AUTOSAR XML (schema 4-2-1)
# Copyright (c) 2017 Vector Informatik GmbH.
# License is restricted to the usage with CBD1800319 (D00) for MSR_Vector_SLP4.
# Please contact Vector Informatik whenever you need further information concerning the license conditions.
standard types defined: boolean, sint16, uint16, uint32, uint8
package /VehicleProject
  system System
package /TP
  lin tp config LIN00: communication-cluster=LIN00
    tp address TA_0x0001: tp-address=1
    tp address TA_0x0003: tp-address=3
    tp address TA_0x007E: tp-address=126
    tp-connections:
      data-pdu=MasterReq_Tp_oLIN00, lin-tp-n-sdu=MasterReq_oLIN00, multicast=TA_0x007E, receiver=[TN_0x0001_SRU3, TN_0x0003_LRU1], transmitter=TN_Master
      data-pdu=SlaveResp_Tp_oLIN00, flow-control=MasterReq_Tp_oLIN00, lin-tp-n-sdu=SlaveResp_SRU3_oLIN00, receiver=TN_Master, transmitter=TN_0x0001_SRU3
      data-pdu=SlaveResp_Tp_oLIN00, flow-control=MasterReq_Tp_oLIN00, lin-tp-n-sdu=SlaveResp_LRU1_oLIN00, receiver=TN_Master, transmitter=TN_0x0003_LRU1
      data-pdu=MasterReq_Tp_oLIN00, flow-control=SlaveResp_Tp_oLIN00, lin-tp-n-sdu=MasterReq_SRU3_oLIN00, receiver=TN_0x0001_SRU3, transmitter=TN_Master
      data-pdu=MasterReq_Tp_oLIN00, flow-control=SlaveResp_Tp_oLIN00, lin-tp-n-sdu=MasterReq_LRU1_oLIN00, receiver=TN_0x0003_LRU1, transmitter=TN_Master
    lin tp node TN_0x0001_SRU3: tp-address=TA_0x0001
    lin tp node TN_0x0003_LRU1: tp-address=TA_0x0003
    lin tp node TN_Master: connector=CN_LIN00
package /Cluster
  can cluster CAN00: protocol-name=CAN  # 180319-lh1-EP21P2P_P2P_CAN2-V09
    can physical channel CHNL: comm-connectors=CN_CAN00
      frame DIAG_DTCInfo_P2P_oCAN00: id 0x79E, from P2P, frame-length=7, can-addressing-mode=STANDARD
        pdu DIAG_DTCInfo_P2P_oCAN00: length=7, unused-bit-pattern=0
          signal DTCInfomationP2PHSC2_oDIAG_DTCInfo_P2P_oCAN00: start 0, 56 bit, opaque, init-value=7 x 0, base-type=uint8_7_iso_8859_1, compu {0..72057594037927935=RANGE}, transfer-property=PENDING  # DTC Infomation of P2P The length of DTC information signal is 7 bytes. Byte 0 is MSB (most significant byte), and Byte 6 is LSB (least significant byte). For each byte, Bit 7 is msb (most significant bit), and Bit 0 is lsb (least significant bit). Byte 0: Bit (7-4): DTC Serious Level Bit (3-0): Reserved Byte 1: Bit (7-0): Reserved Byte 2: Bit (7-0): DTCHighByte Byte 3: Bit (7-0): DTCLowByte Byte 4: Bit (7-0): DTCFailureTypeByte Byte 5: Bit 7: warningIndicatorRequested Bit 6: testNotCompletedThisOperationCycle Bit 5: testFailedSinceLastClear Bit 4: testNotCompletedSinceLastClear Bit 3: confirmedDTC Bit 2: pendingDTC Bit 1: testFailedThisOperationCycle Bit 0: testFailed Byte 6: Bit (7-0): DTC Type For more detail, please refer to SMTC 2 800 004.
      frame DIAG_FuncReq_HSC2_oCAN00: id 0x7DF, to P2P, frame-length=8, can-addressing-mode=STANDARD
        pdu DIAG_FuncReq_HSC2_oCAN00: length=8, unused-bit-pattern=0
          signal DiagnosticFuncAddrReq_h2_oDIAG_FuncReq_HSC2_oCAN00: start 0, 64 bit, opaque, init-value=8 x 0, base-type=uint8_8_iso_8859_1, compu {0..18446744073709551615=RANGE}, transfer-property=PENDING, to P2P  # Diagnostic functional address request
      frame DIAG_PhysReq_P2P_oCAN00: id 0x736, to P2P, frame-length=8, can-addressing-mode=STANDARD
        pdu DIAG_PhysReq_P2P_oCAN00: length=8, unused-bit-pattern=0
          signal DiagnosticReqP2P_h2_oDIAG_PhysReq_P2P_oCAN00: start 0, 64 bit, opaque, init-value=8 x 0, base-type=uint8_8_iso_8859_1, compu {0..18446744073709551615=RANGE}, transfer-property=PENDING, to P2P  # Diagnostic request to P2P
      frame DIAG_PhysResp_P2P_oCAN00: id 0x73E, from P2P, frame-length=8, can-addressing-mode=STANDARD
        pdu DIAG_PhysResp_P2P_oCAN00: length=8, unused-bit-pattern=0
          signal DiagnosticRespP2P_oDIAG_PhysResp_P2P_oCAN00: start 0, 64 bit, opaque, init-value=8 x 0, base-type=uint8_8_iso_8859_1, compu {0..18446744073709551615=RANGE}, transfer-property=PENDING  # Diagnostic response from P2P
      frame EHBS_HSC2_FrP00_oCAN00: id 0x1B6, to P2P, frame-length=8, can-addressing-mode=STANDARD
        pdu EHBS_HSC2_FrP00_oCAN00: length=8, transmission-mode-false-timing=cyclic-timing=time-period=0, transmission-mode-true-timing=cyclic-timing=time-period=0, unused-bit-pattern=0
          signal BrkPdlAppdHSC2_oEHBS_HSC2_FrP00_oCAN00: start 10, 1 bit, big-endian, init-value=0, base-type=boolean, compu {0..1=RANGE, 0=Cx0_brake_pedal_not_applied (brake pedal not applied), 1=Cx1_brake_pedal_applied (brake pedal applied)}, transfer-property=PENDING, to P2P
          signal HydBstrCmpstnReqHSC2_oEHBS_HSC2_FrP00_oCAN00: start 54, 1 bit, big-endian, init-value=0, base-type=boolean, compu {0..1=RANGE, 0=Cx0_HBC_inactive (HBC inactive), 1=Cx1_HBC_active (HBC active)}, transfer-property=PENDING, to P2P
      frame EPB_HSC2_FrP00_oCAN00: id 0x230, to P2P, frame-length=8, can-addressing-mode=STANDARD
        pdu EPB_HSC2_FrP00_oCAN00: length=8, transmission-mode-false-timing=cyclic-timing=time-period=0, transmission-mode-true-timing=cyclic-timing=time-period=0, unused-bit-pattern=0
          signal EPBSwStsVHSC2_oEPB_HSC2_FrP00_oCAN00: start 5, 1 bit, big-endian, init-value=0, base-type=boolean, compu {0..1=RANGE, 0=Cx0_Valid, 1=Cx1_Invalid}, transfer-property=PENDING, to P2P
          signal EPBSwStsHSC2_oEPB_HSC2_FrP00_oCAN00: start 7, 2 bit, big-endian, init-value=0, base-type=uint8, compu {0..3=RANGE, 0=Cx0_NotActive, 1=Cx1_Release, 2=Cx2_Apply}, transfer-property=PENDING, to P2P
      frame EPB_HSC2_FrP01_oCAN00: id 0x22A, to P2P, frame-length=2, can-addressing-mode=STANDARD
        pdu EPB_HSC2_FrP01_oCAN00: length=2, transmission-mode-false-timing=cyclic-timing=time-period=0, transmission-mode-true-timing=cyclic-timing=time-period=0, unused-bit-pattern=0
          signal EPBAvlblyStsPVHSC2_oEPB_HSC2_FrP01_oCAN00: start 2, 3 bit, big-endian, init-value=0, base-type=uint8, compu {0..7=RANGE, 0=Cx0_0x0_0x7_ ((0x0 - 0x7))}, transfer-property=PENDING, to P2P
          signal EPBAvlblyStsHSC2_oEPB_HSC2_FrP01_oCAN00: start 5, 3 bit, big-endian, init-value=0, base-type=uint8, compu {0..7=RANGE, 0=Cx0_Unavailable_Not_Failed (Unavailable,Not Failed), 1=Cx1_Available_Not_Failed (Available,Not Failed), 2=Cx2_Unavailable_Failed_Applied (Unavailable,Failed Applied), 3=Cx3_Unavailable_Failed_Released (Unavailable,Failed Released), 4=Cx4_Unavailable_Failed_other (Unavailable,Failed other)}, transfer-property=PENDING, to P2P
          signal EPBAppcnStsPVHSC2_oEPB_HSC2_FrP01_oCAN00: start 13, 2 bit, big-endian, init-value=0, base-type=uint8, compu {0..3=RANGE, 0=Cx0_0x0_0x3_ ((0x0 - 0x3))}, transfer-property=PENDING, to P2P  # Electric Park Brake Application Status Protection Value
          signal EPBAppcnStsHSC2_oEPB_HSC2_FrP01_oCAN00: start 15, 2 bit, big-endian, init-value=0, base-type=uint8, compu {0..3=RANGE, 0=Cx0_Unknown, 1=Cx1_Park_Brake_Applied (Park Brake Applied), 2=Cx2_Park_Brake_Released (Park Brake Released), 3=Cx3_Park_Brake_Application_in_Progress (Park Brake Application in Progress)}, transfer-property=PENDING, to P2P  # Electric Park Brake Application Status
      frame EPS_HSC2_FrP02_oCAN00: id 0x1B1, to P2P, frame-length=4, can-addressing-mode=STANDARD
        pdu EPS_HSC2_FrP02_oCAN00: length=4, transmission-mode-false-timing=cyclic-timing=time-period=0, transmission-mode-true-timing=cyclic-timing=time-period=0, unused-bit-pattern=0
          signal EPSAPAStsHSC2_oEPS_HSC2_FrP02_oCAN00: start 4, 4 bit, big-endian, init-value=7, base-type=uint8, compu {0..15=RANGE, 0=Cx0_Inhibit, 1=Cx1_Available, 2=Cx2_Active, 3=Cx3_Abort, 4=Cx4_Reply_for_Control (Reply for Control), 5=Cx5_NRCD_Active (NRCD Active), 6=Cx6_ADAS_Active (ADAS Active), 7=Cx7_Failure, 8=Cx8_Reserve_0x8_0xF_ (Reserve (0x8 - 0xF)); unit Reserve} "Source signal range: [8,15]", unit=Reserve, transfer-property=PENDING, to P2P
          signal EPSAPAInhHSC2_oEPS_HSC2_FrP02_oCAN00: start 15, 8 bit, big-endian, init-value=0, base-type=uint8, compu {0..255=RANGE, 0=Cx00_Normal_Operation (Normal Operation), 1=Cx01_Over_Speed (Over Speed), 2=Cx02_Driver_Interference (Driver Interference), 4=Cx04_Abnormal_CAN_input (Abnormal CAN input), 8=Cx08_Excess_Angle_Deviation (Excess Angle Deviation), 16=Cx10_EPS_failure (EPS failure), 32=Cx20_Reserve, 64=Cx40_Reserve, 128=Cx80_Reserve}, transfer-property=PENDING, to P2P
          signal EPSAPAAlvRCHSC2_oEPS_HSC2_FrP02_oCAN00: start 23, 8 bit, big-endian, init-value=0, base-type=uint8, compu {0..255=RANGE, 0=Cx00_0x0_0xFF_ ((0x0 - 0xFF))}, transfer-property=PENDING, to P2P
          signal EPSAPAChksmHSC2_oEPS_HSC2_FrP02_oCAN00: start 31, 8 bit, big-endian, init-value=0, base-type=uint8, compu {0..255=RANGE, 0=Cx00_0x0_0xFF_ ((0x0 - 0xFF))}, transfer-property=PENDING, to P2P
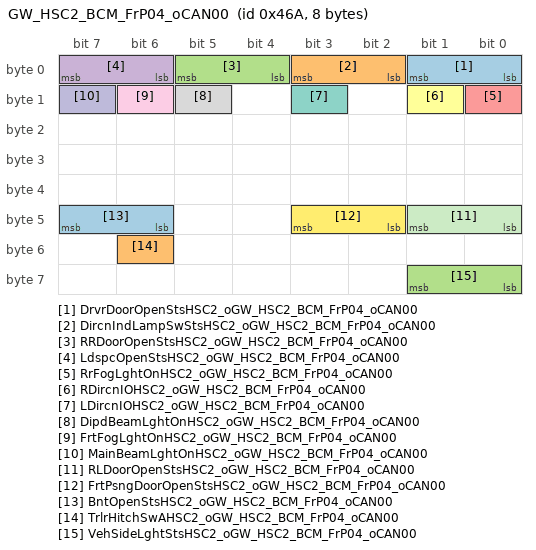
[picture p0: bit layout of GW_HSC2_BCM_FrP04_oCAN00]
      frame GW_HSC2_BCM_FrP04_oCAN00: id 0x46A, to P2P, frame-length=8, can-addressing-mode=STANDARD
        pdu GW_HSC2_BCM_FrP04_oCAN00: length=8, transmission-mode-false-timing=cyclic-timing=time-period=0, transmission-mode-true-timing=cyclic-timing=time-period=0, unused-bit-pattern=0
          signal DrvrDoorOpenStsHSC2_oGW_HSC2_BCM_FrP04_oCAN00: start 1, 2 bit, big-endian, init-value=0, base-type=uint8, compu {0..3=RANGE, 0=Cx0_Driver_Door_Closed (Driver Door Closed), 1=Cx1_Driver_Door_Open_For_latch_switch_can_t_detect_door_ajar_status_ (Driver Door Open(For latch switch can't detect door ajar status)), 2=Cx2_Driver_Door_Ajar (Driver Door Ajar), 3=Cx3_Driver_Door_Full_Open (Driver Door Full Open)}, transfer-property=PENDING, to P2P
          signal DircnIndLampSwStsHSC2_oGW_HSC2_BCM_FrP04_oCAN00: start 3, 2 bit, big-endian, init-value=0, base-type=uint8, compu {0..3=RANGE, 0=Cx0_off, 1=Cx1_Left_on (Left on), 2=Cx2_Right_on (Right on), 3=Cx3_reserve}, transfer-property=PENDING, to P2P
          signal RRDoorOpenStsHSC2_oGW_HSC2_BCM_FrP04_oCAN00: start 5, 2 bit, big-endian, init-value=0, base-type=uint8, compu {0..3=RANGE, 0=Cx0_Rear_Right_Door_Closed (Rear Right Door Closed), 1=Cx1_Rear_Right_Door_Open_latch_switch_cann_t_detect_door_ajar_status (Rear Right Door Open(latch switch cann't detect door ajar status), 2=Cx2_Rear_Right_Door_Ajar (Rear Right Door Ajar), 3=Cx3_Rear_Right_Door_Full_Open (Rear Right Door Full Open)}, transfer-property=PENDING, to P2P  # Rear Right Door Open Status
          signal LdspcOpenStsHSC2_oGW_HSC2_BCM_FrP04_oCAN00: start 7, 2 bit, big-endian, init-value=0, base-type=uint8, compu {0..3=RANGE, 0=Cx0_Load_Space_Closed (Load Space Closed), 1=Cx1_Load_Space_Open (Load Space Open), 2=Cx2_Reserved, 3=Cx3_Reserved}, transfer-property=PENDING, to P2P
          signal RrFogLghtOnHSC2_oGW_HSC2_BCM_FrP04_oCAN00: start 8, 1 bit, big-endian, init-value=0, base-type=boolean, compu {0..1=RANGE, 0=Cx0_False, 1=Cx1_True}, transfer-property=PENDING, to P2P
          signal RDircnIOHSC2_oGW_HSC2_BCM_FrP04_oCAN00: start 9, 1 bit, big-endian, init-value=0, base-type=boolean, compu {0..1=RANGE, 0=Cx0_False, 1=Cx1_True}, transfer-property=PENDING, to P2P
          signal LDircnIOHSC2_oGW_HSC2_BCM_FrP04_oCAN00: start 11, 1 bit, big-endian, init-value=0, base-type=boolean, compu {0..1=RANGE, 0=Cx0_False, 1=Cx1_True}, transfer-property=PENDING, to P2P
          signal DipdBeamLghtOnHSC2_oGW_HSC2_BCM_FrP04_oCAN00: start 13, 1 bit, big-endian, init-value=0, base-type=boolean, compu {0..1=RANGE, 0=Cx0_False, 1=Cx1_True}, transfer-property=PENDING, to P2P
          signal FrtFogLghtOnHSC2_oGW_HSC2_BCM_FrP04_oCAN00: start 14, 1 bit, big-endian, init-value=0, base-type=boolean, compu {0..1=RANGE, 0=Cx0_False, 1=Cx1_True}, transfer-property=PENDING, to P2P
          signal MainBeamLghtOnHSC2_oGW_HSC2_BCM_FrP04_oCAN00: start 15, 1 bit, big-endian, init-value=0, base-type=boolean, compu {0..1=RANGE, 0=Cx0_False, 1=Cx1_True}, transfer-property=PENDING, to P2P
          signal RLDoorOpenStsHSC2_oGW_HSC2_BCM_FrP04_oCAN00: start 41, 2 bit, big-endian, init-value=0, base-type=uint8, compu {0..3=RANGE, 0=Cx0_Rear_Left_Door_Closed (Rear Left Door Closed), 1=Cx1_Rear_Left_Door_Open_latch_switch_cann_t_detect_door_ajar_status (Rear Left Door Open(latch switch cann't detect door ajar status), 2=Cx2_Rear_Left_Door_Ajar (Rear Left Door Ajar), 3=Cx3_Rear_Left_Door_Full_Open (Rear Left Door Full Open)}, transfer-property=PENDING, to P2P
          signal FrtPsngDoorOpenStsHSC2_oGW_HSC2_BCM_FrP04_oCAN00: start 43, 2 bit, big-endian, init-value=0, base-type=uint8, compu {0..3=RANGE, 0=Cx0_Front_Passenger_Door_Closed (Front Passenger Door Closed), 1=Cx1_Front_Passenger_Open_latch_switch_cann_t_detect_door_ajar_statu (Front Passenger Open(latch switch cann¡®t detect door ajar statu), 2=Cx2_Front_Passenger_Door_Ajar (Front Passenger Door Ajar), 3=Cx3_Front_Passenger_Door_Full_Open (Front Passenger Door Full Open)}, transfer-property=PENDING, to P2P
          signal BntOpenStsHSC2_oGW_HSC2_BCM_FrP04_oCAN00: start 47, 2 bit, big-endian, init-value=0, base-type=uint8, compu {0..3=RANGE, 0=Cx0_Bonnet_Closed (Bonnet Closed), 1=Cx1_Bonnet_Open (Bonnet Open), 2=Cx2_Bonnet_Switch_Disconnect (Bonnet Switch Disconnect), 3=Cx3_Reserved}, transfer-property=PENDING, to P2P
          signal TrlrHitchSwAHSC2_oGW_HSC2_BCM_FrP04_oCAN00: start 54, 1 bit, big-endian, init-value=0, base-type=boolean, compu {0..1=RANGE, 0=Cx0_False, 1=Cx1_True}, transfer-property=PENDING, to P2P
          signal VehSideLghtStsHSC2_oGW_HSC2_BCM_FrP04_oCAN00: start 57, 2 bit, big-endian, init-value=0, base-type=uint8, compu {0..3=RANGE, 0=Cx0_No_side_light_on_ (No side light on), 1=Cx1_Left_side_light_on_only (Left side light on only), 2=Cx2_Right_side_light_on_only (Right side light on only), 3=Cx3_All_side_light_and_license_plate_light_on (All side light and license plate light on)}, transfer-property=PENDING, to P2P
      frame GW_HSC2_BCM_FrP06_oCAN00: id 0x21C, to P2P, frame-length=8, can-addressing-mode=STANDARD
        pdu GW_HSC2_BCM_FrP06_oCAN00: length=8, transmission-mode-false-timing=cyclic-timing=time-period=0, transmission-mode-true-timing=cyclic-timing=time-period=0, unused-bit-pattern=0
          signal BCMSSBFltStsHSC2_oGW_HSC2_BCM_FrP06_oCAN00: start 7, 3 bit, big-endian, init-value=0, base-type=uint8, compu {0..7=RANGE, 0=Cx0_No_Fault (No Fault), 1=Cx1_short_to_GND (short to GND), 2=Cx2_short_to_Battery (short to Battery), 3=Cx3_Stuck, 4=Cx4_Open_Circuit (Open Circuit), 5=Cx5_switch_failed (switch failed), 6=Cx6_Reserved, 7=Cx7_Reserved}, transfer-property=PENDING, to P2P
          signal DayTimeRunningLampOnHSC2_oGW_HSC2_BCM_FrP06_oCAN00: start 29, 1 bit, big-endian, init-value=0, base-type=boolean, compu {0..1=RANGE, 0=Cx0_False, 1=Cx1_True}, transfer-property=PENDING, to P2P
      frame GW_HSC2_BCM_FrP07_oCAN00: id 0x1F2, to P2P, frame-length=2, can-addressing-mode=STANDARD
        pdu GW_HSC2_BCM_FrP07_oCAN00: length=2, transmission-mode-false-timing=cyclic-timing=time-period=0, transmission-mode-true-timing=cyclic-timing=time-period=0, unused-bit-pattern=0
          signal BCMSSBAHSC2_oGW_HSC2_BCM_FrP07_oCAN00: start 0, 1 bit, big-endian, init-value=0, base-type=boolean, compu {0..1=RANGE, 0=Cx0_Inactive, 1=Cx1_Active_}, transfer-property=PENDING, to P2P
          signal BCMSSBAVHSC2_oGW_HSC2_BCM_FrP07_oCAN00: start 1, 1 bit, big-endian, init-value=0, base-type=boolean, compu {0..1=RANGE, 0=Cx0_Valid, 1=Cx1_Invalid}, transfer-property=PENDING, to P2P
          signal PwrMdAutoCtrlAvlblHSC2_oGW_HSC2_BCM_FrP07_oCAN00: start 2, 1 bit, big-endian, init-value=0, base-type=boolean, compu {0..1=RANGE, 0=Cx0_unavailable, 1=Cx1_available}, transfer-property=PENDING, to P2P
          signal SysBPMHSC2_oGW_HSC2_BCM_FrP07_oCAN00: start 5, 2 bit, big-endian, init-value=0, base-type=uint8, compu {0..3=RANGE, 0=Cx0_Off, 1=Cx1_ACC, 2=Cx2_Run, 3=Cx3_Crank_Request (Crank Request)}, transfer-property=PENDING, to P2P
          signal SysBPMEnbdHSC2_oGW_HSC2_BCM_FrP07_oCAN00: start 6, 1 bit, big-endian, init-value=0, base-type=boolean, compu {0..1=RANGE, 0=Cx0_False, 1=Cx1_True}, transfer-property=PENDING, to P2P
      frame GW_HSC2_BCM_FrS16_oCAN00: id 0x603, to P2P, frame-length=8, can-addressing-mode=STANDARD
        pdu GW_HSC2_BCM_FrS16_oCAN00: length=8, unused-bit-pattern=0
          signal BCMToIECURmtCtrlPotclHSC2_oGW_HSC2_BCM_FrS16_oCAN00: start 0, 64 bit, opaque, init-value=8 x 0, base-type=uint8_8_iso_8859_1, compu {0..18446744073709551615=RANGE}, transfer-property=PENDING, to P2P
      frame GW_HSC2_ECM_FrP04_oCAN00: id 0x194, to P2P, frame-length=8, can-addressing-mode=STANDARD
        pdu GW_HSC2_ECM_FrP04_oCAN00: length=8, transmission-mode-false-timing=cyclic-timing=time-period=0, transmission-mode-true-timing=cyclic-timing=time-period=0, unused-bit-pattern=0
          signal TrShftLvrPos_h1HSC2_oGW_HSC2_ECM_FrP04_oCAN00: start 27, 4 bit, big-endian, init-value=0, base-type=uint8, compu {0..15=RANGE, 0=Cx0_Between_Ranges (Between Ranges), 1=Cx1_Park_Range (Park Range), 2=Cx2_Reverse_Range (Reverse Range), 3=Cx3_Neutral_Range (Neutral Range), 4=Cx4_Forward_Range_A (Forward Range A), 5=Cx5_Forward_Range_B (Forward Range B), 6=Cx6_Forward_Range_C (Forward Range C), 7=Cx7_Forward_Range_D (Forward Range D), 8=Cx8_Forward_Range_E (Forward Range E), 9=Cx9_Forward_Range_F (Forward Range F), 10=CxA_Forward_Range_G (Forward Range G), 11=CxB_Forward_Range_H (Forward Range H), 15=CxF_Lever_Position_Unknown (Lever Position Unknown)}, transfer-property=PENDING, to P2P
          signal TrShftLvrPosV_h1HSC2_oGW_HSC2_ECM_FrP04_oCAN00: start 28, 1 bit, big-endian, init-value=0, base-type=boolean, compu {0..1=RANGE, 0=Cx0_Valid, 1=Cx1_Invalid}, transfer-property=PENDING, to P2P
      frame GW_HSC2_FICM_FrP02_oCAN00: id 0x376, to P2P, frame-length=8, can-addressing-mode=STANDARD
        pdu GW_HSC2_FICM_FrP02_oCAN00: length=8, transmission-mode-false-timing=cyclic-timing=time-period=0, transmission-mode-true-timing=cyclic-timing=time-period=0, unused-bit-pattern=0
          signal DrvrSelAPAParkngMdHSC2_oGW_HSC2_FICM_FrP02_oCAN00: start 10, 3 bit, big-endian, init-value=0, base-type=uint8, compu {0..7=RANGE, 0=Cx0_No_select (No select), 1=Cx1_Select_parallel_parking (Select parallel parking), 2=Cx2_Select_perpendicular_parking (Select perpendicular parking), 3=Cx3_Select_park_in (Select park in), 4=Cx4_Select_park_out (Select park out), 5=Cx5_Reserved, 6=Cx6_Reserved, 7=Cx7_Reserved}, transfer-property=PENDING, to P2P  # Driver Select Advanced Park Assist Parking Mode
          signal DrvrSelAPASlotBearngHSC2_oGW_HSC2_FICM_FrP02_oCAN00: start 12, 2 bit, big-endian, init-value=0, base-type=uint8, compu {0..3=RANGE, 0=Cx0_No_select (No select), 1=Cx1_Select_Left_slot (Select Left slot), 2=Cx2_Select_Right_slot (Select Right slot), 3=Cx3_Reserved}, transfer-property=PENDING, to P2P
          signal RstrFctryDeftsReqHSC2_oGW_HSC2_FICM_FrP02_oCAN00: start 56, 1 bit, big-endian, init-value=0, base-type=boolean, compu {0..1=RANGE, 0=Cx0_False, 1=Cx1_True}, transfer-property=PENDING, to P2P
      frame GW_HSC2_FICM_FrP08_oCAN00: id 0x2F6, to P2P, frame-length=8, can-addressing-mode=STANDARD
        pdu GW_HSC2_FICM_FrP08_oCAN00: length=8, transmission-mode-false-timing=cyclic-timing=time-period=0, transmission-mode-true-timing=cyclic-timing=time-period=0, unused-bit-pattern=0
          signal APASwReqHSC2_oGW_HSC2_FICM_FrP08_oCAN00: start 59, 2 bit, big-endian, init-value=0, base-type=uint8, compu {0..3=RANGE, 0=Cx0_No_request (No request), 1=Cx1_Short_press (Short press), 2=Cx2_Long_press (Long press), 3=Cx3_Reserved}, transfer-property=PENDING, to P2P
          signal PDCSwReqHSC2_oGW_HSC2_FICM_FrP08_oCAN00: start 61, 2 bit, big-endian, init-value=0, base-type=uint8, compu {0..3=RANGE, 0=Cx0_No_request (No request), 1=Cx1_Short_press (Short press), 2=Cx2_Long_press (Long press), 3=Cx3_Reserved}, transfer-property=PENDING, to P2P
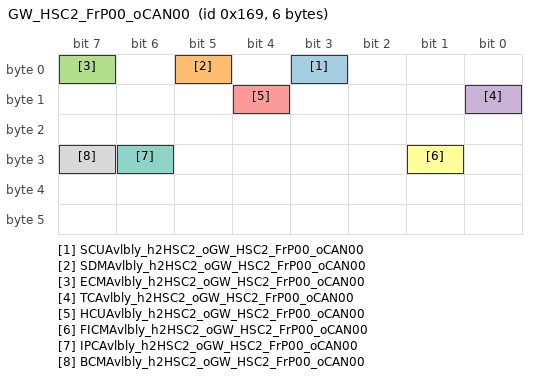
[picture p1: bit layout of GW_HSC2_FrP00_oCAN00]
      frame GW_HSC2_FrP00_oCAN00: id 0x169, to P2P, frame-length=6, can-addressing-mode=STANDARD
        pdu GW_HSC2_FrP00_oCAN00: length=6, transmission-mode-false-timing=cyclic-timing=time-period=0, transmission-mode-true-timing=cyclic-timing=time-period=0, unused-bit-pattern=0
          signal SCUAvlbly_h2HSC2_oGW_HSC2_FrP00_oCAN00: start 3, 1 bit, big-endian, init-value=0, base-type=boolean, compu {0..1=RANGE, 0=Cx0_False, 1=Cx1_True}, transfer-property=PENDING, to P2P
          signal SDMAvlbly_h2HSC2_oGW_HSC2_FrP00_oCAN00: start 5, 1 bit, big-endian, init-value=0, base-type=boolean, compu {0..1=RANGE, 0=Cx0_False, 1=Cx1_True}, transfer-property=PENDING, to P2P
          signal ECMAvlbly_h2HSC2_oGW_HSC2_FrP00_oCAN00: start 7, 1 bit, big-endian, init-value=0, base-type=boolean, compu {0..1=RANGE, 0=Cx0_False, 1=Cx1_True}, transfer-property=PENDING, to P2P
          signal TCAvlbly_h2HSC2_oGW_HSC2_FrP00_oCAN00: start 8, 1 bit, big-endian, init-value=0, base-type=boolean, compu {0..1=RANGE, 0=Cx0_False, 1=Cx1_True}, transfer-property=PENDING, to P2P  # TC Available Detect if specific ECU is available according to node missing strategy by gateway ECU.
          signal HCUAvlbly_h2HSC2_oGW_HSC2_FrP00_oCAN00: start 12, 1 bit, big-endian, init-value=0, base-type=boolean, compu {0..1=RANGE, 0=Cx0_False, 1=Cx1_True}, transfer-property=PENDING, to P2P  # HCU Available Detect if specific ECU is available according to node missing strategy by gateway ECU.
          signal FICMAvlbly_h2HSC2_oGW_HSC2_FrP00_oCAN00: start 25, 1 bit, big-endian, init-value=0, base-type=boolean, compu {0..1=RANGE, 0=Cx0_False, 1=Cx1_True}, transfer-property=PENDING, to P2P
          signal IPCAvlbly_h2HSC2_oGW_HSC2_FrP00_oCAN00: start 30, 1 bit, big-endian, init-value=0, base-type=boolean, compu {0..1=RANGE, 0=Cx0_False, 1=Cx1_True}, transfer-property=PENDING, to P2P
          signal BCMAvlbly_h2HSC2_oGW_HSC2_FrP00_oCAN00: start 31, 1 bit, big-endian, init-value=0, base-type=boolean, compu {0..1=RANGE, 0=Cx0_False, 1=Cx1_True}, transfer-property=PENDING, to P2P
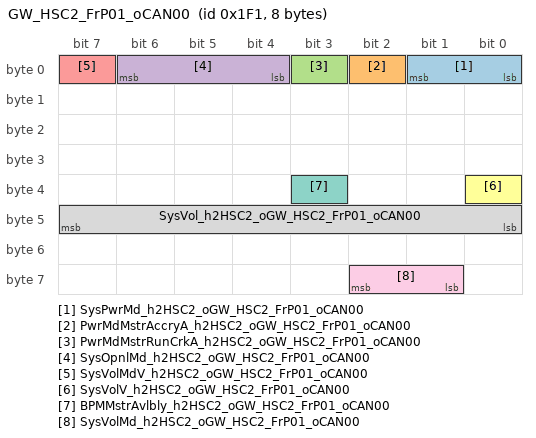
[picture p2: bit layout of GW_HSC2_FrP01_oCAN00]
      frame GW_HSC2_FrP01_oCAN00: id 0x1F1, to P2P, frame-length=8, can-addressing-mode=STANDARD
        pdu GW_HSC2_FrP01_oCAN00: length=8, transmission-mode-false-timing=cyclic-timing=time-period=0, transmission-mode-true-timing=cyclic-timing=time-period=0, unused-bit-pattern=0
          signal SysPwrMd_h2HSC2_oGW_HSC2_FrP01_oCAN00: start 1, 2 bit, big-endian, init-value=0, base-type=uint8, compu {0..3=RANGE, 0=Cx0_Off, 1=Cx1_Accessory, 2=Cx2_Run, 3=Cx3_Crank_Request (Crank Request)}, transfer-property=PENDING, to P2P
          signal PwrMdMstrAccryA_h2HSC2_oGW_HSC2_FrP01_oCAN00: start 2, 1 bit, big-endian, init-value=0, base-type=boolean, compu {0..1=RANGE, 0=Cx0_Inactive, 1=Cx1_Active}, transfer-property=PENDING, to P2P
          signal PwrMdMstrRunCrkA_h2HSC2_oGW_HSC2_FrP01_oCAN00: start 3, 1 bit, big-endian, init-value=0, base-type=boolean, compu {0..1=RANGE, 0=Cx0_Inactive, 1=Cx1_Active}, transfer-property=PENDING, to P2P
          signal SysOpnlMd_h2HSC2_oGW_HSC2_FrP01_oCAN00: start 6, 3 bit, big-endian, init-value=0, base-type=uint8, compu {0..7=RANGE, 0=Cx0_Normal_Mode (Normal Mode), 1=Cx1_Manufacturing_Mode (Manufacturing Mode), 2=Cx2_Transit_Mode (Transit Mode), 3=Cx3_Show_Room_Reserve_ (Show Room(Reserve)), 4=Cx4_Storage_Mode (Storage Mode), 5=Cx5_Diagnosic_or_Reprogramming_Reserve_ (Diagnosic or Reprogramming(Reserve))}, transfer-property=PENDING, to P2P
          signal SysVolMdV_h2HSC2_oGW_HSC2_FrP01_oCAN00: start 7, 1 bit, big-endian, init-value=0, base-type=boolean, compu {0..1=RANGE, 0=Cx0_Valid, 1=Cx1_Invalid}, transfer-property=PENDING, to P2P
          signal SysVolV_h2HSC2_oGW_HSC2_FrP01_oCAN00: start 32, 1 bit, big-endian, init-value=0, base-type=boolean, compu {0..1=RANGE, 0=Cx0_Valid, 1=Cx1_Invalid}, transfer-property=PENDING, to P2P
          signal BPMMstrAvlbly_h2HSC2_oGW_HSC2_FrP01_oCAN00: start 35, 1 bit, big-endian, init-value=0, base-type=boolean, compu {0..1=RANGE, 0=Cx0_False, 1=Cx1_True}, transfer-property=PENDING, to P2P
          signal SysVol_h2HSC2_oGW_HSC2_FrP01_oCAN00: start 47, 8 bit, big-endian, init-value=0, base-type=uint8, compu {0=Cx00_V_0x0_0xFF_ (V (0x0 - 0xFF)), phys=raw*0.1+3 for raw 0..255; unit V}, unit=V, transfer-property=PENDING, to P2P
          signal SysVolMd_h2HSC2_oGW_HSC2_FrP01_oCAN00: start 58, 2 bit, big-endian, init-value=0, base-type=uint8, compu {0..3=RANGE, 0=Cx0_Normal, 1=Cx1_Low_System_Voltage (Low System Voltage), 2=Cx2_High_System_Voltage (High System Voltage), 3=Cx3_Illegal_System_Voltage (Illegal System Voltage)}, transfer-property=PENDING, to P2P
      frame GW_HSC2_FrP08_oCAN00: id 0x540, to P2P, frame-length=8, can-addressing-mode=STANDARD
        pdu GW_HSC2_FrP08_oCAN00: length=8, transmission-mode-false-timing=cyclic-timing=time-period=0, transmission-mode-true-timing=cyclic-timing=time-period=0, unused-bit-pattern=0
          signal VehOdo_h2HSC2_oGW_HSC2_FrP08_oCAN00: start 7, 24 bit, big-endian, init-value=0, base-type=uint32, compu {0..16777200=RANGE, 0=Cx000000_0x0_0xFFFFFF_ ((0x0 - 0xFFFFFF))}, transfer-property=PENDING, to P2P
          signal VehOdoV_h2HSC2_oGW_HSC2_FrP08_oCAN00: start 31, 1 bit, big-endian, init-value=0, base-type=boolean, compu {0..1=RANGE, 0=Cx0_Valid, 1=Cx1_Invalid}, transfer-property=PENDING, to P2P
      frame GW_HSC2_FrP10_oCAN00: id 0x3F1, to P2P, frame-length=8, can-addressing-mode=STANDARD
        pdu GW_HSC2_FrP10_oCAN00: length=8, transmission-mode-false-timing=cyclic-timing=time-period=0, transmission-mode-true-timing=cyclic-timing=time-period=0, unused-bit-pattern=0
          signal OtsdAirTemCrValV_h2HSC2_oGW_HSC2_FrP10_oCAN00: start 48, 1 bit, big-endian, init-value=0, base-type=boolean, compu {0..1=RANGE, 0=Cx0_Valid, 1=Cx1_Invalid}, transfer-property=PENDING, to P2P
          signal OtsdAirTemCrValMsk_h2HSC2_oGW_HSC2_FrP10_oCAN00: start 51, 1 bit, big-endian, init-value=0, base-type=boolean, compu {0..1=RANGE, 0=Cx0_Don_t_Use_Data (Don't Use Data), 1=Cx1_Use_Data (Use Data)}, transfer-property=PENDING, to P2P
          signal OtsdAirTemCrVal_h2HSC2_oGW_HSC2_FrP10_oCAN00: start 63, 8 bit, big-endian, init-value=0, base-type=uint8, compu {0=Cx00_degC_0x0_0xFF_ (degC (0x0 - 0xFF)), phys=raw*0.5-40 for raw 0..255; unit degC}, unit=degC, transfer-property=PENDING, to P2P
      frame GW_HSC2_FrP13_oCAN00: id 0x1A9, to P2P, frame-length=8, can-addressing-mode=STANDARD
        pdu GW_HSC2_FrP13_oCAN00: length=8, transmission-mode-false-timing=cyclic-timing=time-period=0, transmission-mode-true-timing=cyclic-timing=time-period=0, unused-bit-pattern=0
          signal NRCDSts_h2HSC2_oGW_HSC2_FrP13_oCAN00: start 39, 2 bit, big-endian, init-value=0, base-type=uint8, compu {0..3=RANGE, 0=Cx0_Inactive, 1=Cx1_NRCD_Active (NRCD Active), 2=Cx2_Semiautomatic_Parking_Assistant_Active (Semiautomatic Parking Assistant Active), 3=Cx3_Fully_APA_Active (Fully-APA Active)}, transfer-property=PENDING, to P2P
          signal APACtrlAbotdRsnHSC2_oGW_HSC2_FrP13_oCAN00: start 47, 4 bit, big-endian, init-value=0, base-type=uint8, compu {0..15=RANGE, 0=Cx0_No_Aborted (No Aborted), 1=Cx1_Driver_interference_SCU (Driver interference SCU), 2=Cx2_Driver_interference_Braking_System (Driver interference Braking System), 3=Cx3_Charger_is_connected (Charger is connected), 4=Cx4_Communication_Error (Communication Error), 5=Cx5_In_post_collision (In post collision), 6=Cx6_Energy_Low (Energy Low), 7=Cx7_Gradient_over_threshold (Gradient over threshold), 8=Cx8_Crank_Failed (Crank Failed), 9=Cx9_Reserve, 10=CxA_Reserve, 11=CxB_Reserve, 12=CxC_Reserve, 13=CxD_Reserve, 14=CxE_Reserve, 15=CxF_Unknown_Reason (Unknown Reason)}, transfer-property=PENDING, to P2P
      frame GW_HSC2_FrS00_oCAN00: id 0x6A3, to P2P, frame-length=8, can-addressing-mode=STANDARD
        pdu GW_HSC2_FrS00_oCAN00: length=8, unused-bit-pattern=0
          signal NRCDMstrChlg_h2HSC2_oGW_HSC2_FrS00_oCAN00: start 0, 64 bit, opaque, init-value=8 x 0, base-type=uint8_8_iso_8859_1, compu {0=RANGE, 0=Cx0000000000000000_0x0_0xFFFFFFFF_ ((0x0 - 0xFFFFFFFF))}, transfer-property=PENDING, to P2P
      frame GW_HSC2_HCU_FrP00_oCAN00: id 0xAF, to P2P, frame-length=8, can-addressing-mode=STANDARD
        pdu GW_HSC2_HCU_FrP00_oCAN00: length=8, transmission-mode-false-timing=cyclic-timing=time-period=0, transmission-mode-true-timing=cyclic-timing=time-period=0, unused-bit-pattern=0
          signal EPTAccelActuPosHSC2_oGW_HSC2_HCU_FrP00_oCAN00: start 7, 8 bit, big-endian, init-value=0, base-type=uint8, compu {0=Cx00_0x0_0xFF_ (% (0x0 - 0xFF)), phys=raw*0.392157 for raw 0..254; unit %}, unit=%, transfer-property=PENDING, to P2P
          signal EPTBrkPdlDscrtInptStsVHSC2_oGW_HSC2_HCU_FrP00_oCAN00: start 16, 1 bit, big-endian, init-value=1, base-type=boolean, compu {0..1=RANGE, 0=Cx0_Valid, 1=Cx1_Invalid}, transfer-property=PENDING, to P2P  # Electric Powertrain Brake Pedal Discrete Input Status Validity
          signal EPTStCmdOn_h1HSC2_oGW_HSC2_HCU_FrP00_oCAN00: start 17, 1 bit, big-endian, init-value=0, base-type=boolean, compu {0..1=RANGE, 0=Cx0_False, 1=Cx1_True}, transfer-property=PENDING, to P2P
          signal EPTBrkPdlDscrtInptStsHSC2_oGW_HSC2_HCU_FrP00_oCAN00: start 31, 1 bit, big-endian, init-value=0, base-type=boolean, compu {0..1=RANGE, 0=Cx0_Brake_Not_Applied (Brake Not Applied), 1=Cx1_Brake_Applied (Brake Applied)}, transfer-property=PENDING, to P2P
          signal EPTAccelActuPosVHSC2_oGW_HSC2_HCU_FrP00_oCAN00: start 43, 1 bit, big-endian, init-value=0, base-type=boolean, compu {0..1=RANGE, 0=Cx0_Valid, 1=Cx1_Invalid}, transfer-property=PENDING, to P2P
      frame GW_HSC2_HCU_FrP01_oCAN00: id 0x196, to P2P, frame-length=8, can-addressing-mode=STANDARD
        pdu GW_HSC2_HCU_FrP01_oCAN00: length=8, transmission-mode-false-timing=cyclic-timing=time-period=0, transmission-mode-true-timing=cyclic-timing=time-period=0, unused-bit-pattern=0
          signal EPTRdy_h1HSC2_oGW_HSC2_HCU_FrP01_oCAN00: start 38, 1 bit, big-endian, init-value=0, base-type=boolean, compu {0..1=RANGE, 0=Cx0_Not_ready (Not ready), 1=Cx1_Ready}, transfer-property=PENDING, to P2P
      frame GW_HSC2_HCU_FrP13_oCAN00: id 0x19C, to P2P, frame-length=8, can-addressing-mode=STANDARD
        pdu GW_HSC2_HCU_FrP13_oCAN00: length=8, transmission-mode-false-timing=cyclic-timing=time-period=0, transmission-mode-true-timing=cyclic-timing=time-period=0, unused-bit-pattern=0
          signal VCUNRCDAvlblHSC2_oGW_HSC2_HCU_FrP13_oCAN00: start 52, 1 bit, big-endian, init-value=0, base-type=boolean, compu {0..1=RANGE, 0=Cx0_Unavailable, 1=Cx1_Available}, transfer-property=PENDING, to P2P
          signal VCUAccReqStsHSC2_oGW_HSC2_HCU_FrP13_oCAN00: start 53, 1 bit, big-endian, init-value=0, base-type=boolean, compu {0..1=RANGE, 0=Cx0_No_Request (No Request), 1=Cx1_Request}, transfer-property=PENDING, to P2P
          signal VCUAccReqValHSC2_oGW_HSC2_HCU_FrP13_oCAN00: start 63, 8 bit, big-endian, init-value=0, base-type=uint8, compu {0=Cx00_0x0_0xFF_ ((0x0 - 0xFF)), phys=raw*0.1-12.7 for raw 0..255}, transfer-property=PENDING, to P2P
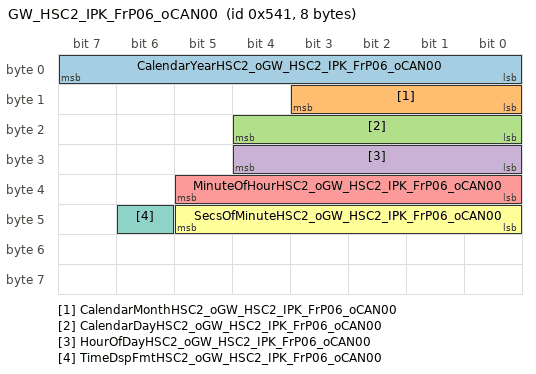
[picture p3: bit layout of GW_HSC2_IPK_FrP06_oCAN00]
      frame GW_HSC2_IPK_FrP06_oCAN00: id 0x541, to P2P, frame-length=8, can-addressing-mode=STANDARD
        pdu GW_HSC2_IPK_FrP06_oCAN00: length=8, transmission-mode-false-timing=cyclic-timing=time-period=0, transmission-mode-true-timing=cyclic-timing=time-period=0, unused-bit-pattern=0
          signal CalendarYearHSC2_oGW_HSC2_IPK_FrP06_oCAN00: start 7, 8 bit, big-endian, init-value=0, base-type=uint8, compu {0=Cx00_year_0x0_0xFF_ (year (0x0 - 0xFF)), phys=raw+2000 for raw 0..255; unit year}, unit=year, transfer-property=PENDING, to P2P
          signal CalendarMonthHSC2_oGW_HSC2_IPK_FrP06_oCAN00: start 11, 4 bit, big-endian, init-value=0, base-type=uint8, compu {0..15=RANGE, 0=Cx0_Unknown, 1=Cx1_January, 2=Cx2_February, 3=Cx3_March, 4=Cx4_April, 5=Cx5_May, 6=Cx6_June, 7=Cx7_July, 8=Cx8_August, 9=Cx9_September, 10=CxA_October, 11=CxB_November, 12=CxC_December}, transfer-property=PENDING, to P2P
          signal CalendarDayHSC2_oGW_HSC2_IPK_FrP06_oCAN00: start 20, 5 bit, big-endian, init-value=0, base-type=uint8, compu {0..31=RANGE, 0=Cx00_days_0x0_0x1F_ (days (0x0 - 0x1F)); unit days}, unit=days, transfer-property=PENDING, to P2P
          signal HourOfDayHSC2_oGW_HSC2_IPK_FrP06_oCAN00: start 28, 5 bit, big-endian, init-value=0, base-type=uint8, compu {0..23=RANGE, 0=Cx00_0x0_0x17_ ((0x0 - 0x17))}, transfer-property=PENDING, to P2P
          signal MinuteOfHourHSC2_oGW_HSC2_IPK_FrP06_oCAN00: start 37, 6 bit, big-endian, init-value=0, base-type=uint8, compu {0..59=RANGE, 0=Cx00_0x0_0x3B_ ((0x0 - 0x3B))}, transfer-property=PENDING, to P2P
          signal SecsOfMinuteHSC2_oGW_HSC2_IPK_FrP06_oCAN00: start 45, 6 bit, big-endian, init-value=0, base-type=uint8, compu {0..59=RANGE, 0=Cx00_0x0_0x3B_ ((0x0 - 0x3B))}, transfer-property=PENDING, to P2P
          signal TimeDspFmtHSC2_oGW_HSC2_IPK_FrP06_oCAN00: start 46, 1 bit, big-endian, init-value=0, base-type=boolean, compu {0..1=RANGE, 0=Cx0_12_hour_mode (12 hour mode), 1=Cx1_24_hour_mode (24 hour mode)}, transfer-property=PENDING, to P2P
      frame GW_HSC2_SCU_FrP00_oCAN00: id 0x9D, to P2P, frame-length=8, can-addressing-mode=STANDARD
        pdu GW_HSC2_SCU_FrP00_oCAN00: length=8, transmission-mode-false-timing=cyclic-timing=time-period=0, transmission-mode-true-timing=cyclic-timing=time-period=0, unused-bit-pattern=0
          signal SCUDrvrIntrvnAHSC2_oGW_HSC2_SCU_FrP00_oCAN00: start 2, 1 bit, big-endian, init-value=0, base-type=boolean, compu {0..1=RANGE, 0=Cx0_Inactive, 1=Cx1_Active}, transfer-property=PENDING, to P2P
          signal SCUNRCDAvlblHSC2_oGW_HSC2_SCU_FrP00_oCAN00: start 3, 1 bit, big-endian, init-value=0, base-type=boolean, compu {0..1=RANGE, 0=Cx0_Unavailable, 1=Cx1_Available}, transfer-property=PENDING, to P2P
          signal SCUShifterPosRCHSC2_oGW_HSC2_SCU_FrP00_oCAN00: start 11, 4 bit, big-endian, init-value=0, base-type=uint8, compu {0..15=RANGE, 0=Cx0_0x0_0xF_ ((0x0 - 0xF))}, transfer-property=PENDING, to P2P
          signal SCUShifterLvrPosHSC2_oGW_HSC2_SCU_FrP00_oCAN00: start 23, 4 bit, big-endian, init-value=0, base-type=uint8, compu {0..15=RANGE, 0=Cx0_SCU_Initialization (SCU Initialization), 1=Cx1_S_Sport_mode_ (S(Sport mode)), 2=Cx2_W_Winter_mode_ (W(Winter mode)), 3=Cx3_M_Manual_mode_ (M(Manual mode)), 5=Cx5_D_Drive_ (D(Drive)), 6=Cx6_N_Neutral_ (N(Neutral)), 7=Cx7_R_Reverse_ (R(Reverse)), 8=Cx8_P_Park_ (P(Park)), 10=CxA_Error}, transfer-property=PENDING, to P2P
          signal SCUShifterPosInvsnHSC2_oGW_HSC2_SCU_FrP00_oCAN00: start 31, 4 bit, big-endian, init-value=15, base-type=uint8, compu {0..15=RANGE, 5=Cx5_Error, 6=Cx6_Reserved, 7=Cx7_P_Park_ (P(Park)), 8=Cx8_R_Reverse_ (R (Reverse)), 9=Cx9_N_Neutral_ (N (Neutral)), 10=CxA_D_Drive_ (D (Drive)), 11=CxB_Reserved, 12=CxC_M_Manual_mode_ (M(Manual mode)), 13=CxD_W_Winter_mode_ (W(Winter mode)), 14=CxE_S_Sport_mode_ (S(Sport mode)), 15=CxF_SCU_initialization (SCU initialization)}, transfer-property=PENDING, to P2P
      frame GW_HSC2_SDM_FrP00_oCAN00: id 0x163, to P2P, frame-length=8, can-addressing-mode=STANDARD
        pdu GW_HSC2_SDM_FrP00_oCAN00: length=8, transmission-mode-false-timing=cyclic-timing=time-period=0, transmission-mode-true-timing=cyclic-timing=time-period=0, unused-bit-pattern=0
          signal AirbagDplInvsnHSC2_oGW_HSC2_SDM_FrP00_oCAN00: start 10, 1 bit, big-endian, init-value=1, base-type=boolean, compu {0..1=RANGE, 0=Cx0_Airbag_Deployed (Airbag Deployed), 1=Cx1_No_Airbag_Deployed (No Airbag Deployed)}, transfer-property=PENDING, to P2P  # Airbag Deployed Inversion
          signal AirbagDplHSC2_oGW_HSC2_SDM_FrP00_oCAN00: start 11, 1 bit, big-endian, init-value=0, base-type=boolean, compu {0..1=RANGE, 0=Cx0_False, 1=Cx1_True}, transfer-property=PENDING, to P2P
          signal DrvrSbltAtcHSC2_oGW_HSC2_SDM_FrP00_oCAN00: start 12, 1 bit, big-endian, init-value=0, base-type=boolean, compu {0..1=RANGE, 0=Cx0_False, 1=Cx1_True}, transfer-property=PENDING, to P2P
          signal DrvrSbltAtcVHSC2_oGW_HSC2_SDM_FrP00_oCAN00: start 13, 1 bit, big-endian, init-value=0, base-type=boolean, compu {0..1=RANGE, 0=Cx0_Valid, 1=Cx1_Invalid}, transfer-property=PENDING, to P2P
      frame P2P_DIAG_DTCInfo_APA_oCAN00: id 0x799, from P2P, frame-length=7, can-addressing-mode=STANDARD
        pdu P2P_DIAG_DTCInfo_APA_oCAN00: length=7, unused-bit-pattern=0
          signal DTCInfomationAPAHSC2_oP2P_DIAG_DTCInfo_APA_oCAN00: start 0, 56 bit, opaque, init-value=7 x 0, base-type=uint8_7_iso_8859_1, compu {0..72057594037927935=RANGE}, transfer-property=PENDING  # DTC Infomation of APA The length of DTC information signal is 7 bytes. Byte 0 is MSB (most significant byte), and Byte 6 is LSB (least significant byte). For each byte, Bit 7 is msb (most significant bit), and Bit 0 is lsb (least significant bit). Byte 0: Bit (7-4): DTC Serious Level Bit (3-0): Reserved Byte 1: Bit (7-0): Reserved Byte 2: Bit (7-0): DTCHighByte Byte 3: Bit (7-0): DTCLowByte Byte 4: Bit (7-0): DTCFailureTypeByte Byte 5: Bit 7: warningIndicatorRequested Bit 6: testNotCompletedThisOperationCycle Bit 5: testFailedSinceLastClear Bit 4: testNotCompletedSinceLastClear Bit 3: confirmedDTC Bit 2: pendingDTC Bit 1: testFailedThisOperationCycle Bit 0: testFailed Byte 6: Bit (7-0): DTC Type For more detail, please refer to SMTC 2 800 004.
      frame P2P_HSC2_FrP00_oCAN00: id 0x1A8, from P2P, frame-length=6, can-addressing-mode=STANDARD
        pdu P2P_HSC2_FrP00_oCAN00: length=6, transmission-mode-false-timing=cyclic-timing=time-period=0, transmission-mode-true-timing=cyclic-timing=time-period=0, unused-bit-pattern=0
          signal APAToqReqValHSC2_oP2P_HSC2_FrP00_oCAN00: start 3, 12 bit, big-endian, init-value=0, base-type=uint16, compu {0=Cx000_Nm_0x0_0xFFF_ (Nm (0x0 - 0xFFF)), phys=raw*0.5-848 for raw 0..4095; unit Nm}, unit=Nm, transfer-property=PENDING
          signal APAToqReqStsHSC2_oP2P_HSC2_FrP00_oCAN00: start 4, 1 bit, big-endian, init-value=0, base-type=boolean, compu {0..1=RANGE, 0=Cx0_No_Request (No Request), 1=Cx1_Request}, transfer-property=PENDING
          signal APAFHSC2_oP2P_HSC2_FrP00_oCAN00: start 5, 1 bit, big-endian, init-value=0, base-type=boolean, compu {0..1=RANGE, 0=Cx0_Normal, 1=Cx1_APA_failure (APA failure)}, transfer-property=PENDING
          signal APACmdEPSStsHSC2_oP2P_HSC2_FrP00_oCAN00: start 7, 2 bit, big-endian, init-value=0, base-type=uint8, compu {0..3=RANGE, 0=Cx0_No_request (No request), 1=Cx1_Control_EPS_request (Control EPS request), 2=Cx2_EPS_control (EPS control)}, transfer-property=PENDING
          signal APATrgtEPSStrgWhlAngHSC2_oP2P_HSC2_FrP00_oCAN00: start 23, 16 bit, big-endian, init-value=0, base-type=uint16, compu {0=Cx0000_0x0_0xFFF0_ ((0x0 - 0xFFF0)), phys=raw*0.0625-2048 for raw 0..65520}, transfer-property=PENDING
          signal APAAlvRCHSC2_oP2P_HSC2_FrP00_oCAN00: start 39, 8 bit, big-endian, init-value=0, base-type=uint8, compu {0..255=RANGE, 0=Cx00_0x0_0xFF_ ((0x0 - 0xFF))}, transfer-property=PENDING
          signal APAChksmHSC2_oP2P_HSC2_FrP00_oCAN00: start 47, 8 bit, big-endian, init-value=0, base-type=uint8, compu {0..255=RANGE, 0=Cx00_0x0_0xFF_ ((0x0 - 0xFF))}, transfer-property=PENDING
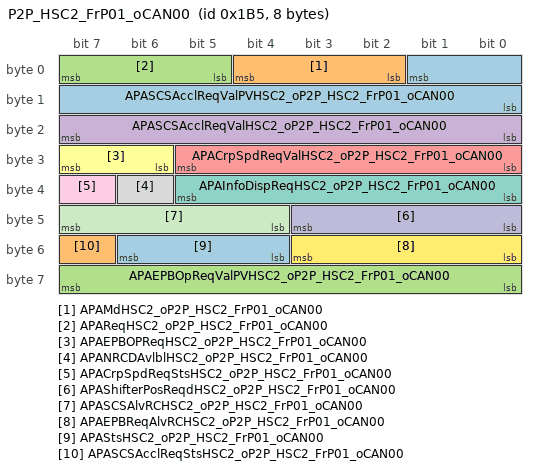
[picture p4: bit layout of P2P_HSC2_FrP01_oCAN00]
      frame P2P_HSC2_FrP01_oCAN00: id 0x1B5, from P2P, frame-length=8, can-addressing-mode=STANDARD
        pdu P2P_HSC2_FrP01_oCAN00: length=8, transmission-mode-false-timing=cyclic-timing=time-period=0, transmission-mode-true-timing=cyclic-timing=time-period=0, unused-bit-pattern=0
          signal APASCSAcclReqValPVHSC2_oP2P_HSC2_FrP01_oCAN00: start 1, 10 bit, big-endian, init-value=0, base-type=uint16, compu {0..1023=RANGE, 0=Cx000_0x0_0x3FF_ ((0x0 - 0x3FF))}, transfer-property=PENDING
          signal APAMdHSC2_oP2P_HSC2_FrP01_oCAN00: start 4, 3 bit, big-endian, init-value=0, base-type=uint8, compu {0..7=RANGE, 0=Cx0_Off, 1=Cx1_Parallel_Parking (Parallel Parking), 2=Cx2_Perpendicular_Parking (Perpendicular Parking), 3=Cx3_Park_Out (Park Out), 4=Cx4_Unknown_Parallel_Parking_or_Perpendicular_Parking (Unknown Parallel Parking or Perpendicular Parking), 5=Cx5_Unknown_Park_in_or_Park_Out (Unknown Park in or Park Out), 6=Cx6_Reserved, 7=Cx7_Reserved}, transfer-property=PENDING
          signal APAReqHSC2_oP2P_HSC2_FrP01_oCAN00: start 7, 3 bit, big-endian, init-value=0, base-type=uint8, compu {0..7=RANGE, 0=Cx0_Disable, 1=Cx1_Standby, 2=Cx2_Semi_APA_Mode_Request (Semi-APA Mode Request), 3=Cx3_Fully_APA_Mode_Request (Fully-APA Mode Request), 4=Cx4_Failed}, transfer-property=PENDING
          signal APASCSAcclReqValHSC2_oP2P_HSC2_FrP01_oCAN00: start 23, 8 bit, big-endian, init-value=0, base-type=uint8, compu {0=Cx00_m_s2_0x0_0xFF_ (m/s2 (0x0 - 0xFF)), phys=raw*0.1-12.7 for raw 0..255; unit m/s2}, unit=m/s2, transfer-property=PENDING
          signal APACrpSpdReqValHSC2_oP2P_HSC2_FrP01_oCAN00: start 29, 6 bit, big-endian, init-value=0, base-type=uint8, compu {0=Cx00_km_h_0x0_0x3F_ (km/h (0x0 - 0x3F)), phys=raw*0.1 for raw 0..62; unit km/h}, unit=km/h, transfer-property=PENDING
          signal APAEPBOPReqHSC2_oP2P_HSC2_FrP01_oCAN00: start 31, 2 bit, big-endian, init-value=0, base-type=uint8, compu {0..3=RANGE, 0=Cx0_No_Request (No Request), 1=Cx1_Apply, 2=Cx2_Release}, transfer-property=PENDING
          signal APAInfoDispReqHSC2_oP2P_HSC2_FrP01_oCAN00: start 37, 6 bit, big-endian, init-value=0, base-type=uint8, compu {0..63=RANGE, 0=Cx00_Reserved, 1=Cx01_Please_select_parking_mode (Please select parking mode), 2=Cx02_Vehicle_speed_is_too_high_APA_system_abort (Vehicle speed is too high, APA system abort), 3=Cx03_Vehicle_speed_is_too_high_please_be_slow_down (Vehicle speed is too high, please be slow down), 4=Cx04_Parking_slot_searching (Parking slot searching), 5=Cx05_APA_system_quit (APA system quit), 6=Cx06_Please_drive_forward (Please drive forward), 7=Cx07_Please_stop_the_car_ (Please stop the car), 8=Cx08_Please_select_park_in_direction_or_turn_on_direction_indicator (Please select park in direction or turn on direction indicator), 9=Cx09_External_Disturbance_System_stop_work (External Disturbance, System stop work), 10=Cx0A_Reserved, 11=Cx0B_Reserved, 12=Cx0C_Reserved, 13=Cx0D_Reserved, 14=Cx0E_Reserved, 15=Cx0F_Reserved, 16=Cx10_Please_fasten_seat_belt (Please fasten seat belt), 17=Cx11_Door_is_open_Parking_manoeuvre_quit (Door is open: Parking manoeuvre quit), 18=Cx12_System_failed_APA_system_is_useless (System failed, APA system is useless), 19=Cx13_Please_close_the_door (Please close the door), 20=Cx14_Reserved, 21=Cx15_Reserved, 22=Cx16_Reserved, 23=Cx17_Please_step_brake_pedal_if_you_want_to_use_parking_manoeuvre (Please step brake pedal if you want to use parking manoeuvre), 24=Cx18_Reserved, 25=Cx19_Reserved, 26=Cx1A_Reserved, 27=Cx1B_Reserved, 28=Cx1C_Reserved, 29=Cx1D_Reserved, 30=Cx1E_Reserved, 31=Cx1F_Reserved, 32=Cx20_APA_switch_no_press_parking_manoeuvre_quit (APA switch no press, parking manoeuvre quit), 33=Cx21_Danger_zone_has_obstacle_parking_manoeuvre_suspend (Danger zone has obstacle, parking manoeuvre suspend), 34=Cx22_Do_not_touch_steering_wheel_during_parking_process_parking_manoeuvre_quit (Do not touch steering wheel during parking process, parking manoeuvre quit), 35=Cx23_Step_on_the_gas_Parking_manoeuvre_quit (Step on the gas: Parking manoeuvre quit), 36=Cx24_Brake_pedal_has_been_pushed_Parking_manoeuvre_quit (Brake pedal has been pushed: Parking manoeuvre quit), 37=Cx25_Shifter_lever_has_been_controlled_Parking_manoeuvre_quit (Shifter lever has been controlled: Parking manoeuvre quit), 38=Cx26_APA_system_abort_Please_take_over_vehicle (APA system abort, Please take over vehicle), 39=Cx27_Gradient_too_large_APA_system_quit (Gradient too large£¬ APA system quit), 40=Cx28_Reserved, 41=Cx29_Reserved, 42=Cx2A_Please_keep_away_steering_wheel_and_press_APA_switch_if_you_want_to_parking_in (Please keep away steering wheel and press APA switch if you want to parking in), 43=Cx2B_Parking_is_ready (Parking is ready), 44=Cx2C_Please_release_brake_and_pay_attention_to_surroundings_using_active_control_measure_if_necessary_ (Please release brake and pay attention to surroundings, using active control measure if necessary), 45=Cx2D_Parking_is_ongoing (Parking is ongoing), 46=Cx2E_Parking_manoeuvre_has_completed_Please_take_over_vehicle (Parking manoeuvre has completed: Please take over vehicle), 47=Cx2F_Please_keep_away_steering_wheel_and_re_press_APA_switch_if_you_want_to_parking_in_continually (Please keep away steering wheel and re-press APA switch if you want to parking in continually), 48=Cx30_System_timeout_APA_system_quit (System timeout, APA system quit), 49=Cx31_Please_select_park_out_direction_or_turn_on_direction_indicator (Please select park out direction or turn on direction indicator), 50=Cx32_Please_keep_away_steering_wheel_and_press_APA_switch_if_you_want_to_park_out (Please keep away steering wheel and press APA switch if you want to park out), 51=Cx33_Please_keep_away_steering_wheel_and_re_press_APA_switch_if_you_want_to_park_out_continually (Please keep away steering wheel and re-press APA switch if you want to park out continually), 52=Cx34_Reserved, 53=Cx35_Reserved, 54=Cx36_Reserved, 55=Cx37_Please_select_reverse_gear_and_keep_away_steering_wheel (Please select reverse gear and keep away steering wheel), 56=Cx38_Be_careful_drive_backward_and_prepare_for_stop (Be careful drive backward and prepare for stop), 57=Cx39_Please_select_drive_gear_and_move_forward (Please select drive gear and move forward), 58=Cx3A_Be_careful_drive_forward_and_prepare_for_stop (Be careful drive forward and prepare for stop), 59=Cx3B_Please_select_reverse_gear_and_move_backward (Please select reverse gear and move backward), 60=Cx3C_Vehicle_is_going_to_move_forward (Vehicle is going to move forward), 61=Cx3D_Vehicle_is_going_to_move_backward (Vehicle is going to move backward), 62=Cx3E_Reserved, 63=Cx3F_Reserved}, transfer-property=PENDING
          signal APANRCDAvlblHSC2_oP2P_HSC2_FrP01_oCAN00: start 38, 1 bit, big-endian, init-value=0, base-type=boolean, compu {0..1=RANGE, 0=Cx0_Not_available (Not available), 1=Cx1_Available}, transfer-property=PENDING  # Advanced Park Assist Near Range Control Drive Available
          signal APACrpSpdReqStsHSC2_oP2P_HSC2_FrP01_oCAN00: start 39, 1 bit, big-endian, init-value=0, base-type=boolean, compu {0..1=RANGE, 0=Cx0_No_Request (No Request), 1=Cx1_Request}, transfer-property=PENDING
          signal APAShifterPosReqdHSC2_oP2P_HSC2_FrP01_oCAN00: start 43, 4 bit, big-endian, init-value=0, base-type=uint8, compu {0..15=RANGE, 0=Cx0_Initial, 1=Cx1_S_Sport_mode_ (S(Sport mode)), 2=Cx2_W_Winter_mode_ (W(Winter mode)), 3=Cx3_M_Manual_mode_ (M(Manual mode)), 5=Cx5_D_Drive_ (D(Drive)), 6=Cx6_N_Neutral_ (N(Neutral)), 7=Cx7_R_Reverse_ (R(Reverse)), 8=Cx8_P_Park_ (P(Park)), 9=Cx9_Reserve, 10=CxA_Error}, transfer-property=PENDING
          signal APASCSAlvRCHSC2_oP2P_HSC2_FrP01_oCAN00: start 47, 4 bit, big-endian, init-value=0, base-type=uint8, compu {0..15=RANGE, 0=Cx0_0x0_0xF_ ((0x0 - 0xF))}, transfer-property=PENDING
          signal APAEPBReqAlvRCHSC2_oP2P_HSC2_FrP01_oCAN00: start 51, 4 bit, big-endian, init-value=0, base-type=uint8, compu {0..15=RANGE, 0=Cx0_0x0_0xF_ ((0x0 - 0xF))}, transfer-property=PENDING
          signal APAStsHSC2_oP2P_HSC2_FrP01_oCAN00: start 54, 3 bit, big-endian, init-value=0, base-type=uint8, compu {0..7=RANGE, 0=Cx0_Disable, 1=Cx1_Standby, 2=Cx2_Semi_APA_Active (Semi-APA Active), 3=Cx3_Fully_APA_Active (Fully-APA Active), 4=Cx4_Failed}, transfer-property=PENDING
          signal APASCSAcclReqStsHSC2_oP2P_HSC2_FrP01_oCAN00: start 55, 1 bit, big-endian, init-value=0, base-type=boolean, compu {0..1=RANGE, 0=Cx0_no_request (no request), 1=Cx1_Deceleration_request (Deceleration request)}, transfer-property=PENDING
          signal APAEPBOpReqValPVHSC2_oP2P_HSC2_FrP01_oCAN00: start 63, 8 bit, big-endian, init-value=0, base-type=uint8, compu {0..255=RANGE, 0=Cx00_0x0_0xFF_ ((0x0 - 0xFF))}, transfer-property=PENDING
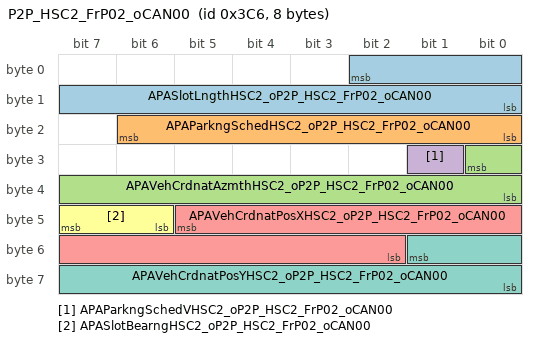
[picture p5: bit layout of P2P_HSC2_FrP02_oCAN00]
      frame P2P_HSC2_FrP02_oCAN00: id 0x3C6, from P2P, frame-length=8, can-addressing-mode=STANDARD
        pdu P2P_HSC2_FrP02_oCAN00: length=8, transmission-mode-false-timing=cyclic-timing=time-period=0, transmission-mode-true-timing=cyclic-timing=time-period=0, unused-bit-pattern=0
          signal APASlotLngthHSC2_oP2P_HSC2_FrP02_oCAN00: start 2, 11 bit, big-endian, init-value=0, base-type=uint16, compu {0..2047=RANGE, 0=Cx000_cm_0x0_0x7FF_ (cm (0x0 - 0x7FF)); unit cm}, unit=cm, transfer-property=PENDING  # Advanced Park Assist Slot Length
          signal APAParkngSchedHSC2_oP2P_HSC2_FrP02_oCAN00: start 22, 7 bit, big-endian, init-value=0, base-type=uint8, compu {0=Cx00_0x0_0x64_ ((0x0 - 0x64)), phys=raw*0.01 for raw 0..100}, transfer-property=PENDING  # Advanced Park Assist Parking Schedule
          signal APAVehCrdnatAzmthHSC2_oP2P_HSC2_FrP02_oCAN00: start 24, 9 bit, big-endian, init-value=0, base-type=uint16, compu {0..511=RANGE, 0=Cx000_0x0_0x1FF_ (¡ã (0x0 - 0x1FF))}, transfer-property=PENDING  # Advanced Park Assist Vehicle Coordinate Azimuth
          signal APAParkngSchedVHSC2_oP2P_HSC2_FrP02_oCAN00: start 25, 1 bit, big-endian, init-value=0, base-type=boolean, compu {0..1=RANGE, 0=Cx0_Valid, 1=Cx1_Invalid}, transfer-property=PENDING  # Advanced Park Assist Parking Schedule Validit
          signal APAVehCrdnatPosXHSC2_oP2P_HSC2_FrP02_oCAN00: start 45, 12 bit, big-endian, init-value=0, base-type=uint16, compu {0=Cx000_cm_0x0_0xFFF_ (cm (0x0 - 0xFFF)), phys=raw-2048 for raw 0..4095; unit cm}, unit=cm, transfer-property=PENDING  # Advanced Park Assist Vehicle Coordinate Position X
          signal APASlotBearngHSC2_oP2P_HSC2_FrP02_oCAN00: start 47, 2 bit, big-endian, init-value=0, base-type=uint8, compu {0..3=RANGE, 0=Cx0_No_slot (No slot), 1=Cx1_Left_slot (Left slot), 2=Cx2_Right_slot (Right slot), 3=Cx3_Both_left_and_right_slot (Both left and right slot)}, transfer-property=PENDING  # Advanced Park Assist Slot Bearing
          signal APAVehCrdnatPosYHSC2_oP2P_HSC2_FrP02_oCAN00: start 49, 10 bit, big-endian, init-value=0, base-type=uint16, compu {0=Cx000_cm_0x0_0x3FF_ (cm (0x0 - 0x3FF)), phys=raw-512 for raw 0..1023; unit cm}, unit=cm, transfer-property=PENDING  # Advanced Park Assist Vehicle Coordinate Position Y
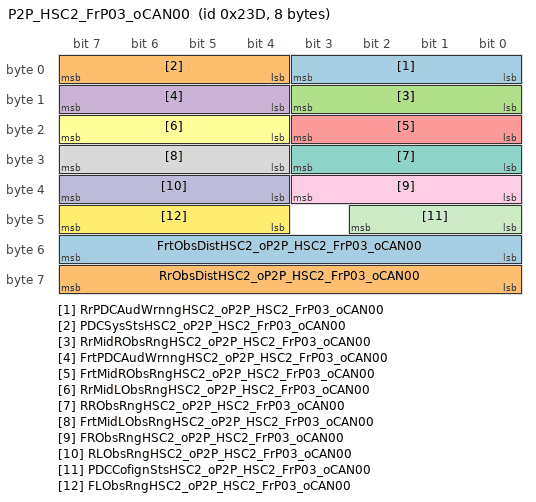
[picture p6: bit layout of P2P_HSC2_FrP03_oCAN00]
      frame P2P_HSC2_FrP03_oCAN00: id 0x23D, from P2P, frame-length=8, can-addressing-mode=STANDARD
        pdu P2P_HSC2_FrP03_oCAN00: length=8, transmission-mode-false-timing=cyclic-timing=time-period=0, transmission-mode-true-timing=cyclic-timing=time-period=0, unused-bit-pattern=0
          signal RrPDCAudWrnngHSC2_oP2P_HSC2_FrP03_oCAN00: start 3, 4 bit, big-endian, init-value=0, base-type=uint8, compu {0..15=RANGE, 0=Cx0_No_Obstacle (No Obstacle), 1=Cx1_Range_1 (Range 1), 2=Cx2_Range_2 (Range 2), 3=Cx3_Range_3 (Range 3), 4=Cx4_Range_4 (Range 4), 5=Cx5_Range_5 (Range 5), 6=Cx6_Range_6 (Range 6), 7=Cx7_Range_7 (Range 7), 8=Cx8_Range_8 (Range 8), 9=Cx9_Range_9 (Range 9), 10=CxA_Range_10 (Range 10), 11=CxB_Range_11 (Range 11), 12=CxC_Range_12 (Range 12), 13=CxD_Range_13 (Range 13), 14=CxE_Range_14 (Range 14), 15=CxF_Range_15 (Range 15)}, transfer-property=PENDING
          signal PDCSysStsHSC2_oP2P_HSC2_FrP03_oCAN00: start 7, 4 bit, big-endian, init-value=0, base-type=uint8, compu {0..15=RANGE, 0=Cx0_System_OK (System OK), 1=Cx1_System_initialization_sucessful (System initialization sucessful), 2=Cx2_System_Failed (System Failed), 3=Cx3_System_Disabled (System Disabled), 4=Cx4_Front_PDC_Disabled (Front PDC Disabled), 5=Cx5_Front_PDC_Failed (Front PDC Failed), 6=Cx6_Rear_PDC_Failed (Rear PDC Failed), 7=Cx7_Rear_PDC_Disabled (Rear PDC Disabled)}, transfer-property=PENDING
          signal RrMidRObsRngHSC2_oP2P_HSC2_FrP03_oCAN00: start 11, 4 bit, big-endian, init-value=0, base-type=uint8, compu {0..15=RANGE, 0=Cx0_No_Obstacle (No Obstacle), 1=Cx1_Range_1 (Range 1), 2=Cx2_Range_2 (Range 2), 3=Cx3_Range_3 (Range 3), 4=Cx4_Range_4 (Range 4), 5=Cx5_Range_5 (Range 5), 6=Cx6_Range_6 (Range 6), 7=Cx7_Range_7 (Range 7), 8=Cx8_Range_8 (Range 8), 9=Cx9_Range_9 (Range 9), 10=CxA_Range_10 (Range 10), 11=CxB_Range_11 (Range 11), 12=CxC_Range_12 (Range 12), 13=CxD_Range_13 (Range 13), 14=CxE_Range_14 (Range 14), 15=CxF_Range_15 (Range 15)}, transfer-property=PENDING
          signal FrtPDCAudWrnngHSC2_oP2P_HSC2_FrP03_oCAN00: start 15, 4 bit, big-endian, init-value=0, base-type=uint8, compu {0..15=RANGE, 0=Cx0_No_Obstacle (No Obstacle), 1=Cx1_Range_1 (Range 1), 2=Cx2_Range_2 (Range 2), 3=Cx3_Range_3 (Range 3), 4=Cx4_Range_4 (Range 4), 5=Cx5_Range_5 (Range 5), 6=Cx6_Range_6 (Range 6), 7=Cx7_Range_7 (Range 7), 8=Cx8_Range_8 (Range 8), 9=Cx9_Range_9 (Range 9), 10=CxA_Range_10 (Range 10), 11=CxB_Range_11 (Range 11), 12=CxC_Range_12 (Range 12), 13=CxD_Range_13 (Range 13), 14=CxE_Range_14 (Range 14), 15=CxF_Range_15 (Range 15)}, transfer-property=PENDING
          signal FrtMidRObsRngHSC2_oP2P_HSC2_FrP03_oCAN00: start 19, 4 bit, big-endian, init-value=0, base-type=uint8, compu {0..15=RANGE, 0=Cx0_No_Obstacle (No Obstacle), 1=Cx1_Range_1 (Range 1), 2=Cx2_Range_2 (Range 2), 3=Cx3_Range_3 (Range 3), 4=Cx4_Range_4 (Range 4), 5=Cx5_Range_5 (Range 5), 6=Cx6_Range_6 (Range 6), 7=Cx7_Range_7 (Range 7), 8=Cx8_Range_8 (Range 8), 9=Cx9_Range_9 (Range 9), 10=CxA_Range_10 (Range 10), 11=CxB_Range_11 (Range 11), 12=CxC_Range_12 (Range 12), 13=CxD_Range_13 (Range 13), 14=CxE_Range_14 (Range 14), 15=CxF_Range_15 (Range 15)}, transfer-property=PENDING
          signal RrMidLObsRngHSC2_oP2P_HSC2_FrP03_oCAN00: start 23, 4 bit, big-endian, init-value=0, base-type=uint8, compu {0..15=RANGE, 0=Cx0_No_Obstacle (No Obstacle), 1=Cx1_Range_1 (Range 1), 2=Cx2_Range_2 (Range 2), 3=Cx3_Range_3 (Range 3), 4=Cx4_Range_4 (Range 4), 5=Cx5_Range_5 (Range 5), 6=Cx6_Range_6 (Range 6), 7=Cx7_Range_7 (Range 7), 8=Cx8_Range_8 (Range 8), 9=Cx9_Range_9 (Range 9), 10=CxA_Range_10 (Range 10), 11=CxB_Range_11 (Range 11), 12=CxC_Range_12 (Range 12), 13=CxD_Range_13 (Range 13), 14=CxE_Range_14 (Range 14), 15=CxF_Range_15 (Range 15)}, transfer-property=PENDING
          signal RRObsRngHSC2_oP2P_HSC2_FrP03_oCAN00: start 27, 4 bit, big-endian, init-value=0, base-type=uint8, compu {0..15=RANGE, 0=Cx0_No_Obstacle (No Obstacle), 1=Cx1_Range_1 (Range 1), 2=Cx2_Range_2 (Range 2), 3=Cx3_Range_3 (Range 3), 4=Cx4_Range_4 (Range 4), 5=Cx5_Range_5 (Range 5), 6=Cx6_Range_6 (Range 6), 7=Cx7_Range_7 (Range 7), 8=Cx8_Range_8 (Range 8), 9=Cx9_Range_9 (Range 9), 10=CxA_Range_10 (Range 10), 11=CxB_Range_11 (Range 11), 12=CxC_Range_12 (Range 12), 13=CxD_Range_13 (Range 13), 14=CxE_Range_14 (Range 14), 15=CxF_Range_15 (Range 15)}, transfer-property=PENDING
          signal FrtMidLObsRngHSC2_oP2P_HSC2_FrP03_oCAN00: start 31, 4 bit, big-endian, init-value=0, base-type=uint8, compu {0..15=RANGE, 0=Cx0_No_Obstacle (No Obstacle), 1=Cx1_Range_1 (Range 1), 2=Cx2_Range_2 (Range 2), 3=Cx3_Range_3 (Range 3), 4=Cx4_Range_4 (Range 4), 5=Cx5_Range_5 (Range 5), 6=Cx6_Range_6 (Range 6), 7=Cx7_Range_7 (Range 7), 8=Cx8_Range_8 (Range 8), 9=Cx9_Range_9 (Range 9), 10=CxA_Range_10 (Range 10), 11=CxB_Range_11 (Range 11), 12=CxC_Range_12 (Range 12), 13=CxD_Range_13 (Range 13), 14=CxE_Range_14 (Range 14), 15=CxF_Range_15 (Range 15)}, transfer-property=PENDING
          signal FRObsRngHSC2_oP2P_HSC2_FrP03_oCAN00: start 35, 4 bit, big-endian, init-value=0, base-type=uint8, compu {0..15=RANGE, 0=Cx0_No_Obstacle (No Obstacle), 1=Cx1_Range_1 (Range 1), 2=Cx2_Range_2 (Range 2), 3=Cx3_Range_3 (Range 3), 4=Cx4_Range_4 (Range 4), 5=Cx5_Range_5 (Range 5), 6=Cx6_Range_6 (Range 6), 7=Cx7_Range_7 (Range 7), 8=Cx8_Range_8 (Range 8), 9=Cx9_Range_9 (Range 9), 10=CxA_Range_10 (Range 10), 11=CxB_Range_11 (Range 11), 12=CxC_Range_12 (Range 12), 13=CxD_Range_13 (Range 13), 14=CxE_Range_14 (Range 14), 15=CxF_Range_15 (Range 15)}, transfer-property=PENDING
          signal RLObsRngHSC2_oP2P_HSC2_FrP03_oCAN00: start 39, 4 bit, big-endian, init-value=0, base-type=uint8, compu {0..15=RANGE, 0=Cx0_No_Obstacle (No Obstacle), 1=Cx1_Range_1 (Range 1), 2=Cx2_Range_2 (Range 2), 3=Cx3_Range_3 (Range 3), 4=Cx4_Range_4 (Range 4), 5=Cx5_Range_5 (Range 5), 6=Cx6_Range_6 (Range 6), 7=Cx7_Range_7 (Range 7), 8=Cx8_Range_8 (Range 8), 9=Cx9_Range_9 (Range 9), 10=CxA_Range_10 (Range 10), 11=CxB_Range_11 (Range 11), 12=CxC_Range_12 (Range 12), 13=CxD_Range_13 (Range 13), 14=CxE_Range_14 (Range 14), 15=CxF_Range_15 (Range 15)}, transfer-property=PENDING
          signal PDCCofignStsHSC2_oP2P_HSC2_FrP03_oCAN00: start 42, 3 bit, big-endian, init-value=1, base-type=uint8, compu {0..7=RANGE, 0=Cx0_3_rear_sensors (3 rear sensors), 1=Cx1_4_rear_sensors (4 rear sensors), 2=Cx2_4_rear_sensors_and_2_front_side_sensors (4 rear sensors and 2 front side sensors), 3=Cx3_4_rear_sensors_and_4_front_sensors (4 rear sensors and 4 front sensors), 4=Cx4_2_rear_sensors (2 rear sensors), 5=Cx5_Reserved, 6=Cx6_Reserved, 7=Cx7_Reserved}, transfer-property=PENDING
          signal FLObsRngHSC2_oP2P_HSC2_FrP03_oCAN00: start 47, 4 bit, big-endian, init-value=0, base-type=uint8, compu {0..15=RANGE, 0=Cx0_No_Obstacle (No Obstacle), 1=Cx1_Range_1 (Range 1), 2=Cx2_Range_2 (Range 2), 3=Cx3_Range_3 (Range 3), 4=Cx4_Range_4 (Range 4), 5=Cx5_Range_5 (Range 5), 6=Cx6_Range_6 (Range 6), 7=Cx7_Range_7 (Range 7), 8=Cx8_Range_8 (Range 8), 9=Cx9_Range_9 (Range 9), 10=CxA_Range_10 (Range 10), 11=CxB_Range_11 (Range 11), 12=CxC_Range_12 (Range 12), 13=CxD_Range_13 (Range 13), 14=CxE_Range_14 (Range 14), 15=CxF_Range_15 (Range 15)}, transfer-property=PENDING
          signal FrtObsDistHSC2_oP2P_HSC2_FrP03_oCAN00: start 55, 8 bit, big-endian, init-value=0, base-type=uint8, compu {0..255=RANGE, 0=Cx00_cm_0x0_0xFF_ (cm (0x0 - 0xFF)); unit cm}, unit=cm, transfer-property=PENDING
          signal RrObsDistHSC2_oP2P_HSC2_FrP03_oCAN00: start 63, 8 bit, big-endian, init-value=0, base-type=uint8, compu {0..255=RANGE, 0=Cx00_0x0_0xFF_ ((0x0 - 0xFF))}, transfer-property=PENDING
      frame P2P_HSC2_FrP04_oCAN00: id 0x237, from P2P, frame-length=8, can-addressing-mode=STANDARD
        pdu P2P_HSC2_FrP04_oCAN00: length=8, transmission-mode-false-timing=cyclic-timing=time-period=0, transmission-mode-true-timing=cyclic-timing=time-period=0, unused-bit-pattern=0
          signal RRSideObsDistHSC2_oP2P_HSC2_FrP04_oCAN00: start 0, 9 bit, big-endian, init-value=0, base-type=uint16, compu {0..511=RANGE, 0=Cx000_0x0_0x1FF_ ((0x0 - 0x1FF))}, transfer-property=PENDING
          signal RLSideObsDistHSC2_oP2P_HSC2_FrP04_oCAN00: start 16, 9 bit, big-endian, init-value=0, base-type=uint16, compu {0..511=RANGE, 0=Cx000_0x0_0x1FF_ ((0x0 - 0x1FF))}, transfer-property=PENDING
          signal FRSideObsDistHSC2_oP2P_HSC2_FrP04_oCAN00: start 32, 9 bit, big-endian, init-value=0, base-type=uint16, compu {0..511=RANGE, 0=Cx000_0x0_0x1FF_ ((0x0 - 0x1FF))}, transfer-property=PENDING
          signal FLSideObsDistHSC2_oP2P_HSC2_FrP04_oCAN00: start 48, 9 bit, big-endian, init-value=0, base-type=uint16, compu {0..511=RANGE, 0=Cx000_0x0_0x1FF_ ((0x0 - 0x1FF))}, transfer-property=PENDING
      frame P2P_HSC2_FrS01_oCAN00: id 0x602, from P2P, frame-length=8, can-addressing-mode=STANDARD
        pdu P2P_HSC2_FrS01_oCAN00: length=8, unused-bit-pattern=0
          signal IECUToBCMRmtCtrlPotclHSC2_oP2P_HSC2_FrS01_oCAN00: start 0, 64 bit, opaque, init-value=8 x 0, base-type=uint8_8_iso_8859_1, compu {0..18446744073709551615=RANGE}, transfer-property=PENDING
      frame SAS_HSC2_FrP00_oCAN00: id 0x1E5, to P2P, frame-length=8, can-addressing-mode=STANDARD
        pdu SAS_HSC2_FrP00_oCAN00: length=8, transmission-mode-false-timing=cyclic-timing=time-period=0, transmission-mode-true-timing=cyclic-timing=time-period=0, unused-bit-pattern=0
          signal StrgWhlAngVHSC2_oSAS_HSC2_FrP00_oCAN00: start 7, 1 bit, big-endian, init-value=0, base-type=boolean, compu {0..1=RANGE, 0=Cx0_Valid, 1=Cx1_Invalid}, transfer-property=PENDING, to P2P
          signal StrgWhlAngHSC2_oSAS_HSC2_FrP00_oCAN00: start 15, 16 bit, big-endian, init-value=0, base-type=uint16, compu {0=Cx0000_degree_0x0_0xFFFE_ (degree (0x0 - 0xFFFE)), 65535=CxFFFF_error_mark (error mark), phys=raw*0.0625-2048 for raw 0..65535; unit degree} "Source signal range: [0,65534.08]", unit=degree, transfer-property=PENDING, to P2P
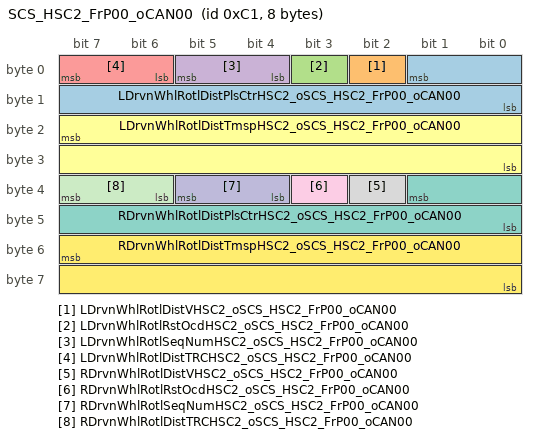
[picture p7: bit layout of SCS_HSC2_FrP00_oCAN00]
      frame SCS_HSC2_FrP00_oCAN00: id 0xC1, to P2P, frame-length=8, can-addressing-mode=STANDARD
        pdu SCS_HSC2_FrP00_oCAN00: length=8, transmission-mode-false-timing=cyclic-timing=time-period=0, transmission-mode-true-timing=cyclic-timing=time-period=0, unused-bit-pattern=0
          signal LDrvnWhlRotlDistPlsCtrHSC2_oSCS_HSC2_FrP00_oCAN00: start 1, 10 bit, big-endian, init-value=0, base-type=uint16, compu {0..1023=RANGE, 0=Cx000_0x0_0x3FF_ ((0x0 - 0x3FF))}, transfer-property=PENDING, to P2P
          signal LDrvnWhlRotlDistVHSC2_oSCS_HSC2_FrP00_oCAN00: start 2, 1 bit, big-endian, init-value=0, base-type=boolean, compu {0..1=RANGE, 0=Cx0_Valid, 1=Cx1_Invalid}, transfer-property=PENDING, to P2P
          signal LDrvnWhlRotlRstOcdHSC2_oSCS_HSC2_FrP00_oCAN00: start 3, 1 bit, big-endian, init-value=0, base-type=boolean, compu {0..1=RANGE, 0=Cx0_False, 1=Cx1_True}, transfer-property=PENDING, to P2P
          signal LDrvnWhlRotlSeqNumHSC2_oSCS_HSC2_FrP00_oCAN00: start 5, 2 bit, big-endian, init-value=0, base-type=uint8, compu {0..3=RANGE, 0=Cx0_0x0_0x3_ ((0x0 - 0x3))}, transfer-property=PENDING, to P2P
          signal LDrvnWhlRotlDistTRCHSC2_oSCS_HSC2_FrP00_oCAN00: start 7, 2 bit, big-endian, init-value=0, base-type=uint8, compu {0..3=RANGE, 0=Cx0_0x0_0x3_ ((0x0 - 0x3))}, transfer-property=PENDING, to P2P
          signal LDrvnWhlRotlDistTmspHSC2_oSCS_HSC2_FrP00_oCAN00: start 23, 16 bit, big-endian, init-value=0, base-type=uint16, compu {0..65535=RANGE, 0=Cx0000_0x0_0xFFFF_ ((0x0 - 0xFFFF))}, transfer-property=PENDING, to P2P
          signal RDrvnWhlRotlDistPlsCtrHSC2_oSCS_HSC2_FrP00_oCAN00: start 33, 10 bit, big-endian, init-value=0, base-type=uint16, compu {0..1023=RANGE, 0=Cx000_0x0_0x3FF_ ((0x0 - 0x3FF))}, transfer-property=PENDING, to P2P
          signal RDrvnWhlRotlDistVHSC2_oSCS_HSC2_FrP00_oCAN00: start 34, 1 bit, big-endian, init-value=0, base-type=boolean, compu {0..1=RANGE, 0=Cx0_Valid, 1=Cx1_Invalid}, transfer-property=PENDING, to P2P
          signal RDrvnWhlRotlRstOcdHSC2_oSCS_HSC2_FrP00_oCAN00: start 35, 1 bit, big-endian, init-value=0, base-type=boolean, compu {0..1=RANGE, 0=Cx0_False, 1=Cx1_True}, transfer-property=PENDING, to P2P
          signal RDrvnWhlRotlSeqNumHSC2_oSCS_HSC2_FrP00_oCAN00: start 37, 2 bit, big-endian, init-value=0, base-type=uint8, compu {0..3=RANGE, 0=Cx0_0x0_0x3_ ((0x0 - 0x3))}, transfer-property=PENDING, to P2P
          signal RDrvnWhlRotlDistTRCHSC2_oSCS_HSC2_FrP00_oCAN00: start 39, 2 bit, big-endian, init-value=0, base-type=uint8, compu {0..3=RANGE, 0=Cx0_0x0_0x3_ ((0x0 - 0x3))}, transfer-property=PENDING, to P2P
          signal RDrvnWhlRotlDistTmspHSC2_oSCS_HSC2_FrP00_oCAN00: start 55, 16 bit, big-endian, init-value=0, base-type=uint16, compu {0..65535=RANGE, 0=Cx0000_0x0_0xFFFF_ ((0x0 - 0xFFFF))}, transfer-property=PENDING, to P2P
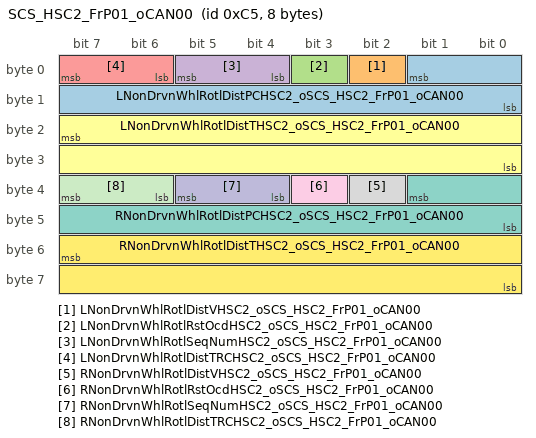
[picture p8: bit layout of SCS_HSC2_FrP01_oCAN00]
      frame SCS_HSC2_FrP01_oCAN00: id 0xC5, to P2P, frame-length=8, can-addressing-mode=STANDARD
        pdu SCS_HSC2_FrP01_oCAN00: length=8, transmission-mode-false-timing=cyclic-timing=time-period=0, transmission-mode-true-timing=cyclic-timing=time-period=0, unused-bit-pattern=0
          signal LNonDrvnWhlRotlDistPCHSC2_oSCS_HSC2_FrP01_oCAN00: start 1, 10 bit, big-endian, init-value=0, base-type=uint16, compu {0..1023=RANGE, 0=Cx000_0x0_0x3FF_ ((0x0 - 0x3FF))}, transfer-property=PENDING, to P2P
          signal LNonDrvnWhlRotlDistVHSC2_oSCS_HSC2_FrP01_oCAN00: start 2, 1 bit, big-endian, init-value=0, base-type=boolean, compu {0..1=RANGE, 0=Cx0_Valid, 1=Cx1_Invalid}, transfer-property=PENDING, to P2P
          signal LNonDrvnWhlRotlRstOcdHSC2_oSCS_HSC2_FrP01_oCAN00: start 3, 1 bit, big-endian, init-value=0, base-type=boolean, compu {0..1=RANGE, 0=Cx0_False, 1=Cx1_True}, transfer-property=PENDING, to P2P
          signal LNonDrvnWhlRotlSeqNumHSC2_oSCS_HSC2_FrP01_oCAN00: start 5, 2 bit, big-endian, init-value=0, base-type=uint8, compu {0..3=RANGE, 0=Cx0_0x0_0x3_ ((0x0 - 0x3))}, transfer-property=PENDING, to P2P
          signal LNonDrvnWhlRotlDistTRCHSC2_oSCS_HSC2_FrP01_oCAN00: start 7, 2 bit, big-endian, init-value=0, base-type=uint8, compu {0..3=RANGE, 0=Cx0_0x0_0x3_ ((0x0 - 0x3))}, transfer-property=PENDING, to P2P
          signal LNonDrvnWhlRotlDistTHSC2_oSCS_HSC2_FrP01_oCAN00: start 23, 16 bit, big-endian, init-value=0, base-type=uint16, compu {0..65535=RANGE, 0=Cx0000_0x0_0xFFFF_ ((0x0 - 0xFFFF))}, transfer-property=PENDING, to P2P
          signal RNonDrvnWhlRotlDistPCHSC2_oSCS_HSC2_FrP01_oCAN00: start 33, 10 bit, big-endian, init-value=0, base-type=uint16, compu {0..1023=RANGE, 0=Cx000_0x0_0x3FF_ ((0x0 - 0x3FF))}, transfer-property=PENDING, to P2P
          signal RNonDrvnWhlRotlDistVHSC2_oSCS_HSC2_FrP01_oCAN00: start 34, 1 bit, big-endian, init-value=0, base-type=boolean, compu {0..1=RANGE, 0=Cx0_Valid, 1=Cx1_Invalid}, transfer-property=PENDING, to P2P
          signal RNonDrvnWhlRotlRstOcdHSC2_oSCS_HSC2_FrP01_oCAN00: start 35, 1 bit, big-endian, init-value=0, base-type=boolean, compu {0..1=RANGE, 0=Cx0_False, 1=Cx1_True}, transfer-property=PENDING, to P2P
          signal RNonDrvnWhlRotlSeqNumHSC2_oSCS_HSC2_FrP01_oCAN00: start 37, 2 bit, big-endian, init-value=0, base-type=uint8, compu {0..3=RANGE, 0=Cx0_0x0_0x3_ ((0x0 - 0x3))}, transfer-property=PENDING, to P2P
          signal RNonDrvnWhlRotlDistTRCHSC2_oSCS_HSC2_FrP01_oCAN00: start 39, 2 bit, big-endian, init-value=0, base-type=uint8, compu {0..3=RANGE, 0=Cx0_0x0_0x3_ ((0x0 - 0x3))}, transfer-property=PENDING, to P2P
          signal RNonDrvnWhlRotlDistTHSC2_oSCS_HSC2_FrP01_oCAN00: start 55, 16 bit, big-endian, init-value=0, base-type=uint16, compu {0..65535=RANGE, 0=Cx0000_0x0_0xFFFF_ ((0x0 - 0xFFFF))}, transfer-property=PENDING, to P2P
      frame SCS_HSC2_FrP02_oCAN00: id 0x185, to P2P, frame-length=4, can-addressing-mode=STANDARD
        pdu SCS_HSC2_FrP02_oCAN00: length=4, transmission-mode-false-timing=cyclic-timing=time-period=0, transmission-mode-true-timing=cyclic-timing=time-period=0, unused-bit-pattern=0
          signal VSELongtAccHSC2_oSCS_HSC2_FrP02_oCAN00: start 1, 10 bit, big-endian, init-value=0, base-type=sint16, compu {-512=Cx200_m_s_2_0xFFFFFE00_0x1FF_ (m/s^2 (0xFFFFFE00 - 0x1FF)), phys=raw*0.03 for raw -512..511; unit m/s^2}, unit=m/s^2, transfer-property=PENDING, to P2P
          signal VSELongtAccVHSC2_oSCS_HSC2_FrP02_oCAN00: start 2, 1 bit, big-endian, init-value=0, base-type=boolean, compu {0..1=RANGE, 0=Cx0_Valid, 1=Cx1_Invalid}, transfer-property=PENDING, to P2P
          signal VSELatAccVHSC2_oSCS_HSC2_FrP02_oCAN00: start 3, 1 bit, big-endian, init-value=0, base-type=boolean, compu {0..1=RANGE, 0=Cx0_Valid, 1=Cx1_Invalid}, transfer-property=PENDING, to P2P
          signal VSELatAccHSC2_oSCS_HSC2_FrP02_oCAN00: start 19, 12 bit, big-endian, init-value=0, base-type=sint16, compu {-2048=Cx800_m_s_2_0xFFFFF800_0x7FF_ (m/s^2 (0xFFFFF800 - 0x7FF)), phys=raw/64 for raw -2048..2047; unit m/s^2}, unit=m/s^2, transfer-property=PENDING, to P2P
      frame SCS_HSC2_FrP03_oCAN00: id 0x1C7, to P2P, frame-length=8, can-addressing-mode=STANDARD
        pdu SCS_HSC2_FrP03_oCAN00: length=8, transmission-mode-false-timing=cyclic-timing=time-period=0, transmission-mode-true-timing=cyclic-timing=time-period=0, unused-bit-pattern=0
          signal LNonDrvnWhlRotlDircnHSC2_oSCS_HSC2_FrP03_oCAN00: start 33, 2 bit, big-endian, init-value=3, base-type=uint8, compu {0..3=RANGE, 0=Cx0_No_moving (No moving), 1=Cx1_Moving_forward (Moving forward), 2=Cx2_Moving_backward (Moving backward), 3=Cx3_Error_Invalid (Error/Invalid)}, transfer-property=PENDING, to P2P
          signal RNonDrvnWhlRotlDircnHSC2_oSCS_HSC2_FrP03_oCAN00: start 35, 2 bit, big-endian, init-value=3, base-type=uint8, compu {0..3=RANGE, 0=Cx0_No_moving (No moving), 1=Cx1_Moving_forward (Moving forward), 2=Cx2_Moving_backward (Moving backward), 3=Cx3_Error_Invalid (Error/Invalid)}, transfer-property=PENDING, to P2P
          signal SCSAPAAlvRCHSC2_oSCS_HSC2_FrP03_oCAN00: start 39, 4 bit, big-endian, init-value=0, base-type=uint8, compu {0..15=RANGE, 0=Cx0_0x0_0xF_ ((0x0 - 0xF))}, transfer-property=PENDING, to P2P
          signal SCSNRCDAvlblHSC2_oSCS_HSC2_FrP03_oCAN00: start 45, 1 bit, big-endian, init-value=0, base-type=boolean, compu {0..1=RANGE, 0=Cx0_Unavailable_, 1=Cx1_Available_}, transfer-property=PENDING, to P2P  # Stability Control System Near Range Control Drive Available
          signal SCSAPAAcclAHSC2_oSCS_HSC2_FrP03_oCAN00: start 46, 1 bit, big-endian, init-value=0, base-type=boolean, compu {0..1=RANGE, 0=Cx0_Inactive, 1=Cx1_Active}, transfer-property=PENDING, to P2P
          signal SCSAPAAvlblHSC2_oSCS_HSC2_FrP03_oCAN00: start 47, 1 bit, big-endian, init-value=0, base-type=boolean, compu {0..1=RANGE, 0=Cx0_Unavailable, 1=Cx1_Available}, transfer-property=PENDING, to P2P
      frame SCS_HSC2_FrP05_oCAN00: id 0x1E9, to P2P, frame-length=8, can-addressing-mode=STANDARD
        pdu SCS_HSC2_FrP05_oCAN00: length=8, transmission-mode-false-timing=cyclic-timing=time-period=0, transmission-mode-true-timing=cyclic-timing=time-period=0, unused-bit-pattern=0
          signal VSESysAHSC2_oSCS_HSC2_FrP05_oCAN00: start 24, 1 bit, big-endian, init-value=0, base-type=boolean, compu {0..1=RANGE, 0=Cx0_False, 1=Cx1_True}, transfer-property=PENDING, to P2P
          signal TCSAHSC2_oSCS_HSC2_FrP05_oCAN00: start 28, 1 bit, big-endian, init-value=0, base-type=boolean, compu {0..1=RANGE, 0=Cx0_False, 1=Cx1_True}, transfer-property=PENDING, to P2P
          signal ABSAHSC2_oSCS_HSC2_FrP05_oCAN00: start 30, 1 bit, big-endian, init-value=0, base-type=boolean, compu {0..1=RANGE, 0=Cx0_False, 1=Cx1_True}, transfer-property=PENDING, to P2P
          signal VehDynYawRateHSC2_oSCS_HSC2_FrP05_oCAN00: start 35, 12 bit, big-endian, init-value=0, base-type=sint16, compu {-2048=Cx800_deg_s_0xFFFFF800_0x7FF_ (deg/s (0xFFFFF800 - 0x7FF)), phys=raw*0.0625 for raw -2048..2047; unit deg/s}, unit=deg/s, transfer-property=PENDING, to P2P
          signal VehDynYawRateVHSC2_oSCS_HSC2_FrP05_oCAN00: start 36, 1 bit, big-endian, init-value=0, base-type=boolean, compu {0..1=RANGE, 0=Cx0_Valid, 1=Cx1_Invalid}, transfer-property=PENDING, to P2P
      frame SCS_HSC2_FrP11_oCAN00: id 0x348, to P2P, frame-length=8, can-addressing-mode=STANDARD
        pdu SCS_HSC2_FrP11_oCAN00: length=8, transmission-mode-false-timing=cyclic-timing=time-period=0, transmission-mode-true-timing=cyclic-timing=time-period=0, unused-bit-pattern=0
          signal WhlGndVelLDrvnHSC2_oSCS_HSC2_FrP11_oCAN00: start 5, 14 bit, big-endian, init-value=0, base-type=uint16, compu {0=Cx0000_km_h_0x0_0x3FFF_ (km/h (0x0 - 0x3FFF)), phys=raw/32 for raw 0..16383; unit km/h}, unit=km/h, transfer-property=PENDING, to P2P
          signal WhlGndVelLDrvnVHSC2_oSCS_HSC2_FrP11_oCAN00: start 6, 1 bit, big-endian, init-value=1, base-type=boolean, compu {0..1=RANGE, 0=Cx0_Valid, 1=Cx1_Invalid}, transfer-property=PENDING, to P2P  # Wheel Ground Velocity Left Driven Validity
          signal WhlGndVelRDrvnHSC2_oSCS_HSC2_FrP11_oCAN00: start 21, 14 bit, big-endian, init-value=0, base-type=uint16, compu {0=Cx0000_km_h_0x0_0x3FFF_ (km/h (0x0 - 0x3FFF)), phys=raw/32 for raw 0..16383; unit km/h}, unit=km/h, transfer-property=PENDING, to P2P
          signal WhlGndVelRDrvnVHSC2_oSCS_HSC2_FrP11_oCAN00: start 22, 1 bit, big-endian, init-value=1, base-type=boolean, compu {0..1=RANGE, 0=Cx0_Valid, 1=Cx1_Invalid}, transfer-property=PENDING, to P2P  # Wheel Ground Velocity Right Driven Validity
      frame SCS_HSC2_FrP12_oCAN00: id 0x34A, to P2P, frame-length=8, can-addressing-mode=STANDARD
        pdu SCS_HSC2_FrP12_oCAN00: length=8, transmission-mode-false-timing=cyclic-timing=time-period=0, transmission-mode-true-timing=cyclic-timing=time-period=0, unused-bit-pattern=0
          signal WhlGndVelLNonDrvnHSC2_oSCS_HSC2_FrP12_oCAN00: start 5, 14 bit, big-endian, init-value=0, base-type=uint16, compu {0=Cx0000_km_h_0x0_0x3FFF_ (km/h (0x0 - 0x3FFF)), phys=raw/32 for raw 0..16383; unit km/h}, unit=km/h, transfer-property=PENDING, to P2P
          signal WhlGndVelLNonDrvnVHSC2_oSCS_HSC2_FrP12_oCAN00: start 6, 1 bit, big-endian, init-value=1, base-type=boolean, compu {0..1=RANGE, 0=Cx0_Valid, 1=Cx1_Invalid}, transfer-property=PENDING, to P2P  # Wheel Ground Velocity Left Non Driven Validity
          signal WhlGndVelRNonDrvnHSC2_oSCS_HSC2_FrP12_oCAN00: start 21, 14 bit, big-endian, init-value=0, base-type=uint16, compu {0=Cx0000_km_h_0x0_0x3FFF_ (km/h (0x0 - 0x3FFF)), phys=raw/32 for raw 0..16383; unit km/h}, unit=km/h, transfer-property=PENDING, to P2P
          signal WhlGndVelRNonDrvnVHSC2_oSCS_HSC2_FrP12_oCAN00: start 22, 1 bit, big-endian, init-value=1, base-type=boolean, compu {0..1=RANGE, 0=Cx0_Valid, 1=Cx1_Invalid}, transfer-property=PENDING, to P2P  # Wheel Ground Velocity Right Non Driven Validity
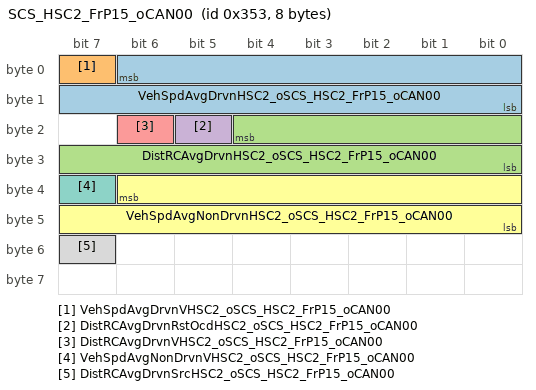
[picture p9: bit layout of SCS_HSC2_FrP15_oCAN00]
      frame SCS_HSC2_FrP15_oCAN00: id 0x353, to P2P, frame-length=8, can-addressing-mode=STANDARD
        pdu SCS_HSC2_FrP15_oCAN00: length=8, transmission-mode-false-timing=cyclic-timing=time-period=0, transmission-mode-true-timing=cyclic-timing=time-period=0, unused-bit-pattern=0
          signal VehSpdAvgDrvnHSC2_oSCS_HSC2_FrP15_oCAN00: start 6, 15 bit, big-endian, init-value=0, base-type=uint16, compu {0=Cx0000_km_h_0x0_0x7FFF_ (km/h (0x0 - 0x7FFF)), phys=raw/64 for raw 0..32766; unit km/h}, unit=km/h, transfer-property=PENDING, to P2P
          signal VehSpdAvgDrvnVHSC2_oSCS_HSC2_FrP15_oCAN00: start 7, 1 bit, big-endian, init-value=0, base-type=boolean, compu {0..1=RANGE, 0=Cx0_Valid, 1=Cx1_Invalid}, transfer-property=PENDING, to P2P
          signal DistRCAvgDrvnHSC2_oSCS_HSC2_FrP15_oCAN00: start 20, 13 bit, big-endian, init-value=0, base-type=uint16, compu {0=Cx0000_m_0x0_0x1FFF_ (m (0x0 - 0x1FFF)), phys=raw*0.125 for raw 0..8191; unit m}, unit=m, transfer-property=PENDING, to P2P
          signal DistRCAvgDrvnRstOcdHSC2_oSCS_HSC2_FrP15_oCAN00: start 21, 1 bit, big-endian, init-value=0, base-type=boolean, compu {0..1=RANGE, 0=Cx0_False, 1=Cx1_True}, transfer-property=PENDING, to P2P
          signal DistRCAvgDrvnVHSC2_oSCS_HSC2_FrP15_oCAN00: start 22, 1 bit, big-endian, init-value=0, base-type=boolean, compu {0..1=RANGE, 0=Cx0_Valid, 1=Cx1_Invalid}, transfer-property=PENDING, to P2P
          signal VehSpdAvgNonDrvnHSC2_oSCS_HSC2_FrP15_oCAN00: start 38, 15 bit, big-endian, init-value=0, base-type=uint16, compu {0=Cx0000_km_h_0x0_0x7FFF_ (km/h (0x0 - 0x7FFF)), phys=raw/64 for raw 0..32766; unit km/h}, unit=km/h, transfer-property=PENDING, to P2P
          signal VehSpdAvgNonDrvnVHSC2_oSCS_HSC2_FrP15_oCAN00: start 39, 1 bit, big-endian, init-value=0, base-type=boolean, compu {0..1=RANGE, 0=Cx0_Valid, 1=Cx1_Invalid}, transfer-property=PENDING, to P2P
          signal DistRCAvgDrvnSrcHSC2_oSCS_HSC2_FrP15_oCAN00: start 55, 1 bit, big-endian, init-value=0, base-type=boolean, compu {0..1=RANGE, 0=Cx0_Transmission_Output_Speed (Transmission Output Speed), 1=Cx1_Wheel_Speed (Wheel Speed)}, transfer-property=PENDING, to P2P  # Distance Rolling Count Average Driven Source
      frame Tester_HSC2_ECM_FrP00_oCAN00: id 0xC9, to P2P, frame-length=8, can-addressing-mode=STANDARD
        pdu Tester_HSC2_ECM_FrP00_oCAN00: length=8, transmission-mode-false-timing=cyclic-timing=time-period=0, transmission-mode-true-timing=cyclic-timing=time-period=0, unused-bit-pattern=0
          signal EnRunAHSC2_oTester_HSC2_ECM_FrP00_oCAN00: start 7, 1 bit, big-endian, init-value=0, base-type=boolean, compu {0..1=RANGE, 0=Cx0_False, 1=Cx1_True}, transfer-property=PENDING, to P2P
      frame Tester_HSC2_GW_FrP14_oCAN00: id 0x1AD, to P2P, frame-length=6, can-addressing-mode=STANDARD
        pdu Tester_HSC2_GW_FrP14_oCAN00: length=6, transmission-mode-false-timing=cyclic-timing=time-period=0, transmission-mode-true-timing=cyclic-timing=time-period=0, unused-bit-pattern=0
          signal NRCDFHSC2_oTester_HSC2_GW_FrP14_oCAN00: start 5, 1 bit, big-endian, init-value=0, base-type=boolean, compu {0..1=RANGE, 0=Cx0_Normal, 1=Cx1_NRCD_failure (NRCD failure)}, transfer-property=PENDING, to P2P  # Near Range Control Drive Failed
          signal NRCDAlvRCHSC2_oTester_HSC2_GW_FrP14_oCAN00: start 39, 8 bit, big-endian, init-value=0, base-type=uint8, compu {0..255=RANGE, 0=Cx00_0x0_0xFF_ ((0x0 - 0xFF))}, transfer-property=PENDING, to P2P  # Near Range Control Drive Alive Rolling Count
  can cluster CAN01: protocol-name=CAN  # 180522-lh1-EP21P2P_P2P_CAN4-V09
    can physical channel CHNL: comm-connectors=CN_CAN01
      frame FICM_HSC4_FrP02_oCAN01: id 0x376, to P2P, frame-length=8, can-addressing-mode=STANDARD
        pdu FICM_HSC4_FrP02_oCAN01: length=8, transmission-mode-false-timing=cyclic-timing=time-period=0, transmission-mode-true-timing=cyclic-timing=time-period=0, unused-bit-pattern=0
          signal RstrFctryDeftsReqHSC4_oFICM_HSC4_FrP02_oCAN01: start 56, 1 bit, big-endian, init-value=0, base-type=boolean, compu {0..1=RANGE, 0=Cx0_False, 1=Cx1_True}, transfer-property=PENDING, to P2P
      frame FICM_HSC4_FrP08_oCAN01: id 0x2F6, to P2P, frame-length=8, can-addressing-mode=STANDARD
        pdu FICM_HSC4_FrP08_oCAN01: length=8, transmission-mode-false-timing=cyclic-timing=time-period=0, transmission-mode-true-timing=cyclic-timing=time-period=0, unused-bit-pattern=0
          signal APASwReqHSC4_oFICM_HSC4_FrP08_oCAN01: start 59, 2 bit, big-endian, init-value=0, base-type=uint8, compu {0..3=RANGE, 0=Cx0_No_request (No request), 1=Cx1_Short_press (Short press), 2=Cx2_Long_press (Long press), 3=Cx3_Reserved}, transfer-property=PENDING, to P2P
          signal PDCSwReqHSC4_oFICM_HSC4_FrP08_oCAN01: start 61, 2 bit, big-endian, init-value=0, base-type=uint8, compu {0..3=RANGE, 0=Cx0_No_request (No request), 1=Cx1_Short_press (Short press), 2=Cx2_Long_press (Long press), 3=Cx3_Reserved}, transfer-property=PENDING, to P2P
      frame FICM_HSC4_FrP13_oCAN01: id 0x2F2, to P2P, frame-length=8, can-addressing-mode=STANDARD
        pdu FICM_HSC4_FrP13_oCAN01: length=8, transmission-mode-false-timing=cyclic-timing=time-period=0, transmission-mode-true-timing=cyclic-timing=time-period=0, unused-bit-pattern=0
          signal AlisysrdyHSC4_oFICM_HSC4_FrP13_oCAN01: start 50, 1 bit, big-endian, init-value=0, base-type=boolean, compu {0..1=RANGE, 0=Cx0_not_ready (not ready), 1=Cx1_ready}, transfer-property=PENDING, to P2P
      frame FICM_HSC4_FrP18_oCAN01: id 0x37D, to P2P, frame-length=8, can-addressing-mode=STANDARD
        pdu FICM_HSC4_FrP18_oCAN01: length=8, transmission-mode-false-timing=cyclic-timing=time-period=0, transmission-mode-true-timing=cyclic-timing=time-period=0, unused-bit-pattern=0
          signal DrvrSelAPAParkngMdHSC4_oFICM_HSC4_FrP18_oCAN01: start 0, 3 bit, big-endian, init-value=0, base-type=uint8, compu {0..7=RANGE, 0=Cx0_No_select (No select), 1=Cx1_Select_parallel_parking (Select parallel parking), 2=Cx2_Select_perpendicular_parking (Select perpendicular parking), 3=Cx3_Select_park_in (Select park in), 4=Cx4_Select_park_out (Select park out), 5=Cx5_Reserved, 6=Cx6_Reserved, 7=Cx7_Reserved}, transfer-property=PENDING, to P2P  # Driver Select Advanced Park Assist Parking Mode
          signal DrvrSelAPASlotBearngHSC4_oFICM_HSC4_FrP18_oCAN01: start 6, 2 bit, big-endian, init-value=0, base-type=uint8, compu {0..3=RANGE, 0=Cx0_No_select (No select), 1=Cx1_Select_Left_slot (Select Left slot), 2=Cx2_Select_Right_slot (Select Right slot), 3=Cx3_Reserved}, transfer-property=PENDING, to P2P
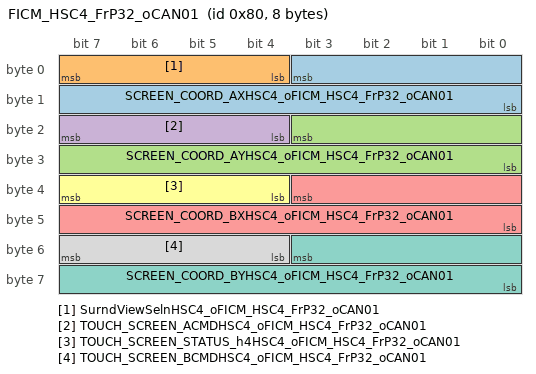
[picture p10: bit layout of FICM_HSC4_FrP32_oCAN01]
      frame FICM_HSC4_FrP32_oCAN01: id 0x80, to P2P, frame-length=8, can-addressing-mode=STANDARD
        pdu FICM_HSC4_FrP32_oCAN01: length=8, transmission-mode-false-timing=cyclic-timing=time-period=0, transmission-mode-true-timing=cyclic-timing=time-period=0, unused-bit-pattern=0
          signal SCREEN_COORD_AXHSC4_oFICM_HSC4_FrP32_oCAN01: start 3, 12 bit, big-endian, init-value=0, base-type=uint16, compu {0..4095=RANGE, 0=Cx000_0x0_0xFFF_ ((0x0 - 0xFFF))}, transfer-property=PENDING, to P2P
          signal SurndViewSelnHSC4_oFICM_HSC4_FrP32_oCAN01: start 7, 4 bit, big-endian, init-value=0, base-type=uint8, compu {0..15=RANGE, 0=Cx0_No_request (No request), 1=Cx1_front_view, 2=Cx2_front_view_wide, 3=Cx3_Rear_view, 4=Cx4_2D_Rear_view_wide, 5=Cx5_left_right_view_wide, 6=Cx6_front_left_view_3D_ (front_left_view(3D)), 7=Cx7_front_right_view_3D_ (front_right_view(3D)), 8=Cx8_rear_left_view_3D_ (rear_left_view(3D)), 9=Cx9_rear_right_view_3D_ (rear_right_view(3D)), 10=CxA_full_screen, 11=CxB_Reserved, 12=CxC_Reserved, 13=CxD_Reserved, 14=CxE_Reserved, 15=CxF_Reserved}, transfer-property=PENDING, to P2P
          signal SCREEN_COORD_AYHSC4_oFICM_HSC4_FrP32_oCAN01: start 19, 12 bit, big-endian, init-value=0, base-type=uint16, compu {0..4095=RANGE, 0=Cx000_0x0_0xFFF_ ((0x0 - 0xFFF))}, transfer-property=PENDING, to P2P
          signal TOUCH_SCREEN_ACMDHSC4_oFICM_HSC4_FrP32_oCAN01: start 23, 4 bit, big-endian, init-value=0, base-type=uint8, compu {0..15=RANGE, 0=Cx0_No_command, 1=Cx1_Screen_touched (Screen touched), 2=Cx2_Screen_hold_reserved_ (Screen hold(reserved)), 3=Cx3_Screen_release (Screen release), 4=Cx4_Reserved, 5=Cx5_Reserved, 6=Cx6_Reserved, 7=Cx7_Reserved, 8=Cx8_Reserved, 9=Cx9_Reserved, 10=CxA_Reserved, 11=CxB_Reserved, 12=CxC_Reserved, 13=CxD_Reserved, 14=CxE_Reserved, 15=CxF_Reserved}, transfer-property=PENDING, to P2P
          signal SCREEN_COORD_BXHSC4_oFICM_HSC4_FrP32_oCAN01: start 35, 12 bit, big-endian, init-value=0, base-type=uint16, compu {0..4095=RANGE, 0=Cx000_0x0_0xFFF_ ((0x0 - 0xFFF))}, transfer-property=PENDING, to P2P
          signal TOUCH_SCREEN_STATUS_h4HSC4_oFICM_HSC4_FrP32_oCAN01: start 39, 4 bit, big-endian, init-value=0, base-type=uint8, compu {0..15=RANGE, 0=Cx0_No_command (No command), 1=Cx1_double_point_touch (double point touch), 2=Cx2_one_point_touch (one point touch), 3=Cx3_one_point_swipe (one point swipe), 4=Cx4_Reserved, 5=Cx5_Reserved, 6=Cx6_Reserved, 7=Cx7_Reserved, 8=Cx8_Reserved, 9=Cx9_Reserved, 10=CxA_Reserved, 11=CxB_Reserved, 12=CxC_Reserved, 13=CxD_Reserved, 14=CxE_Reserved, 15=CxF_Reserved}, transfer-property=PENDING, to P2P
          signal SCREEN_COORD_BYHSC4_oFICM_HSC4_FrP32_oCAN01: start 51, 12 bit, big-endian, init-value=0, base-type=uint16, compu {0..4095=RANGE, 0=Cx000_0x0_0xFFF_ ((0x0 - 0xFFF))}, transfer-property=PENDING, to P2P
          signal TOUCH_SCREEN_BCMDHSC4_oFICM_HSC4_FrP32_oCAN01: start 55, 4 bit, big-endian, init-value=0, base-type=uint8, compu {0..15=RANGE, 0=Cx0_No_command, 1=Cx1_Screen_touched (Screen touched), 2=Cx2_Screen_hold_reserved_ (Screen hold(reserved)), 3=Cx3_Screen_release (Screen release), 4=Cx4_Reserved, 5=Cx5_Reserved, 6=Cx6_Reserved, 7=Cx7_Reserved, 8=Cx8_Reserved, 9=Cx9_Reserved, 10=CxA_Reserved, 11=CxB_Reserved, 12=CxC_Reserved, 13=CxD_Reserved, 14=CxE_Reserved, 15=CxF_Reserved}, transfer-property=PENDING, to P2P
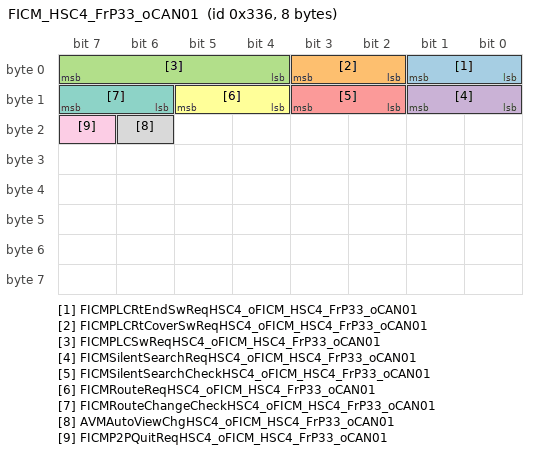
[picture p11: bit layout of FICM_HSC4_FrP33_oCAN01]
      frame FICM_HSC4_FrP33_oCAN01: id 0x336, to P2P, frame-length=8, can-addressing-mode=STANDARD
        pdu FICM_HSC4_FrP33_oCAN01: length=8, transmission-mode-false-timing=cyclic-timing=time-period=0, transmission-mode-true-timing=cyclic-timing=time-period=0, unused-bit-pattern=0
          signal FICMPLCRtEndSwReqHSC4_oFICM_HSC4_FrP33_oCAN01: start 1, 2 bit, big-endian, init-value=0, base-type=uint8, compu {0..3=RANGE, 0=Cx0_Initial, 1=Cx1_NO, 2=Cx2_YES}, transfer-property=PENDING, to P2P
          signal FICMPLCRtCoverSwReqHSC4_oFICM_HSC4_FrP33_oCAN01: start 3, 2 bit, big-endian, init-value=0, base-type=uint8, compu {0..3=RANGE, 0=Cx0_Initial, 1=Cx1_NO, 2=Cx2_YES}, transfer-property=PENDING, to P2P
          signal FICMPLCSwReqHSC4_oFICM_HSC4_FrP33_oCAN01: start 7, 4 bit, big-endian, init-value=0, base-type=uint8, compu {0..15=RANGE, 0=Cx0_No_Request (No Request), 1=Cx1_Start_Routelearning (Start Routelearning), 2=Cx2_Finish_Routelearning (Finish Routelearning), 3=Cx3_Cancel_Routelearning (Cancel Routelearning), 4=Cx4_Save_Route1 (Save Route1), 5=Cx5_Save_Route2 (Save Route2), 6=Cx6_Delete_Route1 (Delete Route1), 7=Cx7_Delete_Route2 (Delete Route2), 8=Cx8_Reserved_for_Route3 (Reserved for Route3), 9=Cx9_Reserved_for_Route3 (Reserved for Route3), 10=CxA_Reserved_for_Route3 (Reserved for Route3), 11=CxB_Reserved_for_Route3 (Reserved for Route3), 12=CxC_Reserved_for_Route3 (Reserved for Route3), 13=CxD_Reserved_for_Route3 (Reserved for Route3), 14=CxE_Reserved_for_Route3 (Reserved for Route3), 15=CxF_Reserved_for_Route3 (Reserved for Route3)}, transfer-property=PENDING, to P2P
          signal FICMSilentSearchReqHSC4_oFICM_HSC4_FrP33_oCAN01: start 9, 2 bit, big-endian, init-value=0, base-type=uint8, compu {0..3=RANGE, 0=Cx0_no_request (no request), 1=Cx1_Route1, 2=Cx2_Route2, 3=Cx3_Reserved}, transfer-property=PENDING, to P2P
          signal FICMSilentSearchCheckHSC4_oFICM_HSC4_FrP33_oCAN01: start 11, 2 bit, big-endian, init-value=0, base-type=uint8, compu {0..3=RANGE, 0=Cx0_0, 1=Cx1_YES, 2=Cx2_NO, 3=Cx3_Reserved}, transfer-property=PENDING, to P2P
          signal FICMRouteReqHSC4_oFICM_HSC4_FrP33_oCAN01: start 13, 2 bit, big-endian, init-value=0, base-type=uint8, compu {0..3=RANGE, 0=Cx0_no_request (no request), 1=Cx1_Route1, 2=Cx2_Route2, 3=Cx3_Reserved}, transfer-property=PENDING, to P2P
          signal FICMRouteChangeCheckHSC4_oFICM_HSC4_FrP33_oCAN01: start 15, 2 bit, big-endian, init-value=0, base-type=uint8, compu {0..3=RANGE, 0=Cx0_0, 1=Cx1_YES, 2=Cx2_NO, 3=Cx3_Reserved}, transfer-property=PENDING, to P2P
          signal AVMAutoViewChgHSC4_oFICM_HSC4_FrP33_oCAN01: start 22, 1 bit, big-endian, init-value=0, base-type=boolean, compu {0..1=RANGE, 0=Cx0_Autonoums, 1=Cx1_Manual}, transfer-property=PENDING, to P2P
          signal FICMP2PQuitReqHSC4_oFICM_HSC4_FrP33_oCAN01: start 23, 1 bit, big-endian, init-value=0, base-type=boolean, compu {0..1=RANGE, 0=Cx0_False, 1=Cx1_True}, transfer-property=PENDING, to P2P
      frame GW_HSC4_BCM_FrP04_oCAN01: id 0x46A, to P2P, frame-length=8, can-addressing-mode=STANDARD
        pdu GW_HSC4_BCM_FrP04_oCAN01: length=8, transmission-mode-false-timing=cyclic-timing=time-period=0, transmission-mode-true-timing=cyclic-timing=time-period=0, unused-bit-pattern=0
          signal VehLckngStaHSC4_oGW_HSC4_BCM_FrP04_oCAN01: start 55, 3 bit, big-endian, init-value=7, base-type=uint8, compu {0..7=RANGE, 0=Cx0_Unlocked, 1=Cx1_Signal_Position_Entry_Unlocked (Signal Position Entry Unlocked), 2=Cx2_Interior_Locked (Interior Locked), 3=Cx3_Exterior_Locked (Exterior Locked), 4=Cx4_Super_locked (Super locked), 5=Cx5_Reserved, 6=Cx6_Reserved, 7=Cx7_Unknow}, transfer-property=PENDING, to P2P  # Vehicle Locking State
      frame GW_HSC4_BCM_FrS09_oCAN01: id 0x3C, to P2P, frame-length=8, can-addressing-mode=STANDARD
        pdu GW_HSC4_BCM_FrS09_oCAN01: length=8, unused-bit-pattern=0
          signal BCMImmoData4HSC4_oGW_HSC4_BCM_FrS09_oCAN01: start 0, 64 bit, opaque, init-value=8 x 0, base-type=uint8_8_iso_8859_1, compu {0..18446744073709551615=RANGE}, transfer-property=PENDING, to P2P
      frame GW_HSC4_BCM_FrS10_oCAN01: id 0x3D, to P2P, frame-length=8, can-addressing-mode=STANDARD
        pdu GW_HSC4_BCM_FrS10_oCAN01: length=8, unused-bit-pattern=0
          signal BCMImmoData5HSC4_oGW_HSC4_BCM_FrS10_oCAN01: start 0, 64 bit, opaque, init-value=8 x 0, base-type=uint8_8_iso_8859_1, compu {0..18446744073709551615=RANGE}, transfer-property=PENDING, to P2P
      frame GW_HSC4_BMS_FrP07_oCAN01: id 0x29B, to P2P, frame-length=8, can-addressing-mode=STANDARD
        pdu GW_HSC4_BMS_FrP07_oCAN01: length=8, transmission-mode-false-timing=cyclic-timing=time-period=0, transmission-mode-true-timing=cyclic-timing=time-period=0, unused-bit-pattern=0
          signal BMSBscSta_h1HSC4_oGW_HSC4_BMS_FrP07_oCAN01: start 5, 5 bit, big-endian, init-value=0, base-type=uint8, compu {0..31=RANGE, 0=Cx00_Power_Up (Power Up), 1=Cx01_Drive_Ready (Drive Ready), 2=Cx02_Drive_Pre_charging (Drive Pre-charging), 3=Cx03_Drive_Mode (Drive Mode), 4=Cx04_On_board_Charge_Ready (On-board Charge Ready), 5=Cx05_Off_board_Charge_Ready (Off-board Charge Ready), 6=Cx06_On_board_Charging_Mode (On-board Charging Mode), 7=Cx07_Off_board_Charging_Mode (Off-board Charging Mode), 8=Cx08_Offline_Balance (Offline Balance), 9=Cx09_Off_board_Charging_Done (Off-board Charging Done), 10=Cx0A_On_board_Charging_Done (On-board Charging Done), 12=Cx0C_On_board_Pre_charging (On-board Pre-charging), 13=Cx0D_Collision_Mode (Collision Mode), 14=Cx0E_Balancing, 15=Cx0F_Fault, 16=Cx10_Off_board_Pre_charging (Off-board Pre-charging), 17=Cx11_Wireless_Charge_Ready (Wireless Charge Ready), 18=Cx12_Wireless_Charging_Mode (Wireless Charging Mode), 19=Cx13_Wireless_Charging_Done (Wireless Charging Done), 20=Cx14_Wireless_Pre_charging (Wireless Pre-charging)}, transfer-property=PENDING, to P2P
      frame GW_HSC4_PEPS_FrP01_oCAN01: id 0x17B, to P2P, frame-length=8, can-addressing-mode=STANDARD
        pdu GW_HSC4_PEPS_FrP01_oCAN01: length=8, transmission-mode-false-timing=cyclic-timing=time-period=0, transmission-mode-true-timing=cyclic-timing=time-period=0, unused-bit-pattern=0
          signal PEPSSSBAHSC4_oGW_HSC4_PEPS_FrP01_oCAN01: start 56, 1 bit, big-endian, init-value=0, base-type=boolean, compu {0..1=RANGE, 0=Cx0_False, 1=Cx1_True}, transfer-property=PENDING, to P2P
          signal FRDoorHadlSwAHSC4_oGW_HSC4_PEPS_FrP01_oCAN01: start 58, 1 bit, big-endian, init-value=0, base-type=boolean, compu {0..1=RANGE, 0=Cx0_False, 1=Cx1_True}, transfer-property=PENDING, to P2P  # Front Right Door Handle Switch Active
          signal FLDoorHadlSwAHSC4_oGW_HSC4_PEPS_FrP01_oCAN01: start 59, 1 bit, big-endian, init-value=0, base-type=boolean, compu {0..1=RANGE, 0=Cx0_False, 1=Cx1_True}, transfer-property=PENDING, to P2P  # Front Left Door Handle Switch Active
          signal PEPSSSBAVHSC4_oGW_HSC4_PEPS_FrP01_oCAN01: start 61, 1 bit, big-endian, init-value=0, base-type=boolean, compu {0..1=RANGE, 0=Cx0_Valid, 1=Cx1_Invalid}, transfer-property=PENDING, to P2P
      frame GW_HSC4_PEPS_FrP02_oCAN01: id 0x239, to P2P, frame-length=8, can-addressing-mode=STANDARD
        pdu GW_HSC4_PEPS_FrP02_oCAN01: length=8, transmission-mode-false-timing=cyclic-timing=time-period=0, transmission-mode-true-timing=cyclic-timing=time-period=0, unused-bit-pattern=0
          signal PEPSSSBFltStsHSC4_oGW_HSC4_PEPS_FrP02_oCAN01: start 54, 3 bit, big-endian, init-value=0, base-type=uint8, compu {0..7=RANGE, 0=Cx0_No_Fault (No Fault), 1=Cx1_short_to_GND (short to GND), 2=Cx2_short_to_Battery (short to Battery), 3=Cx3_Stuck, 4=Cx4_Open_Circuit (Open Circuit), 5=Cx5_switch_failed (switch failed), 6=Cx6_Reserved_, 7=Cx7_Reserved_}, transfer-property=PENDING, to P2P
      frame GW_HSC4_TBOX_FrP01_oCAN01: id 0x34D, to P2P, frame-length=8, can-addressing-mode=STANDARD
        pdu GW_HSC4_TBOX_FrP01_oCAN01: length=8, transmission-mode-false-timing=cyclic-timing=time-period=0, transmission-mode-true-timing=cyclic-timing=time-period=0, unused-bit-pattern=0
          signal P2PSwReqHSC4_oGW_HSC4_TBOX_FrP01_oCAN01: start 15, 1 bit, big-endian, init-value=0, base-type=boolean, compu {0..1=RANGE, 0=Cx0_False, 1=Cx1_True}, transfer-property=PENDING, to P2P
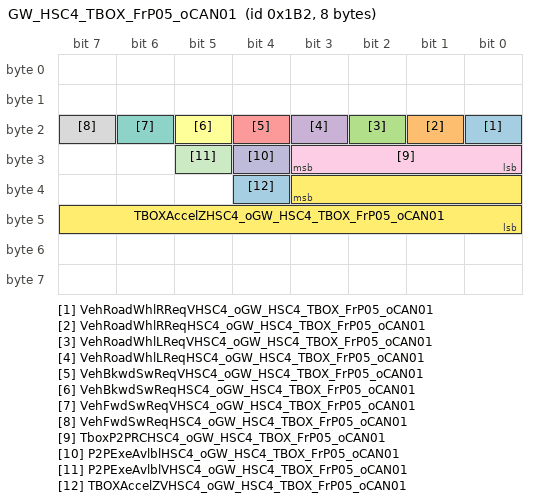
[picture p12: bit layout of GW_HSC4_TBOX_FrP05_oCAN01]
      frame GW_HSC4_TBOX_FrP05_oCAN01: id 0x1B2, to P2P, frame-length=8, can-addressing-mode=STANDARD
        pdu GW_HSC4_TBOX_FrP05_oCAN01: length=8, transmission-mode-false-timing=cyclic-timing=time-period=0, transmission-mode-true-timing=cyclic-timing=time-period=0, unused-bit-pattern=0
          signal VehRoadWhlRReqVHSC4_oGW_HSC4_TBOX_FrP05_oCAN01: start 16, 1 bit, big-endian, init-value=0, base-type=boolean, compu {0..1=RANGE, 0=Cx0_Valid, 1=Cx1_Invalid}, transfer-property=PENDING, to P2P  # Vehicle Road Wheel Right Request Validity
          signal VehRoadWhlRReqHSC4_oGW_HSC4_TBOX_FrP05_oCAN01: start 17, 1 bit, big-endian, init-value=0, base-type=boolean, compu {0..1=RANGE, 0=Cx0_False, 1=Cx1_True}, transfer-property=PENDING, to P2P  # Vehicle Road Wheel Right Request
          signal VehRoadWhlLReqVHSC4_oGW_HSC4_TBOX_FrP05_oCAN01: start 18, 1 bit, big-endian, init-value=0, base-type=boolean, compu {0..1=RANGE, 0=Cx0_Valid, 1=Cx1_Invalid}, transfer-property=PENDING, to P2P  # Vehicle Road Wheel Left Request Validity
          signal VehRoadWhlLReqHSC4_oGW_HSC4_TBOX_FrP05_oCAN01: start 19, 1 bit, big-endian, init-value=0, base-type=boolean, compu {0..1=RANGE, 0=Cx0_False, 1=Cx1_True}, transfer-property=PENDING, to P2P  # Vehicle Road Wheel Left Request
          signal VehBkwdSwReqVHSC4_oGW_HSC4_TBOX_FrP05_oCAN01: start 20, 1 bit, big-endian, init-value=0, base-type=boolean, compu {0..1=RANGE, 0=Cx0_Valid, 1=Cx1_Invalid}, transfer-property=PENDING, to P2P  # Vehicle Backward Switch Request Validity
          signal VehBkwdSwReqHSC4_oGW_HSC4_TBOX_FrP05_oCAN01: start 21, 1 bit, big-endian, init-value=0, base-type=boolean, compu {0..1=RANGE, 0=Cx0_False, 1=Cx1_True}, transfer-property=PENDING, to P2P  # Vehicle Backward Switch Request
          signal VehFwdSwReqVHSC4_oGW_HSC4_TBOX_FrP05_oCAN01: start 22, 1 bit, big-endian, init-value=0, base-type=boolean, compu {0..1=RANGE, 0=Cx0_Valid, 1=Cx1_Invalid}, transfer-property=PENDING, to P2P  # Vehicle Forward Switch Request Validity
          signal VehFwdSwReqHSC4_oGW_HSC4_TBOX_FrP05_oCAN01: start 23, 1 bit, big-endian, init-value=0, base-type=boolean, compu {0..1=RANGE, 0=Cx0_False, 1=Cx1_True}, transfer-property=PENDING, to P2P  # Vehicle Forward Switch Request
          signal TboxP2PRCHSC4_oGW_HSC4_TBOX_FrP05_oCAN01: start 27, 4 bit, big-endian, init-value=0, base-type=uint8, compu {0..15=RANGE, 0=Cx0_0x0_0xF_ ((0x0 - 0xF))}, transfer-property=PENDING, to P2P
          signal P2PExeAvlblHSC4_oGW_HSC4_TBOX_FrP05_oCAN01: start 28, 1 bit, big-endian, init-value=0, base-type=boolean, compu {0..1=RANGE, 0=Cx0_unavailable, 1=Cx1_available}, transfer-property=PENDING, to P2P
          signal P2PExeAvlblVHSC4_oGW_HSC4_TBOX_FrP05_oCAN01: start 29, 1 bit, big-endian, init-value=0, base-type=boolean, compu {0..1=RANGE, 0=Cx0_Valid, 1=Cx1_Invalid}, transfer-property=PENDING, to P2P
          signal TBOXAccelZHSC4_oGW_HSC4_TBOX_FrP05_oCAN01: start 35, 12 bit, big-endian, init-value=0, base-type=sint16, compu {-2048=Cx800_m_s2_0xFFFFF800_0x7FF_ (m/s2 (0xFFFFF800 - 0x7FF)), phys=raw/64 for raw -2048..2047; unit m/s2}, unit=m/s2, transfer-property=PENDING, to P2P
          signal TBOXAccelZVHSC4_oGW_HSC4_TBOX_FrP05_oCAN01: start 36, 1 bit, big-endian, init-value=0, base-type=boolean, compu {0..1=RANGE, 0=Cx0_Valid, 1=Cx1_Invalid}, transfer-property=PENDING, to P2P
      frame GW_HSC4_TBOX_FrS10_oCAN01: id 0x611, to P2P, frame-length=8, can-addressing-mode=STANDARD
        pdu GW_HSC4_TBOX_FrS10_oCAN01: length=8, unused-bit-pattern=0
          signal TBOXToIECUCtrlPotclHSC4_oGW_HSC4_TBOX_FrS10_oCAN01: start 0, 64 bit, opaque, init-value=8 x 0, base-type=uint8_8_iso_8859_1, compu {0..18446744073709551615=RANGE}, transfer-property=PENDING, to P2P
      frame GW_HSC4_TC_FrP01_oCAN01: id 0x94, to P2P, frame-length=8, can-addressing-mode=STANDARD
        pdu GW_HSC4_TC_FrP01_oCAN01: length=8, transmission-mode-false-timing=cyclic-timing=time-period=0, transmission-mode-true-timing=cyclic-timing=time-period=0, unused-bit-pattern=0
          signal TMSpd_h1HSC4_oGW_HSC4_TC_FrP01_oCAN01: start 7, 16 bit, big-endian, init-value=32768, base-type=uint16, compu {0=Cx0000_rpm_0x0_0xFFFF_ (rpm (0x0 - 0xFFFF)), phys=raw-32768 for raw 0..65535; unit rpm}, unit=rpm, transfer-property=PENDING, to P2P
          signal TMSpdV_h1HSC4_oGW_HSC4_TC_FrP01_oCAN01: start 23, 1 bit, big-endian, init-value=1, base-type=boolean, compu {0..1=RANGE, 0=Cx0_Valid, 1=Cx1_Invalid}, transfer-property=PENDING, to P2P
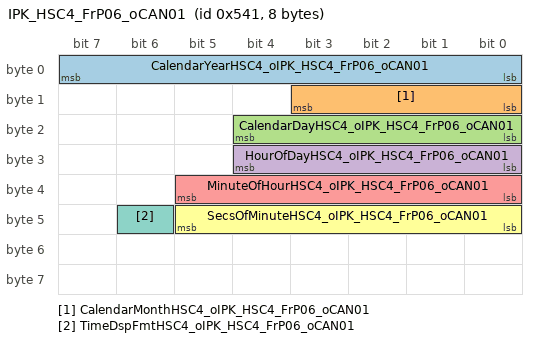
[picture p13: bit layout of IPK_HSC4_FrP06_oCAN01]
      frame IPK_HSC4_FrP06_oCAN01: id 0x541, to P2P, frame-length=8, can-addressing-mode=STANDARD
        pdu IPK_HSC4_FrP06_oCAN01: length=8, transmission-mode-false-timing=cyclic-timing=time-period=0, transmission-mode-true-timing=cyclic-timing=time-period=0, unused-bit-pattern=0
          signal CalendarYearHSC4_oIPK_HSC4_FrP06_oCAN01: start 7, 8 bit, big-endian, init-value=0, base-type=uint8, compu {0=Cx00_year_0x0_0xFF_ (year (0x0 - 0xFF)), phys=raw+2000 for raw 0..255; unit year}, unit=year, transfer-property=PENDING, to P2P
          signal CalendarMonthHSC4_oIPK_HSC4_FrP06_oCAN01: start 11, 4 bit, big-endian, init-value=0, base-type=uint8, compu {0..15=RANGE, 0=Cx0_Unknown, 1=Cx1_January, 2=Cx2_February, 3=Cx3_March, 4=Cx4_April, 5=Cx5_May, 6=Cx6_June, 7=Cx7_July, 8=Cx8_August, 9=Cx9_September, 10=CxA_October, 11=CxB_November, 12=CxC_December}, transfer-property=PENDING, to P2P
          signal CalendarDayHSC4_oIPK_HSC4_FrP06_oCAN01: start 20, 5 bit, big-endian, init-value=0, base-type=uint8, compu {0..31=RANGE, 0=Cx00_days_0x0_0x1F_ (days (0x0 - 0x1F)); unit days}, unit=days, transfer-property=PENDING, to P2P
          signal HourOfDayHSC4_oIPK_HSC4_FrP06_oCAN01: start 28, 5 bit, big-endian, init-value=0, base-type=uint8, compu {0..23=RANGE, 0=Cx00_0x0_0x17_ ((0x0 - 0x17))}, transfer-property=PENDING, to P2P
          signal MinuteOfHourHSC4_oIPK_HSC4_FrP06_oCAN01: start 37, 6 bit, big-endian, init-value=0, base-type=uint8, compu {0..59=RANGE, 0=Cx00_0x0_0x3B_ ((0x0 - 0x3B))}, transfer-property=PENDING, to P2P
          signal SecsOfMinuteHSC4_oIPK_HSC4_FrP06_oCAN01: start 45, 6 bit, big-endian, init-value=0, base-type=uint8, compu {0..59=RANGE, 0=Cx00_0x0_0x3B_ ((0x0 - 0x3B))}, transfer-property=PENDING, to P2P
          signal TimeDspFmtHSC4_oIPK_HSC4_FrP06_oCAN01: start 46, 1 bit, big-endian, init-value=0, base-type=boolean, compu {0..1=RANGE, 0=Cx0_12_hour_mode (12 hour mode), 1=Cx1_24_hour_mode (24 hour mode)}, transfer-property=PENDING, to P2P
      frame P2P_HSC4_FrP03_oCAN01: id 0x30D, from P2P, frame-length=8, can-addressing-mode=STANDARD
        pdu P2P_HSC4_FrP03_oCAN01: length=8, transmission-mode-false-timing=cyclic-timing=time-period=0, transmission-mode-true-timing=cyclic-timing=time-period=0, unused-bit-pattern=0
          signal P2PACTMdChngTmotHSC4_oP2P_HSC4_FrP03_oCAN01: start 7, 8 bit, big-endian, init-value=0, base-type=uint8, compu {0..255=RANGE, 0=Cx00_s_0x0_0xFF_ (s (0x0 - 0xFF)); unit s}, unit=s, transfer-property=PENDING
          signal P2PDisplayHSC4_oP2P_HSC4_FrP03_oCAN01: start 15, 8 bit, big-endian, init-value=0, base-type=uint8, compu {0..255=RANGE, 0=Cx00_0x0_0xFF_ ((0x0 - 0xFF))}, transfer-property=PENDING
          signal Route2StateHSC4_oP2P_HSC4_FrP03_oCAN01: start 17, 2 bit, big-endian, init-value=0, base-type=uint8, compu {0..3=RANGE, 0=Cx0_No_route (No route), 1=Cx1_Route_exist (Route exist), 2=Cx2_Saving}, transfer-property=PENDING
          signal Route1StateHSC4_oP2P_HSC4_FrP03_oCAN01: start 19, 2 bit, big-endian, init-value=0, base-type=uint8, compu {0..3=RANGE, 0=Cx0_No_route (No route), 1=Cx1_Route_exist (Route exist), 2=Cx2_Saving}, transfer-property=PENDING
          signal P2PProgressHSC4_oP2P_HSC4_FrP03_oCAN01: start 23, 4 bit, big-endian, init-value=0, base-type=uint8, compu {0..15=RANGE, 0=Cx0_0_ (0%), 1=Cx1_10_ (10%), 2=Cx2_20_ (20%), 3=Cx3_30_ (30%), 4=Cx4_40_ (40%), 5=Cx5_50_ (50%), 6=Cx6_60_ (60%), 7=Cx7_70_ (70%), 8=Cx8_80_ (80%), 9=Cx9_90_ (90%), 10=CxA_100_ (100%), 15=CxF_No_request (No request)}, transfer-property=PENDING
          signal Route1SavePercentageHSC4_oP2P_HSC4_FrP03_oCAN01: start 30, 7 bit, big-endian, init-value=0, base-type=uint8, compu {0=Cx00_0x0_0x7F_ ((0x0 - 0x7F)), phys=raw*0.01 for raw 0..127}, transfer-property=PENDING
          signal Route2SavePercentageHSC4_oP2P_HSC4_FrP03_oCAN01: start 38, 7 bit, big-endian, init-value=0, base-type=uint8, compu {0=Cx00_0x0_0x7F_ ((0x0 - 0x7F)), phys=raw*0.01 for raw 0..127}, transfer-property=PENDING
      frame P2P_HSC4_FrS01_oCAN01: id 0x60F, from P2P, frame-length=8, can-addressing-mode=STANDARD
        pdu P2P_HSC4_FrS01_oCAN01: length=8, unused-bit-pattern=0
          signal IECUToTBOXCtrlPotclHSC4_oP2P_HSC4_FrS01_oCAN01: start 0, 64 bit, opaque, init-value=8 x 0, base-type=uint8_8_iso_8859_1, compu {0..18446744073709551615=RANGE}, transfer-property=PENDING
      frame P2P_IECU_HSC4_FrP01_oCAN01: id 0x2FC, from P2P, frame-length=8, can-addressing-mode=STANDARD
        pdu P2P_IECU_HSC4_FrP01_oCAN01: length=8, transmission-mode-false-timing=cyclic-timing=time-period=0, transmission-mode-true-timing=cyclic-timing=time-period=0, unused-bit-pattern=0
          signal HD_AVMsysrdyHSC4_oP2P_IECU_HSC4_FrP01_oCAN01: start 40, 1 bit, big-endian, init-value=0, base-type=boolean, compu {0..1=RANGE, 0=Cx0_not_ready (not ready), 1=Cx1_ready}, transfer-property=PENDING
          signal HD_AVMCurViewHSC4_oP2P_IECU_HSC4_FrP01_oCAN01: start 51, 4 bit, big-endian, init-value=0, base-type=uint8, compu {0..15=RANGE, 0=Cx0_No_request (No request), 1=Cx1_front_view, 2=Cx2_front_view_wide, 3=Cx3_Rear_view, 4=Cx4_2D_Rear_view_wide, 5=Cx5_left_right_view_wide, 6=Cx6_front_left_view_3D_ (front_left_view(3D)), 7=Cx7_front_right_view_3D_ (front_right_view(3D)), 8=Cx8_rear_left_view_3D_ (rear_left_view(3D)), 9=Cx9_rear_right_view_3D_ (rear_right_view(3D)), 10=CxA_full_screen, 11=CxB_Reserved, 12=CxC_Reserved, 13=CxD_Reserved, 14=CxE_Reserved, 15=CxF_Reserved}, transfer-property=PENDING
          signal HD_AVMVideoFmtStaHSC4_oP2P_IECU_HSC4_FrP01_oCAN01: start 55, 4 bit, big-endian, init-value=0, base-type=uint8, compu {0..15=RANGE, 0=Cx0_Unlocked, 1=Cx1_1440_640 (1440*640), 2=Cx2_1200_900 (1200*900), 3=Cx3_FIRST_DRIVE, 4=Cx4_PDC_detected, 5=Cx5_Reserved, 6=Cx6_Reserved, 7=Cx7_Reserved, 8=Cx8_Reserved, 9=Cx9_Reserved, 10=CxA_Reserved, 11=CxB_Reserved, 12=CxC_Reserved, 13=CxD_Reserved, 14=CxE_Reserved, 15=CxF_Reserved}, transfer-property=PENDING
          signal HD_AVMErrorDisplay_h4HSC4_oP2P_IECU_HSC4_FrP01_oCAN01: start 59, 4 bit, big-endian, init-value=0, base-type=uint8, compu {0..15=RANGE, 0=Cx0_No_Request (No Request), 1=Cx1_Cameras_Failure (Cameras Failure), 2=Cx2_Radar_Failure (Radar Failure), 3=Cx3_Auxilirary_Line_Failre (Auxilirary Line Failre), 4=Cx4_Transparent_Car_Function_Failure (Transparent Car Function Failure), 5=Cx5_MOD_Function_Failure (MOD Function Failure), 6=Cx6_EOL_After_Sale_Calibration_Function_Failure (EOL/After Sale Calibration Function Failure), 7=Cx7_reserved, 8=Cx8_reserved, 9=Cx9_reserved, 10=CxA_reserved, 11=CxB_reserved, 12=CxC_reserved, 13=CxD_reserved, 14=CxE_reserved, 15=CxF_reserved}, transfer-property=PENDING
          signal HD_AVMInfoDisplayHSC4_oP2P_IECU_HSC4_FrP01_oCAN01: start 63, 4 bit, big-endian, init-value=0, base-type=uint8, compu {0..15=RANGE, 0=Cx0_no_Request (no Request), 1=Cx1_Vehicle_speed_is_too_fast (Vehicle speed is too fast), 2=Cx2_reserved, 3=Cx3_reserved, 4=Cx4_reserved, 5=Cx5_reserved, 6=Cx6_reserved, 7=Cx7_reserved, 8=Cx8_reserved, 9=Cx9_reserved, 10=CxA_reserved, 11=CxB_reserved, 12=CxC_reserved, 13=CxD_reserved, 14=CxE_reserved, 15=CxF_reserved}, transfer-property=PENDING
      frame P2P_IECU_HSC4_FrP02_oCAN01: id 0x390, from P2P, frame-length=8, can-addressing-mode=STANDARD
        pdu P2P_IECU_HSC4_FrP02_oCAN01: length=8, transmission-mode-false-timing=cyclic-timing=time-period=0, transmission-mode-true-timing=cyclic-timing=time-period=0, unused-bit-pattern=0
          signal AutoDrvngSysStsHSC4_oP2P_IECU_HSC4_FrP02_oCAN01: start 23, 8 bit, big-endian, init-value=0, base-type=uint8, compu {0..255=RANGE, 0=Cx00_Off, 1=Cx01_APA_Disable_ (APA Disable), 2=Cx02_APA_Standby_ (APA Standby), 3=Cx03_Semi_APA_Active_ (Semi-APA Active), 4=Cx04_Fully_APA_Active_ (Fully-APA Active), 5=Cx05_APA_Failed_ (APA Failed), 6=Cx06_Automated_driving_system_Disable (Automated driving system Disable), 7=Cx07_Automated_driving_system_Standby (Automated driving system Standby), 8=Cx08_Normal, 9=Cx09_P2P_Disable, 10=Cx0A_P2P_Learning, 11=Cx0B_P2P_SearchA, 12=Cx0C_P2P_Prepare, 13=Cx0D_P2P_Auto, 14=Cx0E_P2P_Manual, 15=Cx0F_P2P_Standby, 16=Cx10_reserved_0x10_0xFF_ (reserved (0x10 - 0xFF)); unit reserved} "Source signal range: [16,255]", unit=reserved, transfer-property=PENDING
      frame RDA_HSC4_P02_oCAN01: id 0x204, to P2P, frame-length=8, can-addressing-mode=STANDARD
        pdu RDA_HSC4_P02_oCAN01: length=8, transmission-mode-false-timing=cyclic-timing=time-period=0, transmission-mode-true-timing=cyclic-timing=time-period=0, unused-bit-pattern=0
          signal RRCTAWrnngHSC4_oRDA_HSC4_P02_oCAN01: start 1, 2 bit, big-endian, init-value=0, base-type=uint8, compu {0..3=RANGE, 0=Cx0_no_warning (no warning), 1=Cx1_warning_level_1 (warning level 1), 2=Cx2_warning_level_2 (warning level 2)}, transfer-property=PENDING, to P2P
          signal LRCTAWrnngHSC4_oRDA_HSC4_P02_oCAN01: start 3, 2 bit, big-endian, init-value=0, base-type=uint8, compu {0..3=RANGE, 0=Cx0_no_warning (no warning), 1=Cx1_warning_level_1 (warning level 1), 2=Cx2_warning_level_2 (warning level 2)}, transfer-property=PENDING, to P2P
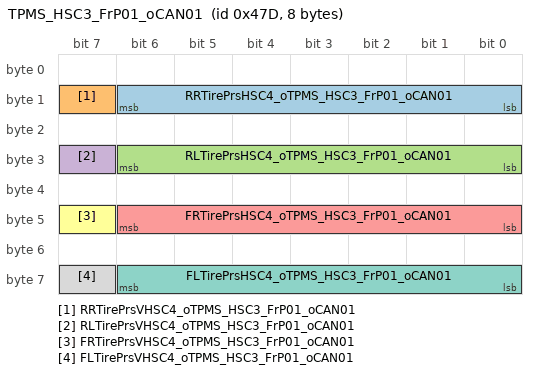
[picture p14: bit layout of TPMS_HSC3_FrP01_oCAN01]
      frame TPMS_HSC3_FrP01_oCAN01: id 0x47D, to P2P, frame-length=8, can-addressing-mode=STANDARD
        pdu TPMS_HSC3_FrP01_oCAN01: length=8, transmission-mode-false-timing=cyclic-timing=time-period=0, transmission-mode-true-timing=cyclic-timing=time-period=0, unused-bit-pattern=0
          signal RRTirePrsHSC4_oTPMS_HSC3_FrP01_oCAN01: start 14, 7 bit, big-endian, init-value=55, base-type=uint8, compu {0=Cx00_kPa_0x0_0x7F_ (kPa (0x0 - 0x7F)), phys=raw*4 for raw 0..127; unit kPa}, unit=kPa, transfer-property=PENDING, to P2P
          signal RRTirePrsVHSC4_oTPMS_HSC3_FrP01_oCAN01: start 15, 1 bit, big-endian, init-value=0, base-type=boolean, compu {0..1=RANGE, 0=Cx0_Valid, 1=Cx1_Invalid}, transfer-property=PENDING, to P2P
          signal RLTirePrsHSC4_oTPMS_HSC3_FrP01_oCAN01: start 30, 7 bit, big-endian, init-value=55, base-type=uint8, compu {0=Cx00_kPa_0x0_0x7F_ (kPa (0x0 - 0x7F)), phys=raw*4 for raw 0..127; unit kPa}, unit=kPa, transfer-property=PENDING, to P2P
          signal RLTirePrsVHSC4_oTPMS_HSC3_FrP01_oCAN01: start 31, 1 bit, big-endian, init-value=0, base-type=boolean, compu {0..1=RANGE, 0=Cx0_Valid, 1=Cx1_Invalid}, transfer-property=PENDING, to P2P
          signal FRTirePrsHSC4_oTPMS_HSC3_FrP01_oCAN01: start 46, 7 bit, big-endian, init-value=55, base-type=uint8, compu {0=Cx00_kPa_0x0_0x7F_ (kPa (0x0 - 0x7F)), phys=raw*4 for raw 0..127; unit kPa}, unit=kPa, transfer-property=PENDING, to P2P
          signal FRTirePrsVHSC4_oTPMS_HSC3_FrP01_oCAN01: start 47, 1 bit, big-endian, init-value=0, base-type=boolean, compu {0..1=RANGE, 0=Cx0_Valid, 1=Cx1_Invalid}, transfer-property=PENDING, to P2P
          signal FLTirePrsHSC4_oTPMS_HSC3_FrP01_oCAN01: start 62, 7 bit, big-endian, init-value=55, base-type=uint8, compu {0=Cx00_kPa_0x0_0x7F_ (kPa (0x0 - 0x7F)), phys=raw*4 for raw 0..127; unit kPa}, unit=kPa, transfer-property=PENDING, to P2P
          signal FLTirePrsVHSC4_oTPMS_HSC3_FrP01_oCAN01: start 63, 1 bit, big-endian, init-value=0, base-type=boolean, compu {0..1=RANGE, 0=Cx0_Valid, 1=Cx1_Invalid}, transfer-property=PENDING, to P2P
      frame TPMS_HSC3_FrP02_oCAN01: id 0x47E, to P2P, frame-length=8, can-addressing-mode=STANDARD
        pdu TPMS_HSC3_FrP02_oCAN01: length=8, transmission-mode-false-timing=cyclic-timing=time-period=0, transmission-mode-true-timing=cyclic-timing=time-period=0, unused-bit-pattern=0
          signal TPMSFHSC4_oTPMS_HSC3_FrP02_oCAN01: start 0, 1 bit, big-endian, init-value=0, base-type=boolean, compu {0..1=RANGE, 0=Cx0_False, 1=Cx1_True}, transfer-property=PENDING, to P2P
  can cluster CAN02: protocol-name=CAN  # 180319-lh1-EP21P2P_P2P_SecCH-V09
    can physical channel CHNL: comm-connectors=CN_CAN02
      frame APA_SecCH_FrP00_oCAN02: id 0x1A8, to P2P, frame-length=6, can-addressing-mode=STANDARD
        pdu APA_SecCH_FrP00_oCAN02: length=6, transmission-mode-false-timing=cyclic-timing=time-period=0, transmission-mode-true-timing=cyclic-timing=time-period=0, unused-bit-pattern=0
          signal APAToqReqVal_sech2_SecCAN2_oAPA_SecCH_FrP00_oCAN02: start 3, 12 bit, big-endian, init-value=0, base-type=uint16, compu {phys=raw*0.5-848 for raw 0..4095; unit Nm}, unit=Nm, transfer-property=PENDING, to P2P
          signal APAToqReqSts_sech2_SecCAN2_oAPA_SecCH_FrP00_oCAN02: start 4, 1 bit, big-endian, init-value=0, base-type=boolean, compu {0..1=RANGE, 0=Cx0_No_Request (No Request), 1=Cx1_Request}, transfer-property=PENDING, to P2P
          signal APAF_sech2_SecCAN2_oAPA_SecCH_FrP00_oCAN02: start 5, 1 bit, big-endian, init-value=0, base-type=boolean, compu {0..1=RANGE, 0=Cx0_Normal, 1=Cx1_APA_failure (APA failure)}, transfer-property=PENDING, to P2P
          signal APACmdEPSSts_sech2_SecCAN2_oAPA_SecCH_FrP00_oCAN02: start 7, 2 bit, big-endian, init-value=0, base-type=uint8, compu {0..3=RANGE, 0=Cx0_No_request (No request), 1=Cx1_Control_EPS_request (Control EPS request), 2=Cx2_EPS_control (EPS control)}, transfer-property=PENDING, to P2P
          signal APATrgtEPSStrgWhlAng_sech2_SecCAN2_oAPA_SecCH_FrP00_oCAN02: start 23, 16 bit, big-endian, init-value=0, base-type=uint16, compu {phys=raw*0.0625-2048 for raw 0..65520}, transfer-property=PENDING, to P2P
          signal APAAlvRC_sech2_SecCAN2_oAPA_SecCH_FrP00_oCAN02: start 39, 8 bit, big-endian, init-value=0, base-type=uint8, compu {0..255=RANGE}, transfer-property=PENDING, to P2P
          signal APAChksm_sech2_SecCAN2_oAPA_SecCH_FrP00_oCAN02: start 47, 8 bit, big-endian, init-value=0, base-type=uint8, compu {0..255=RANGE}, transfer-property=PENDING, to P2P
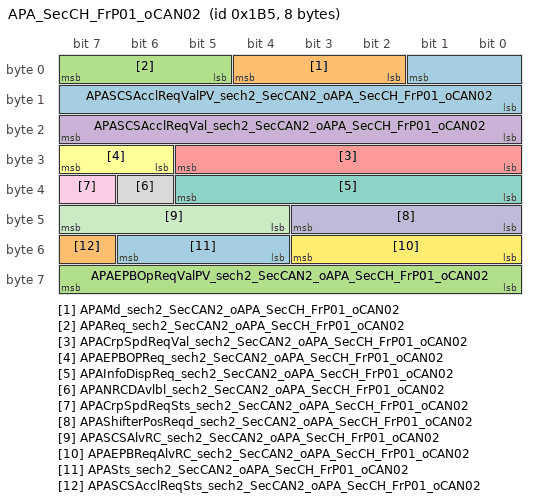
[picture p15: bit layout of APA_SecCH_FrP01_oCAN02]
      frame APA_SecCH_FrP01_oCAN02: id 0x1B5, to P2P, frame-length=8, can-addressing-mode=STANDARD
        pdu APA_SecCH_FrP01_oCAN02: length=8, transmission-mode-false-timing=cyclic-timing=time-period=0, transmission-mode-true-timing=cyclic-timing=time-period=0, unused-bit-pattern=0
          signal APASCSAcclReqValPV_sech2_SecCAN2_oAPA_SecCH_FrP01_oCAN02: start 1, 10 bit, big-endian, init-value=0, base-type=uint16, compu {0..1023=RANGE}, transfer-property=PENDING, to P2P
          signal APAMd_sech2_SecCAN2_oAPA_SecCH_FrP01_oCAN02: start 4, 3 bit, big-endian, init-value=0, base-type=uint8, compu {0..7=RANGE, 0=Cx0_Off, 1=Cx1_Parallel_Parking (Parallel Parking), 2=Cx2_Perpendicular_Parking (Perpendicular Parking), 3=Cx3_Park_Out (Park Out), 4=Cx4_Unknown_Parallel_Parking_or_Perpendicular_Parking (Unknown Parallel Parking or Perpendicular Parking), 5=Cx5_Unknown_Park_in_or_Park_Out (Unknown Park in or Park Out), 6=Cx6_Reserved, 7=Cx7_Reserved}, transfer-property=PENDING, to P2P
          signal APAReq_sech2_SecCAN2_oAPA_SecCH_FrP01_oCAN02: start 7, 3 bit, big-endian, init-value=0, base-type=uint8, compu {0..7=RANGE, 0=Cx0_Disable, 1=Cx1_Standby, 2=Cx2_Semi_APA_Mode_Request (Semi-APA Mode Request), 3=Cx3_Fully_APA_Mode_Request (Fully-APA Mode Request), 4=Cx4_Failed}, transfer-property=PENDING, to P2P
          signal APASCSAcclReqVal_sech2_SecCAN2_oAPA_SecCH_FrP01_oCAN02: start 23, 8 bit, big-endian, init-value=0, base-type=uint8, compu {phys=raw*0.1-12.7 for raw 0..255; unit m/s2}, unit=m/s2, transfer-property=PENDING, to P2P
          signal APACrpSpdReqVal_sech2_SecCAN2_oAPA_SecCH_FrP01_oCAN02: start 29, 6 bit, big-endian, init-value=0, base-type=uint8, compu {phys=raw*0.1 for raw 0..62; unit km/h}, unit=km/h, transfer-property=PENDING, to P2P
          signal APAEPBOPReq_sech2_SecCAN2_oAPA_SecCH_FrP01_oCAN02: start 31, 2 bit, big-endian, init-value=0, base-type=uint8, compu {0..3=RANGE, 0=Cx0_No_Request (No Request), 1=Cx1_Apply, 2=Cx2_Release}, transfer-property=PENDING, to P2P
          signal APAInfoDispReq_sech2_SecCAN2_oAPA_SecCH_FrP01_oCAN02: start 37, 6 bit, big-endian, init-value=0, base-type=uint8, compu {0..63=RANGE, 0=Cx00_Reserved, 1=Cx01_Please_select_parking_mode (Please select parking mode), 2=Cx02_Vehicle_speed_is_too_high_APA_system_abort (Vehicle speed is too high, APA system abort), 3=Cx03_Vehicle_speed_is_too_high_please_be_slow_down (Vehicle speed is too high, please be slow down), 4=Cx04_Parking_slot_searching (Parking slot searching), 5=Cx05_APA_system_quit (APA system quit), 6=Cx06_Please_drive_forward (Please drive forward), 7=Cx07_Please_stop_the_car_ (Please stop the car), 8=Cx08_Please_select_park_in_direction_or_turn_on_direction_indicator (Please select park in direction or turn on direction indicator), 9=Cx09_External_Disturbance_System_stop_work (External Disturbance, System stop work), 10=Cx0A_Reserved, 11=Cx0B_Reserved, 12=Cx0C_Reserved, 13=Cx0D_Reserved, 14=Cx0E_Reserved, 15=Cx0F_Reserved, 16=Cx10_Please_fasten_seat_belt (Please fasten seat belt), 17=Cx11_Door_is_open_Parking_manoeuvre_quit (Door is open: Parking manoeuvre quit), 18=Cx12_System_failed_APA_system_is_useless (System failed, APA system is useless), 19=Cx13_Please_close_the_door (Please close the door), 20=Cx14_Reserved, 21=Cx15_Reserved, 22=Cx16_Reserved, 23=Cx17_Please_step_brake_pedal_if_you_want_to_use_parking_manoeuvre (Please step brake pedal if you want to use parking manoeuvre), 24=Cx18_Reserved, 25=Cx19_Reserved, 26=Cx1A_Reserved, 27=Cx1B_Reserved, 28=Cx1C_Reserved, 29=Cx1D_Reserved, 30=Cx1E_Reserved, 31=Cx1F_Reserved, 32=Cx20_APA_switch_no_press_parking_manoeuvre_quit (APA switch no press, parking manoeuvre quit), 33=Cx21_Danger_zone_has_obstacle_parking_manoeuvre_suspend (Danger zone has obstacle, parking manoeuvre suspend), 34=Cx22_Do_not_touch_steering_wheel_during_parking_process_parking_manoeuvre_quit (Do not touch steering wheel during parking process, parking manoeuvre quit), 35=Cx23_Step_on_the_gas_Parking_manoeuvre_quit (Step on the gas: Parking manoeuvre quit), 36=Cx24_Brake_pedal_has_been_pushed_Parking_manoeuvre_quit (Brake pedal has been pushed: Parking manoeuvre quit), 37=Cx25_Shifter_lever_has_been_controlled_Parking_manoeuvre_quit (Shifter lever has been controlled: Parking manoeuvre quit), 38=Cx26_APA_system_abort_Please_take_over_vehicle (APA system abort, Please take over vehicle), 39=Cx27_Gradient_too_large_APA_system_quit (Gradient too large£¬ APA system quit), 40=Cx28_Reserved, 41=Cx29_Reserved, 42=Cx2A_Please_keep_away_steering_wheel_and_press_APA_switch_if_you_want_to_parking_in (Please keep away steering wheel and press APA switch if you want to parking in), 43=Cx2B_Parking_is_ready (Parking is ready), 44=Cx2C_Please_release_brake_and_pay_attention_to_surroundings_using_active_control_measure_if_necessary_ (Please release brake and pay attention to surroundings, using active control measure if necessary), 45=Cx2D_Parking_is_ongoing (Parking is ongoing), 46=Cx2E_Parking_manoeuvre_has_completed_Please_take_over_vehicle (Parking manoeuvre has completed: Please take over vehicle), 47=Cx2F_Please_keep_away_steering_wheel_and_re_press_APA_switch_if_you_want_to_parking_in_continually (Please keep away steering wheel and re-press APA switch if you want to parking in continually), 48=Cx30_System_timeout_APA_system_quit (System timeout, APA system quit), 49=Cx31_Please_select_park_out_direction_or_turn_on_direction_indicator (Please select park out direction or turn on direction indicator), 50=Cx32_Please_keep_away_steering_wheel_and_press_APA_switch_if_you_want_to_park_out (Please keep away steering wheel and press APA switch if you want to park out), 51=Cx33_Please_keep_away_steering_wheel_and_re_press_APA_switch_if_you_want_to_park_out_continually (Please keep away steering wheel and re-press APA switch if you want to park out continually), 52=Cx34_Reserved, 53=Cx35_Reserved, 54=Cx36_Reserved, 55=Cx37_Please_select_reverse_gear_and_keep_away_steering_wheel (Please select reverse gear and keep away steering wheel), 56=Cx38_Be_careful_drive_backward_and_prepare_for_stop (Be careful drive backward and prepare for stop), 57=Cx39_Please_select_drive_gear_and_move_forward (Please select drive gear and move forward), 58=Cx3A_Be_careful_drive_forward_and_prepare_for_stop (Be careful drive forward and prepare for stop), 59=Cx3B_Please_select_reverse_gear_and_move_backward (Please select reverse gear and move backward), 60=Cx3C_Vehicle_is_going_to_move_forward (Vehicle is going to move forward), 61=Cx3D_Vehicle_is_going_to_move_backward (Vehicle is going to move backward), 62=Cx3E_Reserved, 63=Cx3F_Reserved}, transfer-property=PENDING, to P2P
          signal APANRCDAvlbl_sech2_SecCAN2_oAPA_SecCH_FrP01_oCAN02: start 38, 1 bit, big-endian, init-value=0, base-type=boolean, compu {0..1=RANGE, 0=Cx0_Not_available (Not available), 1=Cx1_Available}, transfer-property=PENDING, to P2P  # Advanced Park Assist Near Range Control Drive Available
          signal APACrpSpdReqSts_sech2_SecCAN2_oAPA_SecCH_FrP01_oCAN02: start 39, 1 bit, big-endian, init-value=0, base-type=boolean, compu {0..1=RANGE, 0=Cx0_No_Request (No Request), 1=Cx1_Request}, transfer-property=PENDING, to P2P
          signal APAShifterPosReqd_sech2_SecCAN2_oAPA_SecCH_FrP01_oCAN02: start 43, 4 bit, big-endian, init-value=0, base-type=uint8, compu {0..15=RANGE, 0=Cx0_Initial, 1=Cx1_S_Sport_mode_ (S(Sport mode)), 2=Cx2_W_Winter_mode_ (W(Winter mode)), 3=Cx3_M_Manual_mode_ (M(Manual mode)), 5=Cx5_D_Drive_ (D(Drive)), 6=Cx6_N_Neutral_ (N(Neutral)), 7=Cx7_R_Reverse_ (R(Reverse)), 8=Cx8_P_Park_ (P(Park)), 9=Cx9_Reserve, 10=CxA_Error}, transfer-property=PENDING, to P2P
          signal APASCSAlvRC_sech2_SecCAN2_oAPA_SecCH_FrP01_oCAN02: start 47, 4 bit, big-endian, init-value=0, base-type=uint8, compu {0..15=RANGE}, transfer-property=PENDING, to P2P
          signal APAEPBReqAlvRC_sech2_SecCAN2_oAPA_SecCH_FrP01_oCAN02: start 51, 4 bit, big-endian, init-value=0, base-type=uint8, compu {0..15=RANGE}, transfer-property=PENDING, to P2P
          signal APASts_sech2_SecCAN2_oAPA_SecCH_FrP01_oCAN02: start 54, 3 bit, big-endian, init-value=0, base-type=uint8, compu {0..7=RANGE, 0=Cx0_Disable, 1=Cx1_Standby, 2=Cx2_Semi_APA_Active (Semi-APA Active), 3=Cx3_Fully_APA_Active (Fully-APA Active), 4=Cx4_Failed}, transfer-property=PENDING, to P2P
          signal APASCSAcclReqSts_sech2_SecCAN2_oAPA_SecCH_FrP01_oCAN02: start 55, 1 bit, big-endian, init-value=0, base-type=boolean, compu {0..1=RANGE, 0=Cx0_no_request (no request), 1=Cx1_Deceleration_request (Deceleration request)}, transfer-property=PENDING, to P2P
          signal APAEPBOpReqValPV_sech2_SecCAN2_oAPA_SecCH_FrP01_oCAN02: start 63, 8 bit, big-endian, init-value=0, base-type=uint8, compu {0..255=RANGE}, transfer-property=PENDING, to P2P
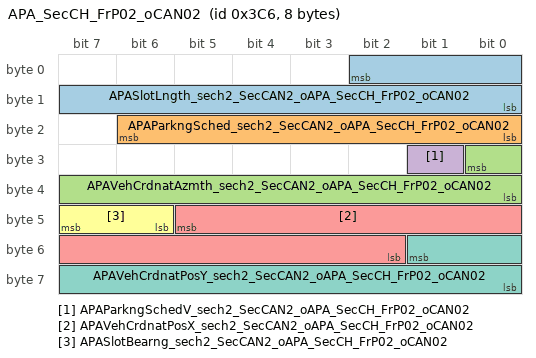
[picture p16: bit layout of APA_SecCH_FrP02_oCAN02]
      frame APA_SecCH_FrP02_oCAN02: id 0x3C6, to P2P, frame-length=8, can-addressing-mode=STANDARD
        pdu APA_SecCH_FrP02_oCAN02: length=8, transmission-mode-false-timing=cyclic-timing=time-period=0, transmission-mode-true-timing=cyclic-timing=time-period=0, unused-bit-pattern=0
          signal APASlotLngth_sech2_SecCAN2_oAPA_SecCH_FrP02_oCAN02: start 2, 11 bit, big-endian, init-value=0, base-type=uint16, compu {0..2047=RANGE; unit cm}, unit=cm, transfer-property=PENDING, to P2P  # Advanced Park Assist Slot Length
          signal APAParkngSched_sech2_SecCAN2_oAPA_SecCH_FrP02_oCAN02: start 22, 7 bit, big-endian, init-value=0, base-type=uint8, compu {phys=raw*0.01 for raw 0..100}, transfer-property=PENDING, to P2P  # Advanced Park Assist Parking Schedule
          signal APAVehCrdnatAzmth_sech2_SecCAN2_oAPA_SecCH_FrP02_oCAN02: start 24, 9 bit, big-endian, init-value=0, base-type=uint16, compu {0..511=RANGE}, transfer-property=PENDING, to P2P  # Advanced Park Assist Vehicle Coordinate Azimuth
          signal APAParkngSchedV_sech2_SecCAN2_oAPA_SecCH_FrP02_oCAN02: start 25, 1 bit, big-endian, init-value=0, base-type=boolean, compu {0..1=RANGE, 0=Cx0_Valid, 1=Cx1_Invalid}, transfer-property=PENDING, to P2P  # Advanced Park Assist Parking Schedule Validit
          signal APAVehCrdnatPosX_sech2_SecCAN2_oAPA_SecCH_FrP02_oCAN02: start 45, 12 bit, big-endian, init-value=0, base-type=uint16, compu {phys=raw-2048 for raw 0..4095; unit cm}, unit=cm, transfer-property=PENDING, to P2P  # Advanced Park Assist Vehicle Coordinate Position X
          signal APASlotBearng_sech2_SecCAN2_oAPA_SecCH_FrP02_oCAN02: start 47, 2 bit, big-endian, init-value=0, base-type=uint8, compu {0..3=RANGE, 0=Cx0_No_slot (No slot), 1=Cx1_Left_slot (Left slot), 2=Cx2_Right_slot (Right slot), 3=Cx3_Both_left_and_right_slot (Both left and right slot)}, transfer-property=PENDING, to P2P  # Advanced Park Assist Slot Bearing
          signal APAVehCrdnatPosY_sech2_SecCAN2_oAPA_SecCH_FrP02_oCAN02: start 49, 10 bit, big-endian, init-value=0, base-type=uint16, compu {phys=raw-512 for raw 0..1023; unit cm}, unit=cm, transfer-property=PENDING, to P2P  # Advanced Park Assist Vehicle Coordinate Position Y
      frame APA_SecCH_FrP03_oCAN02: id 0x28B, to P2P, frame-length=8, can-addressing-mode=STANDARD
        pdu APA_SecCH_FrP03_oCAN02: length=8, transmission-mode-false-timing=cyclic-timing=time-period=0, transmission-mode-true-timing=cyclic-timing=time-period=0, unused-bit-pattern=0
          signal RRObsDist_sech2_SecCAN2_oAPA_SecCH_FrP03_oCAN02: start 7, 9 bit, big-endian, init-value=0, base-type=uint16, compu {0..511=RANGE}, transfer-property=PENDING, to P2P
          signal RLObsDist_sech2_SecCAN2_oAPA_SecCH_FrP03_oCAN02: start 14, 9 bit, big-endian, init-value=0, base-type=uint16, compu {0..511=RANGE}, transfer-property=PENDING, to P2P
          signal FRObsDist_sech2_SecCAN2_oAPA_SecCH_FrP03_oCAN02: start 21, 9 bit, big-endian, init-value=0, base-type=uint16, compu {0..511=RANGE}, transfer-property=PENDING, to P2P
          signal FLObsDist_sech2_SecCAN2_oAPA_SecCH_FrP03_oCAN02: start 24, 9 bit, big-endian, init-value=0, base-type=uint16, compu {0..511=RANGE}, transfer-property=PENDING, to P2P
      frame APA_SecCH_FrP04_oCAN02: id 0x28C, to P2P, frame-length=8, can-addressing-mode=STANDARD
        pdu APA_SecCH_FrP04_oCAN02: length=8, transmission-mode-false-timing=cyclic-timing=time-period=0, transmission-mode-true-timing=cyclic-timing=time-period=0, unused-bit-pattern=0
          signal RrMidRObsDist_sech2_SecCAN2_oAPA_SecCH_FrP04_oCAN02: start 7, 9 bit, big-endian, init-value=0, base-type=uint16, compu {0..511=RANGE}, transfer-property=PENDING, to P2P
          signal RrMidLObsDist_sech2_SecCAN2_oAPA_SecCH_FrP04_oCAN02: start 14, 9 bit, big-endian, init-value=0, base-type=uint16, compu {0..511=RANGE}, transfer-property=PENDING, to P2P
          signal FrtMidRObsDist_sech2_SecCAN2_oAPA_SecCH_FrP04_oCAN02: start 21, 9 bit, big-endian, init-value=0, base-type=uint16, compu {0..511=RANGE}, transfer-property=PENDING, to P2P
          signal FrtMidLObsDist_sech2_SecCAN2_oAPA_SecCH_FrP04_oCAN02: start 24, 9 bit, big-endian, init-value=0, base-type=uint16, compu {0..511=RANGE}, transfer-property=PENDING, to P2P
      frame DIAG_DTCInfo_APA_oCAN02: id 0x799, to P2P, frame-length=7, can-addressing-mode=STANDARD
        pdu DIAG_DTCInfo_APA_oCAN02: length=7, unused-bit-pattern=0
          signal DTCInfomationAPA_SecCAN2_oDIAG_DTCInfo_APA_oCAN02: start 0, 56 bit, opaque, init-value=7 x 0, base-type=uint8_7_iso_8859_1, compu {0..72057594037927935=RANGE}, transfer-property=PENDING, to P2P  # DTC Infomation of APA The length of DTC information signal is 7 bytes. Byte 0 is MSB (most significant byte), and Byte 6 is LSB (least significant byte). For each byte, Bit 7 is msb (most significant bit), and Bit 0 is lsb (least significant bit). Byte 0: Bit (7-4): DTC Serious Level Bit (3-0): Reserved Byte 1: Bit (7-0): Reserved Byte 2: Bit (7-0): DTCHighByte Byte 3: Bit (7-0): DTCLowByte Byte 4: Bit (7-0): DTCFailureTypeByte Byte 5: Bit 7: warningIndicatorRequested Bit 6: testNotCompletedThisOperationCycle Bit 5: testFailedSinceLastClear Bit 4: testNotCompletedSinceLastClear Bit 3: confirmedDTC Bit 2: pendingDTC Bit 1: testFailedThisOperationCycle Bit 0: testFailed Byte 6: Bit (7-0): DTC Type For more detail, please refer to SMTC 2 800 004.
      frame P2P_SecCH_BCM_FrP03_oCAN02: id 0x47A, from P2P, frame-length=8, can-addressing-mode=STANDARD
        pdu P2P_SecCH_BCM_FrP03_oCAN02: length=8, transmission-mode-false-timing=cyclic-timing=time-period=0, transmission-mode-true-timing=cyclic-timing=time-period=0, unused-bit-pattern=0
          signal TrlrHitchSwA_SecCAN2_oP2P_SecCH_BCM_FrP03_oCAN02: start 15, 1 bit, big-endian, init-value=0, base-type=boolean, compu {0..1=RANGE, 0=Cx0_False, 1=Cx1_True}, transfer-property=PENDING
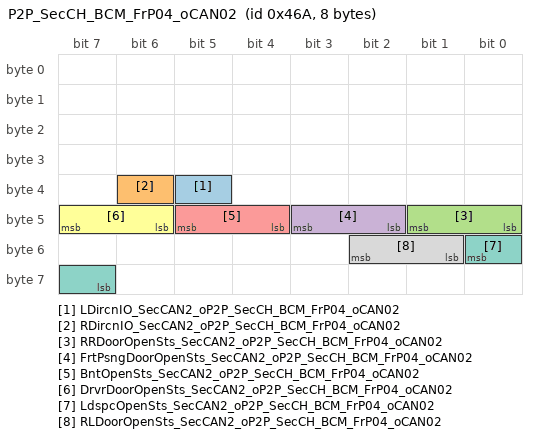
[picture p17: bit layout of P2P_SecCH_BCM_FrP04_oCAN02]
      frame P2P_SecCH_BCM_FrP04_oCAN02: id 0x46A, from P2P, frame-length=8, can-addressing-mode=STANDARD
        pdu P2P_SecCH_BCM_FrP04_oCAN02: length=8, transmission-mode-false-timing=cyclic-timing=time-period=0, transmission-mode-true-timing=cyclic-timing=time-period=0, unused-bit-pattern=0
          signal LDircnIO_SecCAN2_oP2P_SecCH_BCM_FrP04_oCAN02: start 37, 1 bit, big-endian, init-value=0, base-type=boolean, compu {0..1=RANGE, 0=Cx0_False, 1=Cx1_True}, transfer-property=PENDING
          signal RDircnIO_SecCAN2_oP2P_SecCH_BCM_FrP04_oCAN02: start 38, 1 bit, big-endian, init-value=0, base-type=boolean, compu {0..1=RANGE, 0=Cx0_False, 1=Cx1_True}, transfer-property=PENDING
          signal RRDoorOpenSts_SecCAN2_oP2P_SecCH_BCM_FrP04_oCAN02: start 41, 2 bit, big-endian, init-value=0, base-type=uint8, compu {0..3=RANGE, 0=Cx0_Rear_Right_Door_Closed (Rear Right Door Closed), 1=Cx1_Rear_Right_Door_Open_latch_switch_cann_t_detect_door_ajar_status (Rear Right Door Open(latch switch cann't detect door ajar status), 2=Cx2_Rear_Right_Door_Ajar (Rear Right Door Ajar), 3=Cx3_Rear_Right_Door_Full_Open (Rear Right Door Full Open)}, transfer-property=PENDING  # Rear Right Door Open Status
          signal FrtPsngDoorOpenSts_SecCAN2_oP2P_SecCH_BCM_FrP04_oCAN02: start 43, 2 bit, big-endian, init-value=0, base-type=uint8, compu {0..3=RANGE, 0=Cx0_Front_Passenger_Door_Closed (Front Passenger Door Closed), 1=Cx1_Front_Passenger_Open_latch_switch_cann_t_detect_door_ajar_statu (Front Passenger Open(latch switch cann¡®t detect door ajar statu), 2=Cx2_Front_Passenger_Door_Ajar (Front Passenger Door Ajar), 3=Cx3_Front_Passenger_Door_Full_Open (Front Passenger Door Full Open)}, transfer-property=PENDING
          signal BntOpenSts_SecCAN2_oP2P_SecCH_BCM_FrP04_oCAN02: start 45, 2 bit, big-endian, init-value=0, base-type=uint8, compu {0..3=RANGE, 0=Cx0_Bonnet_Closed (Bonnet Closed), 1=Cx1_Bonnet_Open (Bonnet Open), 2=Cx2_Bonnet_Switch_Disconnect (Bonnet Switch Disconnect), 3=Cx3_Reserved}, transfer-property=PENDING
          signal DrvrDoorOpenSts_SecCAN2_oP2P_SecCH_BCM_FrP04_oCAN02: start 47, 2 bit, big-endian, init-value=0, base-type=uint8, compu {0..3=RANGE, 0=Cx0_Driver_Door_Closed (Driver Door Closed), 1=Cx1_Driver_Door_Open_For_latch_switch_can_t_detect_door_ajar_status_ (Driver Door Open(For latch switch can't detect door ajar status)), 2=Cx2_Driver_Door_Ajar (Driver Door Ajar), 3=Cx3_Driver_Door_Full_Open (Driver Door Full Open)}, transfer-property=PENDING
          signal LdspcOpenSts_SecCAN2_oP2P_SecCH_BCM_FrP04_oCAN02: start 48, 2 bit, big-endian, init-value=0, base-type=uint8, compu {0..3=RANGE, 0=Cx0_Load_Space_Closed (Load Space Closed), 1=Cx1_Load_Space_Open (Load Space Open), 2=Cx2_Reserved, 3=Cx3_Reserved}, transfer-property=PENDING
          signal RLDoorOpenSts_SecCAN2_oP2P_SecCH_BCM_FrP04_oCAN02: start 50, 2 bit, big-endian, init-value=0, base-type=uint8, compu {0..3=RANGE, 0=Cx0_Rear_Left_Door_Closed (Rear Left Door Closed), 1=Cx1_Rear_Left_Door_Open_latch_switch_cann_t_detect_door_ajar_status (Rear Left Door Open(latch switch cann't detect door ajar status), 2=Cx2_Rear_Left_Door_Ajar (Rear Left Door Ajar), 3=Cx3_Rear_Left_Door_Full_Open (Rear Left Door Full Open)}, transfer-property=PENDING
      frame P2P_SecCH_BCM_FrP07_oCAN02: id 0x1F2, from P2P, frame-length=2, can-addressing-mode=STANDARD
        pdu P2P_SecCH_BCM_FrP07_oCAN02: length=2, transmission-mode-false-timing=cyclic-timing=time-period=0, transmission-mode-true-timing=cyclic-timing=time-period=0, unused-bit-pattern=0
          signal SysBPM_SecCAN2_oP2P_SecCH_BCM_FrP07_oCAN02: start 5, 2 bit, big-endian, init-value=0, base-type=uint8, compu {0..3=RANGE, 0=Cx0_Off, 1=Cx1_ACC, 2=Cx2_Run, 3=Cx3_Crank_Request (Crank Request)}, transfer-property=PENDING
          signal SysBPMEnbd_SecCAN2_oP2P_SecCH_BCM_FrP07_oCAN02: start 6, 1 bit, big-endian, init-value=0, base-type=boolean, compu {0..1=RANGE, 0=Cx0_False, 1=Cx1_True}, transfer-property=PENDING
      frame P2P_SecCH_ECM_FrP00_oCAN02: id 0xC9, from P2P, frame-length=8, can-addressing-mode=STANDARD
        pdu P2P_SecCH_ECM_FrP00_oCAN02: length=8, transmission-mode-false-timing=cyclic-timing=time-period=0, transmission-mode-true-timing=cyclic-timing=time-period=0, unused-bit-pattern=0
          signal EnRunA_SecCAN2_oP2P_SecCH_ECM_FrP00_oCAN02: start 7, 1 bit, big-endian, init-value=0, base-type=boolean, compu {0..1=RANGE, 0=Cx0_False, 1=Cx1_True}, transfer-property=PENDING
      frame P2P_SecCH_EPB_FrP00_oCAN02: id 0x230, from P2P, frame-length=8, can-addressing-mode=STANDARD
        pdu P2P_SecCH_EPB_FrP00_oCAN02: length=8, transmission-mode-false-timing=cyclic-timing=time-period=0, transmission-mode-true-timing=cyclic-timing=time-period=0, unused-bit-pattern=0
          signal EPBSwStsV_SecCAN2_oP2P_SecCH_EPB_FrP00_oCAN02: start 5, 1 bit, big-endian, init-value=0, base-type=boolean, compu {0..1=RANGE, 0=Cx0_Valid, 1=Cx1_Invalid}, transfer-property=PENDING
          signal EPBSwSts_SecCAN2_oP2P_SecCH_EPB_FrP00_oCAN02: start 7, 2 bit, big-endian, init-value=0, base-type=uint8, compu {0..3=RANGE, 0=Cx0_NotActive, 1=Cx1_Release, 2=Cx2_Apply}, transfer-property=PENDING
      frame P2P_SecCH_EPB_FrP01_oCAN02: id 0x22A, from P2P, frame-length=2, can-addressing-mode=STANDARD
        pdu P2P_SecCH_EPB_FrP01_oCAN02: length=2, transmission-mode-false-timing=cyclic-timing=time-period=0, transmission-mode-true-timing=cyclic-timing=time-period=0, unused-bit-pattern=0
          signal EPBAvlblyStsPV_SecCAN2_oP2P_SecCH_EPB_FrP01_oCAN02: start 2, 3 bit, big-endian, init-value=0, base-type=uint8, compu {0..7=RANGE}, transfer-property=PENDING
          signal EPBAvlblySts_SecCAN2_oP2P_SecCH_EPB_FrP01_oCAN02: start 5, 3 bit, big-endian, init-value=0, base-type=uint8, compu {0..7=RANGE, 0=Cx0_Unavailable_Not_Failed (Unavailable,Not Failed), 1=Cx1_Available_Not_Failed (Available,Not Failed), 2=Cx2_Unavailable_Failed_Applied (Unavailable,Failed Applied), 3=Cx3_Unavailable_Failed_Released (Unavailable,Failed Released), 4=Cx4_Unavailable_Failed_other (Unavailable,Failed other)}, transfer-property=PENDING
          signal EPBAppcnSts_SecCAN2_oP2P_SecCH_EPB_FrP01_oCAN02: start 15, 2 bit, big-endian, init-value=0, base-type=uint8, compu {0..3=RANGE, 0=Cx0_Unknown, 1=Cx1_Park_Brake_Applied (Park Brake Applied), 2=Cx2_Park_Brake_Released (Park Brake Released), 3=Cx3_Park_Brake_Application_in_Progress (Park Brake Application in Progress)}, transfer-property=PENDING  # Electric Park Brake Application Status
      frame P2P_SecCH_EPS_FrP02_oCAN02: id 0x1B1, from P2P, frame-length=4, can-addressing-mode=STANDARD
        pdu P2P_SecCH_EPS_FrP02_oCAN02: length=4, transmission-mode-false-timing=cyclic-timing=time-period=0, transmission-mode-true-timing=cyclic-timing=time-period=0, unused-bit-pattern=0
          signal EPSAPASts_SecCAN2_oP2P_SecCH_EPS_FrP02_oCAN02: start 4, 4 bit, big-endian, init-value=7, base-type=uint8, compu {0..15=RANGE, 0=Cx0_Inhibit, 1=Cx1_Available, 2=Cx2_Active, 3=Cx3_Abort, 4=Cx4_Reply_for_Control (Reply for Control), 5=Cx5_NRCD_Active (NRCD Active), 6=Cx6_ADAS_Active (ADAS Active), 7=Cx7_Failure; unit Reserve} "Source signal range: [8,15]", unit=Reserve, transfer-property=PENDING
          signal EPSAPAInh_SecCAN2_oP2P_SecCH_EPS_FrP02_oCAN02: start 15, 8 bit, big-endian, init-value=0, base-type=uint8, compu {0..255=RANGE, 0=Cx00_Normal_Operation (Normal Operation), 1=Cx01_Over_Speed (Over Speed), 2=Cx02_Driver_Interference (Driver Interference), 4=Cx04_Abnormal_CAN_input (Abnormal CAN input), 8=Cx08_Excess_Angle_Deviation (Excess Angle Deviation), 16=Cx10_EPS_failure (EPS failure), 32=Cx20_Reserve, 64=Cx40_Reserve, 128=Cx80_Reserve}, transfer-property=PENDING
          signal EPSAPAAlvRC_SecCAN2_oP2P_SecCH_EPS_FrP02_oCAN02: start 23, 8 bit, big-endian, init-value=0, base-type=uint8, compu {0..255=RANGE}, transfer-property=PENDING
          signal EPSAPAChksm_SecCAN2_oP2P_SecCH_EPS_FrP02_oCAN02: start 31, 8 bit, big-endian, init-value=0, base-type=uint8, compu {0..255=RANGE}, transfer-property=PENDING
      frame P2P_SecCH_FICM_FrP02_oCAN02: id 0x376, from P2P, frame-length=8, can-addressing-mode=STANDARD
        pdu P2P_SecCH_FICM_FrP02_oCAN02: length=8, transmission-mode-false-timing=cyclic-timing=time-period=0, transmission-mode-true-timing=cyclic-timing=time-period=0, unused-bit-pattern=0
          signal RstrFctryDeftsReq_SecCAN2_oP2P_SecCH_FICM_FrP02_oCAN02: start 56, 1 bit, big-endian, init-value=0, base-type=boolean, compu {0..1=RANGE, 0=Cx0_False, 1=Cx1_True}, transfer-property=PENDING
      frame P2P_SecCH_FICM_FrP08_oCAN02: id 0x2F6, from P2P, frame-length=8, can-addressing-mode=STANDARD
        pdu P2P_SecCH_FICM_FrP08_oCAN02: length=8, transmission-mode-false-timing=cyclic-timing=time-period=0, transmission-mode-true-timing=cyclic-timing=time-period=0, unused-bit-pattern=0
          signal APASwReq_SecCAN2_oP2P_SecCH_FICM_FrP08_oCAN02: start 59, 2 bit, big-endian, init-value=0, base-type=uint8, compu {0..3=RANGE, 0=Cx0_No_request (No request), 1=Cx1_Short_press (Short press), 2=Cx2_Long_press (Long press), 3=Cx3_Reserved}, transfer-property=PENDING
          signal PDCSwReq_SecCAN2_oP2P_SecCH_FICM_FrP08_oCAN02: start 61, 2 bit, big-endian, init-value=0, base-type=uint8, compu {0..3=RANGE, 0=Cx0_No_request (No request), 1=Cx1_Short_press (Short press), 2=Cx2_Long_press (Long press), 3=Cx3_Reserved}, transfer-property=PENDING
      frame P2P_SecCH_FICM_FrP18_oCAN02: id 0x37D, from P2P, frame-length=8, can-addressing-mode=STANDARD
        pdu P2P_SecCH_FICM_FrP18_oCAN02: length=8, transmission-mode-false-timing=cyclic-timing=time-period=0, transmission-mode-true-timing=cyclic-timing=time-period=0, unused-bit-pattern=0
          signal DrvrSelAPAParkngMd_SecCAN2_oP2P_SecCH_FICM_FrP18_oCAN02: start 0, 3 bit, big-endian, init-value=0, base-type=uint8, compu {0..7=RANGE, 0=Cx0_No_select (No select), 1=Cx1_Select_parallel_parking (Select parallel parking), 2=Cx2_Select_perpendicular_parking (Select perpendicular parking), 3=Cx3_Select_park_in (Select park in), 4=Cx4_Select_park_out (Select park out), 5=Cx5_Reserved, 6=Cx6_Reserved, 7=Cx7_Reserved}, transfer-property=PENDING  # Driver Select Advanced Park Assist Parking Mode
          signal DrvrSelAPASlotBearng_SecCAN2_oP2P_SecCH_FICM_FrP18_oCAN02: start 6, 2 bit, big-endian, init-value=0, base-type=uint8, compu {0..3=RANGE, 0=Cx0_No_select (No select), 1=Cx1_Select_Left_slot (Select Left slot), 2=Cx2_Select_Right_slot (Select Right slot), 3=Cx3_Reserved}, transfer-property=PENDING
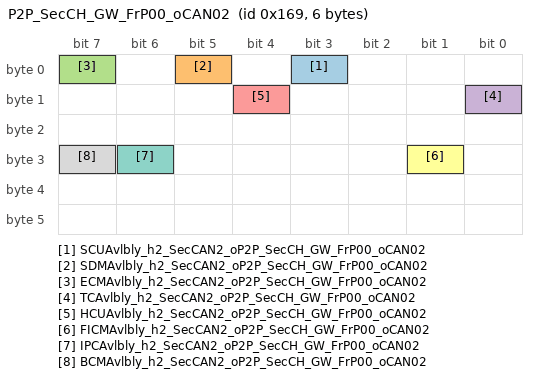
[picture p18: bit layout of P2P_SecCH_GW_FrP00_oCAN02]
      frame P2P_SecCH_GW_FrP00_oCAN02: id 0x169, from P2P, frame-length=6, can-addressing-mode=STANDARD
        pdu P2P_SecCH_GW_FrP00_oCAN02: length=6, transmission-mode-false-timing=cyclic-timing=time-period=0, transmission-mode-true-timing=cyclic-timing=time-period=0, unused-bit-pattern=0
          signal SCUAvlbly_h2_SecCAN2_oP2P_SecCH_GW_FrP00_oCAN02: start 3, 1 bit, big-endian, init-value=0, base-type=boolean, compu {0..1=RANGE, 0=Cx0_False, 1=Cx1_True}, transfer-property=PENDING
          signal SDMAvlbly_h2_SecCAN2_oP2P_SecCH_GW_FrP00_oCAN02: start 5, 1 bit, big-endian, init-value=0, base-type=boolean, compu {0..1=RANGE, 0=Cx0_False, 1=Cx1_True}, transfer-property=PENDING
          signal ECMAvlbly_h2_SecCAN2_oP2P_SecCH_GW_FrP00_oCAN02: start 7, 1 bit, big-endian, init-value=0, base-type=boolean, compu {0..1=RANGE, 0=Cx0_False, 1=Cx1_True}, transfer-property=PENDING
          signal TCAvlbly_h2_SecCAN2_oP2P_SecCH_GW_FrP00_oCAN02: start 8, 1 bit, big-endian, init-value=0, base-type=boolean, compu {0..1=RANGE, 0=Cx0_False, 1=Cx1_True}, transfer-property=PENDING  # TC Available Detect if specific ECU is available according to node missing strategy by gateway ECU.
          signal HCUAvlbly_h2_SecCAN2_oP2P_SecCH_GW_FrP00_oCAN02: start 12, 1 bit, big-endian, init-value=0, base-type=boolean, compu {0..1=RANGE, 0=Cx0_False, 1=Cx1_True}, transfer-property=PENDING  # HCU Available Detect if specific ECU is available according to node missing strategy by gateway ECU.
          signal FICMAvlbly_h2_SecCAN2_oP2P_SecCH_GW_FrP00_oCAN02: start 25, 1 bit, big-endian, init-value=0, base-type=boolean, compu {0..1=RANGE, 0=Cx0_False, 1=Cx1_True}, transfer-property=PENDING
          signal IPCAvlbly_h2_SecCAN2_oP2P_SecCH_GW_FrP00_oCAN02: start 30, 1 bit, big-endian, init-value=0, base-type=boolean, compu {0..1=RANGE, 0=Cx0_False, 1=Cx1_True}, transfer-property=PENDING
          signal BCMAvlbly_h2_SecCAN2_oP2P_SecCH_GW_FrP00_oCAN02: start 31, 1 bit, big-endian, init-value=0, base-type=boolean, compu {0..1=RANGE, 0=Cx0_False, 1=Cx1_True}, transfer-property=PENDING
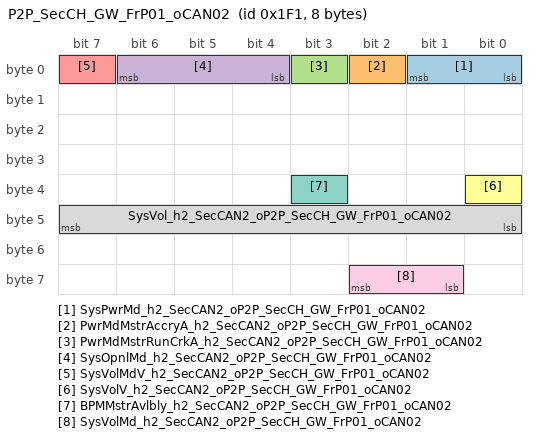
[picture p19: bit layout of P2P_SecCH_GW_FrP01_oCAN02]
      frame P2P_SecCH_GW_FrP01_oCAN02: id 0x1F1, from P2P, frame-length=8, can-addressing-mode=STANDARD
        pdu P2P_SecCH_GW_FrP01_oCAN02: length=8, transmission-mode-false-timing=cyclic-timing=time-period=0, transmission-mode-true-timing=cyclic-timing=time-period=0, unused-bit-pattern=0
          signal SysPwrMd_h2_SecCAN2_oP2P_SecCH_GW_FrP01_oCAN02: start 1, 2 bit, big-endian, init-value=0, base-type=uint8, compu {0..3=RANGE, 0=Cx0_Off, 1=Cx1_Accessory, 2=Cx2_Run, 3=Cx3_Crank_Request (Crank Request)}, transfer-property=PENDING
          signal PwrMdMstrAccryA_h2_SecCAN2_oP2P_SecCH_GW_FrP01_oCAN02: start 2, 1 bit, big-endian, init-value=0, base-type=boolean, compu {0..1=RANGE, 0=Cx0_Inactive, 1=Cx1_Active}, transfer-property=PENDING
          signal PwrMdMstrRunCrkA_h2_SecCAN2_oP2P_SecCH_GW_FrP01_oCAN02: start 3, 1 bit, big-endian, init-value=0, base-type=boolean, compu {0..1=RANGE, 0=Cx0_Inactive, 1=Cx1_Active}, transfer-property=PENDING
          signal SysOpnlMd_h2_SecCAN2_oP2P_SecCH_GW_FrP01_oCAN02: start 6, 3 bit, big-endian, init-value=0, base-type=uint8, compu {0..7=RANGE, 0=Cx0_Normal_Mode (Normal Mode), 1=Cx1_Manufacturing_Mode (Manufacturing Mode), 2=Cx2_Transit_Mode (Transit Mode), 3=Cx3_Show_Room_Reserve_ (Show Room(Reserve)), 4=Cx4_Storage_Mode (Storage Mode), 5=Cx5_Diagnosic_or_Reprogramming_Reserve_ (Diagnosic or Reprogramming(Reserve))}, transfer-property=PENDING
          signal SysVolMdV_h2_SecCAN2_oP2P_SecCH_GW_FrP01_oCAN02: start 7, 1 bit, big-endian, init-value=0, base-type=boolean, compu {0..1=RANGE, 0=Cx0_Valid, 1=Cx1_Invalid}, transfer-property=PENDING
          signal SysVolV_h2_SecCAN2_oP2P_SecCH_GW_FrP01_oCAN02: start 32, 1 bit, big-endian, init-value=0, base-type=boolean, compu {0..1=RANGE, 0=Cx0_Valid, 1=Cx1_Invalid}, transfer-property=PENDING
          signal BPMMstrAvlbly_h2_SecCAN2_oP2P_SecCH_GW_FrP01_oCAN02: start 35, 1 bit, big-endian, init-value=0, base-type=boolean, compu {0..1=RANGE, 0=Cx0_False, 1=Cx1_True}, transfer-property=PENDING
          signal SysVol_h2_SecCAN2_oP2P_SecCH_GW_FrP01_oCAN02: start 47, 8 bit, big-endian, init-value=0, base-type=uint8, compu {phys=raw*0.1+3 for raw 0..255; unit V}, unit=V, transfer-property=PENDING
          signal SysVolMd_h2_SecCAN2_oP2P_SecCH_GW_FrP01_oCAN02: start 58, 2 bit, big-endian, init-value=0, base-type=uint8, compu {0..3=RANGE, 0=Cx0_Normal, 1=Cx1_Low_System_Voltage (Low System Voltage), 2=Cx2_High_System_Voltage (High System Voltage), 3=Cx3_Illegal_System_Voltage (Illegal System Voltage)}, transfer-property=PENDING
      frame P2P_SecCH_GW_FrP08_oCAN02: id 0x540, from P2P, frame-length=8, can-addressing-mode=STANDARD
        pdu P2P_SecCH_GW_FrP08_oCAN02: length=8, transmission-mode-false-timing=cyclic-timing=time-period=0, transmission-mode-true-timing=cyclic-timing=time-period=0, unused-bit-pattern=0
          signal VehOdo_h2_SecCAN2_oP2P_SecCH_GW_FrP08_oCAN02: start 7, 24 bit, big-endian, init-value=0, base-type=uint32, compu {0..16777200=RANGE}, transfer-property=PENDING
          signal VehOdoV_h2_SecCAN2_oP2P_SecCH_GW_FrP08_oCAN02: start 31, 1 bit, big-endian, init-value=0, base-type=boolean, compu {0..1=RANGE, 0=Cx0_Valid, 1=Cx1_Invalid}, transfer-property=PENDING
      frame P2P_SecCH_GW_FrP10_oCAN02: id 0x3F1, from P2P, frame-length=8, can-addressing-mode=STANDARD
        pdu P2P_SecCH_GW_FrP10_oCAN02: length=8, transmission-mode-false-timing=cyclic-timing=time-period=0, transmission-mode-true-timing=cyclic-timing=time-period=0, unused-bit-pattern=0
          signal OtsdAirTemCrValV_h2_SecCAN2_oP2P_SecCH_GW_FrP10_oCAN02: start 48, 1 bit, big-endian, init-value=0, base-type=boolean, compu {0..1=RANGE, 0=Cx0_Valid, 1=Cx1_Invalid}, transfer-property=PENDING
          signal OtsdAirTemCrValMsk_h2_SecCAN2_oP2P_SecCH_GW_FrP10_oCAN02: start 51, 1 bit, big-endian, init-value=0, base-type=boolean, compu {0..1=RANGE, 0=Cx0_Don_t_Use_Data (Don't Use Data), 1=Cx1_Use_Data (Use Data)}, transfer-property=PENDING
          signal OtsdAirTemCrVal_h2_SecCAN2_oP2P_SecCH_GW_FrP10_oCAN02: start 63, 8 bit, big-endian, init-value=0, base-type=uint8, compu {phys=raw*0.5-40 for raw 0..255; unit degC}, unit=degC, transfer-property=PENDING
      frame P2P_SecCH_GW_FrP13_oCAN02: id 0x1A9, from P2P, frame-length=8, can-addressing-mode=STANDARD
        pdu P2P_SecCH_GW_FrP13_oCAN02: length=8, transmission-mode-false-timing=cyclic-timing=time-period=0, transmission-mode-true-timing=cyclic-timing=time-period=0, unused-bit-pattern=0
          signal NRCDSts_h2_SecCAN2_oP2P_SecCH_GW_FrP13_oCAN02: start 25, 2 bit, big-endian, init-value=0, base-type=uint8, compu {0..3=RANGE, 0=Cx0_Inactive, 1=Cx1_NRCD_Active (NRCD Active), 2=Cx2_Semiautomatic_Parking_Assistant_Active (Semiautomatic Parking Assistant Active), 3=Cx3_Fully_APA_Active (Fully-APA Active)}, transfer-property=PENDING
          signal APACtrlAbotdRsn_SecCAN2_oP2P_SecCH_GW_FrP13_oCAN02: start 47, 4 bit, big-endian, init-value=0, base-type=uint8, compu {0..15=RANGE, 0=Cx0_No_Aborted (No Aborted), 1=Cx1_Driver_interference_SCU (Driver interference SCU), 2=Cx2_Driver_interference_Braking_System (Driver interference Braking System), 3=Cx3_Charger_is_connected (Charger is connected), 4=Cx4_Communication_Error (Communication Error), 5=Cx5_In_post_collision (In post collision), 6=Cx6_Energy_Low (Energy Low), 7=Cx7_Gradient_over_threshold (Gradient over threshold), 8=Cx8_Crank_Failed (Crank Failed), 9=Cx9_Reserve, 10=CxA_Reserve, 11=CxB_Reserve, 12=CxC_Reserve, 13=CxD_Reserve, 14=CxE_Reserve, 15=CxF_Unknown_Reason (Unknown Reason)}, transfer-property=PENDING
      frame P2P_SecCH_GW_FrS00_oCAN02: id 0x6A3, from P2P, frame-length=8, can-addressing-mode=STANDARD
        pdu P2P_SecCH_GW_FrS00_oCAN02: length=8, unused-bit-pattern=0
          signal NRCDMstrChlg_h2_SecCAN2_oP2P_SecCH_GW_FrS00_oCAN02: start 0, 64 bit, opaque, init-value=8 x 0, base-type=uint8_8_iso_8859_1, compu {0=RANGE}, transfer-property=PENDING
      frame P2P_SecCH_HCU_ECM_FrP04_oCAN02: id 0x194, from P2P, frame-length=8, can-addressing-mode=STANDARD
        pdu P2P_SecCH_HCU_ECM_FrP04_oCAN02: length=8, transmission-mode-false-timing=cyclic-timing=time-period=0, transmission-mode-true-timing=cyclic-timing=time-period=0, unused-bit-pattern=0
          signal TrShftLvrPos_h1_SecCAN2_oP2P_SecCH_HCU_ECM_FrP04_oCAN02: start 27, 4 bit, big-endian, init-value=0, base-type=uint8, compu {0..15=RANGE, 0=Cx0_Between_Ranges (Between Ranges), 1=Cx1_Park_Range (Park Range), 2=Cx2_Reverse_Range (Reverse Range), 3=Cx3_Neutral_Range (Neutral Range), 4=Cx4_Forward_Range_A (Forward Range A), 5=Cx5_Forward_Range_B (Forward Range B), 6=Cx6_Forward_Range_C (Forward Range C), 7=Cx7_Forward_Range_D (Forward Range D), 8=Cx8_Forward_Range_E (Forward Range E), 9=Cx9_Forward_Range_F (Forward Range F), 10=CxA_Forward_Range_G (Forward Range G), 11=CxB_Forward_Range_H (Forward Range H), 15=CxF_Lever_Position_Unknown (Lever Position Unknown)}, transfer-property=PENDING
          signal TrShftLvrPosV_h1_SecCAN2_oP2P_SecCH_HCU_ECM_FrP04_oCAN02: start 28, 1 bit, big-endian, init-value=0, base-type=boolean, compu {0..1=RANGE, 0=Cx0_Valid, 1=Cx1_Invalid}, transfer-property=PENDING
      frame P2P_SecCH_HCU_FrP00_oCAN02: id 0xAF, from P2P, frame-length=8, can-addressing-mode=STANDARD
        pdu P2P_SecCH_HCU_FrP00_oCAN02: length=8, transmission-mode-false-timing=cyclic-timing=time-period=0, transmission-mode-true-timing=cyclic-timing=time-period=0, unused-bit-pattern=0
          signal EPTAccelActuPos_SecCAN2_oP2P_SecCH_HCU_FrP00_oCAN02: start 7, 8 bit, big-endian, init-value=0, base-type=uint8, compu {phys=raw*0.392157 for raw 0..254; unit %}, unit=%, transfer-property=PENDING
          signal EPTBrkPdlDscrtInptStsV_SecCAN2_oP2P_SecCH_HCU_FrP00_oCAN02: start 16, 1 bit, big-endian, init-value=1, base-type=boolean, compu {0..1=RANGE, 0=Cx0_Valid, 1=Cx1_Invalid}, transfer-property=PENDING  # Electric Powertrain Brake Pedal Discrete Input Status Validity
          signal EPTStCmdOn_h1_SecCAN2_oP2P_SecCH_HCU_FrP00_oCAN02: start 17, 1 bit, big-endian, init-value=0, base-type=boolean, compu {0..1=RANGE, 0=Cx0_False, 1=Cx1_True}, transfer-property=PENDING
          signal EPTBrkPdlDscrtInptSts_SecCAN2_oP2P_SecCH_HCU_FrP00_oCAN02: start 31, 1 bit, big-endian, init-value=0, base-type=boolean, compu {0..1=RANGE, 0=Cx0_Brake_Not_Applied (Brake Not Applied), 1=Cx1_Brake_Applied (Brake Applied)}, transfer-property=PENDING
          signal EPTAccelActuPosV_SecCAN2_oP2P_SecCH_HCU_FrP00_oCAN02: start 43, 1 bit, big-endian, init-value=0, base-type=boolean, compu {0..1=RANGE, 0=Cx0_Valid, 1=Cx1_Invalid}, transfer-property=PENDING
      frame P2P_SecCH_HCU_FrP01_oCAN02: id 0x196, from P2P, frame-length=8, can-addressing-mode=STANDARD
        pdu P2P_SecCH_HCU_FrP01_oCAN02: length=8, transmission-mode-false-timing=cyclic-timing=time-period=0, transmission-mode-true-timing=cyclic-timing=time-period=0, unused-bit-pattern=0
          signal EPTRdy_h1_SecCAN2_oP2P_SecCH_HCU_FrP01_oCAN02: start 38, 1 bit, big-endian, init-value=0, base-type=boolean, compu {0..1=RANGE, 0=Cx0_Not_ready (Not ready), 1=Cx1_Ready}, transfer-property=PENDING
      frame P2P_SecCH_HCU_FrP13_oCAN02: id 0x19C, from P2P, frame-length=8, can-addressing-mode=STANDARD
        pdu P2P_SecCH_HCU_FrP13_oCAN02: length=8, transmission-mode-false-timing=cyclic-timing=time-period=0, transmission-mode-true-timing=cyclic-timing=time-period=0, unused-bit-pattern=0
          signal VCUNRCDAvlbl_SecCAN2_oP2P_SecCH_HCU_FrP13_oCAN02: start 52, 1 bit, big-endian, init-value=0, base-type=boolean, compu {0..1=RANGE, 0=Cx0_Unavailable, 1=Cx1_Available}, transfer-property=PENDING
          signal VCUAccReqSts_SecCAN2_oP2P_SecCH_HCU_FrP13_oCAN02: start 53, 1 bit, big-endian, init-value=0, base-type=boolean, compu {0..1=RANGE, 0=Cx0_No_Request (No Request), 1=Cx1_Request}, transfer-property=PENDING
          signal VCUAccReqVal_SecCAN2_oP2P_SecCH_HCU_FrP13_oCAN02: start 63, 8 bit, big-endian, init-value=0, base-type=uint8, compu {phys=raw*0.1-12.7 for raw 0..255}, transfer-property=PENDING
      frame P2P_SecCH_IPK_FrP06_oCAN02: id 0x541, from P2P, frame-length=8, can-addressing-mode=STANDARD
        pdu P2P_SecCH_IPK_FrP06_oCAN02: length=8, transmission-mode-false-timing=cyclic-timing=time-period=0, transmission-mode-true-timing=cyclic-timing=time-period=0, unused-bit-pattern=0
          signal CalendarYear_SecCAN2_oP2P_SecCH_IPK_FrP06_oCAN02: start 7, 8 bit, big-endian, init-value=0, base-type=uint8, compu {phys=raw+2000 for raw 0..255; unit year}, unit=year, transfer-property=PENDING
          signal CalendarMonth_SecCAN2_oP2P_SecCH_IPK_FrP06_oCAN02: start 11, 4 bit, big-endian, init-value=0, base-type=uint8, compu {0..15=RANGE, 0=Cx0_Unknown, 1=Cx1_January, 2=Cx2_February, 3=Cx3_March, 4=Cx4_April, 5=Cx5_May, 6=Cx6_June, 7=Cx7_July, 8=Cx8_August, 9=Cx9_September, 10=CxA_October, 11=CxB_November, 12=CxC_December}, transfer-property=PENDING
          signal CalendarDay_SecCAN2_oP2P_SecCH_IPK_FrP06_oCAN02: start 20, 5 bit, big-endian, init-value=0, base-type=uint8, compu {0..31=RANGE; unit days}, unit=days, transfer-property=PENDING
          signal HourOfDay_SecCAN2_oP2P_SecCH_IPK_FrP06_oCAN02: start 28, 5 bit, big-endian, init-value=0, base-type=uint8, compu {0..23=RANGE}, transfer-property=PENDING
          signal MinuteOfHour_SecCAN2_oP2P_SecCH_IPK_FrP06_oCAN02: start 37, 6 bit, big-endian, init-value=0, base-type=uint8, compu {0..59=RANGE}, transfer-property=PENDING
          signal SecsOfMinute_SecCAN2_oP2P_SecCH_IPK_FrP06_oCAN02: start 45, 6 bit, big-endian, init-value=0, base-type=uint8, compu {0..59=RANGE}, transfer-property=PENDING
          signal TimeDspFmt_SecCAN2_oP2P_SecCH_IPK_FrP06_oCAN02: start 46, 1 bit, big-endian, init-value=0, base-type=boolean, compu {0..1=RANGE, 0=Cx0_12_hour_mode (12 hour mode), 1=Cx1_24_hour_mode (24 hour mode)}, transfer-property=PENDING
      frame P2P_SecCH_SAS_FrP00_oCAN02: id 0x1E5, from P2P, frame-length=8, can-addressing-mode=STANDARD
        pdu P2P_SecCH_SAS_FrP00_oCAN02: length=8, transmission-mode-false-timing=cyclic-timing=time-period=0, transmission-mode-true-timing=cyclic-timing=time-period=0, unused-bit-pattern=0
          signal StrgWhlAngV_SecCAN2_oP2P_SecCH_SAS_FrP00_oCAN02: start 7, 1 bit, big-endian, init-value=0, base-type=boolean, compu {0..1=RANGE, 0=Cx0_Valid, 1=Cx1_Invalid}, transfer-property=PENDING
          signal StrgWhlAng_SecCAN2_oP2P_SecCH_SAS_FrP00_oCAN02: start 15, 16 bit, big-endian, init-value=0, base-type=uint16, compu {65535=CxFFFF_error_mark (error mark), phys=raw*0.0625-2048 for raw 0..65535; unit degree} "Source signal range: [0,65534.08]", unit=degree, transfer-property=PENDING
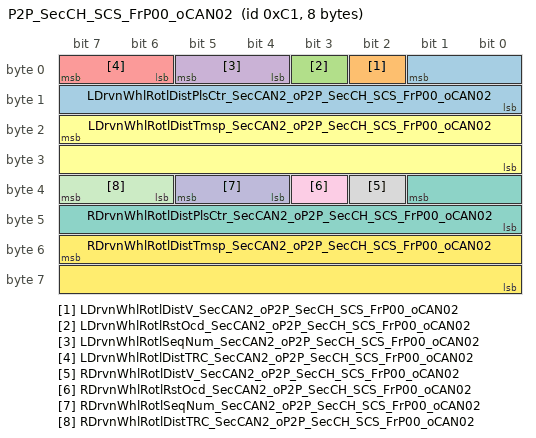
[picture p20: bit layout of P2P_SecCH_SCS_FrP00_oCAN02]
      frame P2P_SecCH_SCS_FrP00_oCAN02: id 0xC1, from P2P, frame-length=8, can-addressing-mode=STANDARD
        pdu P2P_SecCH_SCS_FrP00_oCAN02: length=8, transmission-mode-false-timing=cyclic-timing=time-period=0, transmission-mode-true-timing=cyclic-timing=time-period=0, unused-bit-pattern=0
          signal LDrvnWhlRotlDistPlsCtr_SecCAN2_oP2P_SecCH_SCS_FrP00_oCAN02: start 1, 10 bit, big-endian, init-value=0, base-type=uint16, compu {0..1023=RANGE}, transfer-property=PENDING
          signal LDrvnWhlRotlDistV_SecCAN2_oP2P_SecCH_SCS_FrP00_oCAN02: start 2, 1 bit, big-endian, init-value=0, base-type=boolean, compu {0..1=RANGE, 0=Cx0_Valid, 1=Cx1_Invalid}, transfer-property=PENDING
          signal LDrvnWhlRotlRstOcd_SecCAN2_oP2P_SecCH_SCS_FrP00_oCAN02: start 3, 1 bit, big-endian, init-value=0, base-type=boolean, compu {0..1=RANGE, 0=Cx0_False, 1=Cx1_True}, transfer-property=PENDING
          signal LDrvnWhlRotlSeqNum_SecCAN2_oP2P_SecCH_SCS_FrP00_oCAN02: start 5, 2 bit, big-endian, init-value=0, base-type=uint8, compu {0..3=RANGE}, transfer-property=PENDING
          signal LDrvnWhlRotlDistTRC_SecCAN2_oP2P_SecCH_SCS_FrP00_oCAN02: start 7, 2 bit, big-endian, init-value=0, base-type=uint8, compu {0..3=RANGE}, transfer-property=PENDING
          signal LDrvnWhlRotlDistTmsp_SecCAN2_oP2P_SecCH_SCS_FrP00_oCAN02: start 23, 16 bit, big-endian, init-value=0, base-type=uint16, compu {0..65535=RANGE}, transfer-property=PENDING
          signal RDrvnWhlRotlDistPlsCtr_SecCAN2_oP2P_SecCH_SCS_FrP00_oCAN02: start 33, 10 bit, big-endian, init-value=0, base-type=uint16, compu {0..1023=RANGE}, transfer-property=PENDING
          signal RDrvnWhlRotlDistV_SecCAN2_oP2P_SecCH_SCS_FrP00_oCAN02: start 34, 1 bit, big-endian, init-value=0, base-type=boolean, compu {0..1=RANGE, 0=Cx0_Valid, 1=Cx1_Invalid}, transfer-property=PENDING
          signal RDrvnWhlRotlRstOcd_SecCAN2_oP2P_SecCH_SCS_FrP00_oCAN02: start 35, 1 bit, big-endian, init-value=0, base-type=boolean, compu {0..1=RANGE, 0=Cx0_False, 1=Cx1_True}, transfer-property=PENDING
          signal RDrvnWhlRotlSeqNum_SecCAN2_oP2P_SecCH_SCS_FrP00_oCAN02: start 37, 2 bit, big-endian, init-value=0, base-type=uint8, compu {0..3=RANGE}, transfer-property=PENDING
          signal RDrvnWhlRotlDistTRC_SecCAN2_oP2P_SecCH_SCS_FrP00_oCAN02: start 39, 2 bit, big-endian, init-value=0, base-type=uint8, compu {0..3=RANGE}, transfer-property=PENDING
          signal RDrvnWhlRotlDistTmsp_SecCAN2_oP2P_SecCH_SCS_FrP00_oCAN02: start 55, 16 bit, big-endian, init-value=0, base-type=uint16, compu {0..65535=RANGE}, transfer-property=PENDING
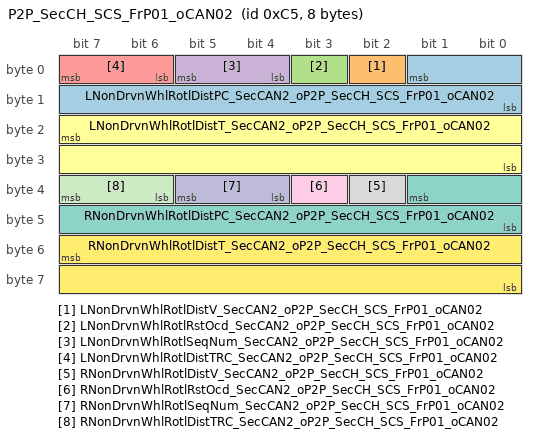
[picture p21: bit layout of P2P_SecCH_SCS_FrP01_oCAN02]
      frame P2P_SecCH_SCS_FrP01_oCAN02: id 0xC5, from P2P, frame-length=8, can-addressing-mode=STANDARD
        pdu P2P_SecCH_SCS_FrP01_oCAN02: length=8, transmission-mode-false-timing=cyclic-timing=time-period=0, transmission-mode-true-timing=cyclic-timing=time-period=0, unused-bit-pattern=0
          signal LNonDrvnWhlRotlDistPC_SecCAN2_oP2P_SecCH_SCS_FrP01_oCAN02: start 1, 10 bit, big-endian, init-value=0, base-type=uint16, compu {0..1023=RANGE}, transfer-property=PENDING
          signal LNonDrvnWhlRotlDistV_SecCAN2_oP2P_SecCH_SCS_FrP01_oCAN02: start 2, 1 bit, big-endian, init-value=0, base-type=boolean, compu {0..1=RANGE, 0=Cx0_Valid, 1=Cx1_Invalid}, transfer-property=PENDING
          signal LNonDrvnWhlRotlRstOcd_SecCAN2_oP2P_SecCH_SCS_FrP01_oCAN02: start 3, 1 bit, big-endian, init-value=0, base-type=boolean, compu {0..1=RANGE, 0=Cx0_False, 1=Cx1_True}, transfer-property=PENDING
          signal LNonDrvnWhlRotlSeqNum_SecCAN2_oP2P_SecCH_SCS_FrP01_oCAN02: start 5, 2 bit, big-endian, init-value=0, base-type=uint8, compu {0..3=RANGE}, transfer-property=PENDING
          signal LNonDrvnWhlRotlDistTRC_SecCAN2_oP2P_SecCH_SCS_FrP01_oCAN02: start 7, 2 bit, big-endian, init-value=0, base-type=uint8, compu {0..3=RANGE}, transfer-property=PENDING
          signal LNonDrvnWhlRotlDistT_SecCAN2_oP2P_SecCH_SCS_FrP01_oCAN02: start 23, 16 bit, big-endian, init-value=0, base-type=uint16, compu {0..65535=RANGE}, transfer-property=PENDING
          signal RNonDrvnWhlRotlDistPC_SecCAN2_oP2P_SecCH_SCS_FrP01_oCAN02: start 33, 10 bit, big-endian, init-value=0, base-type=uint16, compu {0..1023=RANGE}, transfer-property=PENDING
          signal RNonDrvnWhlRotlDistV_SecCAN2_oP2P_SecCH_SCS_FrP01_oCAN02: start 34, 1 bit, big-endian, init-value=0, base-type=boolean, compu {0..1=RANGE, 0=Cx0_Valid, 1=Cx1_Invalid}, transfer-property=PENDING
          signal RNonDrvnWhlRotlRstOcd_SecCAN2_oP2P_SecCH_SCS_FrP01_oCAN02: start 35, 1 bit, big-endian, init-value=0, base-type=boolean, compu {0..1=RANGE, 0=Cx0_False, 1=Cx1_True}, transfer-property=PENDING
          signal RNonDrvnWhlRotlSeqNum_SecCAN2_oP2P_SecCH_SCS_FrP01_oCAN02: start 37, 2 bit, big-endian, init-value=0, base-type=uint8, compu {0..3=RANGE}, transfer-property=PENDING
          signal RNonDrvnWhlRotlDistTRC_SecCAN2_oP2P_SecCH_SCS_FrP01_oCAN02: start 39, 2 bit, big-endian, init-value=0, base-type=uint8, compu {0..3=RANGE}, transfer-property=PENDING
          signal RNonDrvnWhlRotlDistT_SecCAN2_oP2P_SecCH_SCS_FrP01_oCAN02: start 55, 16 bit, big-endian, init-value=0, base-type=uint16, compu {0..65535=RANGE}, transfer-property=PENDING
      frame P2P_SecCH_SCS_FrP02_oCAN02: id 0x185, from P2P, frame-length=4, can-addressing-mode=STANDARD
        pdu P2P_SecCH_SCS_FrP02_oCAN02: length=4, transmission-mode-false-timing=cyclic-timing=time-period=0, transmission-mode-true-timing=cyclic-timing=time-period=0, unused-bit-pattern=0
          signal VSELongtAcc_SecCAN2_oP2P_SecCH_SCS_FrP02_oCAN02: start 1, 10 bit, big-endian, init-value=0, base-type=sint16, compu {phys=raw*0.03 for raw -512..511; unit m/s^2}, unit=m/s^2, transfer-property=PENDING
          signal VSELongtAccV_SecCAN2_oP2P_SecCH_SCS_FrP02_oCAN02: start 2, 1 bit, big-endian, init-value=0, base-type=boolean, compu {0..1=RANGE, 0=Cx0_Valid, 1=Cx1_Invalid}, transfer-property=PENDING
          signal VSELatAccV_SecCAN2_oP2P_SecCH_SCS_FrP02_oCAN02: start 3, 1 bit, big-endian, init-value=0, base-type=boolean, compu {0..1=RANGE, 0=Cx0_Valid, 1=Cx1_Invalid}, transfer-property=PENDING
          signal VSELatAcc_SecCAN2_oP2P_SecCH_SCS_FrP02_oCAN02: start 19, 12 bit, big-endian, init-value=0, base-type=sint16, compu {phys=raw/64 for raw -2048..2047; unit m/s^2}, unit=m/s^2, transfer-property=PENDING
      frame P2P_SecCH_SCS_FrP03_oCAN02: id 0x1C7, from P2P, frame-length=8, can-addressing-mode=STANDARD
        pdu P2P_SecCH_SCS_FrP03_oCAN02: length=8, transmission-mode-false-timing=cyclic-timing=time-period=0, transmission-mode-true-timing=cyclic-timing=time-period=0, unused-bit-pattern=0
          signal LNonDrvnWhlRotlDircn_SecCAN2_oP2P_SecCH_SCS_FrP03_oCAN02: start 33, 2 bit, big-endian, init-value=3, base-type=uint8, compu {0..3=RANGE, 0=Cx0_No_moving (No moving), 1=Cx1_Moving_forward (Moving forward), 2=Cx2_Moving_backward (Moving backward), 3=Cx3_Error_Invalid (Error/Invalid)}, transfer-property=PENDING
          signal RNonDrvnWhlRotlDircn_SecCAN2_oP2P_SecCH_SCS_FrP03_oCAN02: start 35, 2 bit, big-endian, init-value=3, base-type=uint8, compu {0..3=RANGE, 0=Cx0_No_moving (No moving), 1=Cx1_Moving_forward (Moving forward), 2=Cx2_Moving_backward (Moving backward), 3=Cx3_Error_Invalid (Error/Invalid)}, transfer-property=PENDING
          signal SCSAPAAlvRC_SecCAN2_oP2P_SecCH_SCS_FrP03_oCAN02: start 39, 4 bit, big-endian, init-value=0, base-type=uint8, compu {0..15=RANGE}, transfer-property=PENDING
          signal SCSNRCDAvlbl_SecCAN2_oP2P_SecCH_SCS_FrP03_oCAN02: start 45, 1 bit, big-endian, init-value=0, base-type=boolean, compu {0..1=RANGE, 0=Cx0_Unavailable_, 1=Cx1_Available_}, transfer-property=PENDING  # Stability Control System Near Range Control Drive Available
          signal SCSAPAAcclA_SecCAN2_oP2P_SecCH_SCS_FrP03_oCAN02: start 46, 1 bit, big-endian, init-value=0, base-type=boolean, compu {0..1=RANGE, 0=Cx0_Inactive, 1=Cx1_Active}, transfer-property=PENDING
          signal SCSAPAAvlbl_SecCAN2_oP2P_SecCH_SCS_FrP03_oCAN02: start 47, 1 bit, big-endian, init-value=0, base-type=boolean, compu {0..1=RANGE, 0=Cx0_Unavailable, 1=Cx1_Available}, transfer-property=PENDING
      frame P2P_SecCH_SCS_FrP05_oCAN02: id 0x1E9, from P2P, frame-length=8, can-addressing-mode=STANDARD
        pdu P2P_SecCH_SCS_FrP05_oCAN02: length=8, transmission-mode-false-timing=cyclic-timing=time-period=0, transmission-mode-true-timing=cyclic-timing=time-period=0, unused-bit-pattern=0
          signal VSESysA_SecCAN2_oP2P_SecCH_SCS_FrP05_oCAN02: start 24, 1 bit, big-endian, init-value=0, base-type=boolean, compu {0..1=RANGE, 0=Cx0_False, 1=Cx1_True}, transfer-property=PENDING
          signal TCSA_SecCAN2_oP2P_SecCH_SCS_FrP05_oCAN02: start 28, 1 bit, big-endian, init-value=0, base-type=boolean, compu {0..1=RANGE, 0=Cx0_False, 1=Cx1_True}, transfer-property=PENDING
          signal ABSA_SecCAN2_oP2P_SecCH_SCS_FrP05_oCAN02: start 30, 1 bit, big-endian, init-value=0, base-type=boolean, compu {0..1=RANGE, 0=Cx0_False, 1=Cx1_True}, transfer-property=PENDING
          signal VehDynYawRate_SecCAN2_oP2P_SecCH_SCS_FrP05_oCAN02: start 35, 12 bit, big-endian, init-value=0, base-type=sint16, compu {phys=raw*0.0625 for raw -2048..2047; unit deg/s}, unit=deg/s, transfer-property=PENDING
          signal VehDynYawRateV_SecCAN2_oP2P_SecCH_SCS_FrP05_oCAN02: start 36, 1 bit, big-endian, init-value=0, base-type=boolean, compu {0..1=RANGE, 0=Cx0_Valid, 1=Cx1_Invalid}, transfer-property=PENDING
      frame P2P_SecCH_SCS_FrP11_oCAN02: id 0x348, from P2P, frame-length=8, can-addressing-mode=STANDARD
        pdu P2P_SecCH_SCS_FrP11_oCAN02: length=8, transmission-mode-false-timing=cyclic-timing=time-period=0, transmission-mode-true-timing=cyclic-timing=time-period=0, unused-bit-pattern=0
          signal WhlGndVelLDrvn_SecCAN2_oP2P_SecCH_SCS_FrP11_oCAN02: start 5, 14 bit, big-endian, init-value=0, base-type=uint16, compu {phys=raw/32 for raw 0..16383; unit km/h}, unit=km/h, transfer-property=PENDING
          signal WhlGndVelLDrvnV_SecCAN2_oP2P_SecCH_SCS_FrP11_oCAN02: start 6, 1 bit, big-endian, init-value=1, base-type=boolean, compu {0..1=RANGE, 0=Cx0_Valid, 1=Cx1_Invalid}, transfer-property=PENDING  # Wheel Ground Velocity Left Driven Validity
          signal WhlGndVelRDrvn_SecCAN2_oP2P_SecCH_SCS_FrP11_oCAN02: start 21, 14 bit, big-endian, init-value=0, base-type=uint16, compu {phys=raw/32 for raw 0..16383; unit km/h}, unit=km/h, transfer-property=PENDING
          signal WhlGndVelRDrvnV_SecCAN2_oP2P_SecCH_SCS_FrP11_oCAN02: start 22, 1 bit, big-endian, init-value=1, base-type=boolean, compu {0..1=RANGE, 0=Cx0_Valid, 1=Cx1_Invalid}, transfer-property=PENDING  # Wheel Ground Velocity Right Driven Validity
      frame P2P_SecCH_SCS_FrP12_oCAN02: id 0x34A, from P2P, frame-length=8, can-addressing-mode=STANDARD
        pdu P2P_SecCH_SCS_FrP12_oCAN02: length=8, transmission-mode-false-timing=cyclic-timing=time-period=0, transmission-mode-true-timing=cyclic-timing=time-period=0, unused-bit-pattern=0
          signal WhlGndVelLNonDrvn_SecCAN2_oP2P_SecCH_SCS_FrP12_oCAN02: start 5, 14 bit, big-endian, init-value=0, base-type=uint16, compu {phys=raw/32 for raw 0..16383; unit km/h}, unit=km/h, transfer-property=PENDING
          signal WhlGndVelLNonDrvnV_SecCAN2_oP2P_SecCH_SCS_FrP12_oCAN02: start 6, 1 bit, big-endian, init-value=1, base-type=boolean, compu {0..1=RANGE, 0=Cx0_Valid, 1=Cx1_Invalid}, transfer-property=PENDING  # Wheel Ground Velocity Left Non Driven Validity
          signal WhlGndVelRNonDrvn_SecCAN2_oP2P_SecCH_SCS_FrP12_oCAN02: start 21, 14 bit, big-endian, init-value=0, base-type=uint16, compu {phys=raw/32 for raw 0..16383; unit km/h}, unit=km/h, transfer-property=PENDING
          signal WhlGndVelRNonDrvnV_SecCAN2_oP2P_SecCH_SCS_FrP12_oCAN02: start 22, 1 bit, big-endian, init-value=1, base-type=boolean, compu {0..1=RANGE, 0=Cx0_Valid, 1=Cx1_Invalid}, transfer-property=PENDING  # Wheel Ground Velocity Right Non Driven Validity
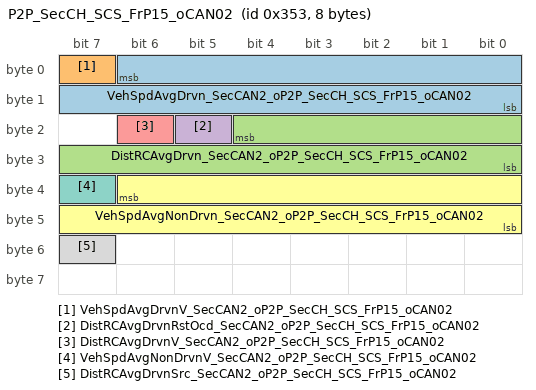
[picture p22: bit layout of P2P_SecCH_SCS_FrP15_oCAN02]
      frame P2P_SecCH_SCS_FrP15_oCAN02: id 0x353, from P2P, frame-length=8, can-addressing-mode=STANDARD
        pdu P2P_SecCH_SCS_FrP15_oCAN02: length=8, transmission-mode-false-timing=cyclic-timing=time-period=0, transmission-mode-true-timing=cyclic-timing=time-period=0, unused-bit-pattern=0
          signal VehSpdAvgDrvn_SecCAN2_oP2P_SecCH_SCS_FrP15_oCAN02: start 6, 15 bit, big-endian, init-value=0, base-type=uint16, compu {phys=raw/64 for raw 0..32766; unit km/h}, unit=km/h, transfer-property=PENDING
          signal VehSpdAvgDrvnV_SecCAN2_oP2P_SecCH_SCS_FrP15_oCAN02: start 7, 1 bit, big-endian, init-value=0, base-type=boolean, compu {0..1=RANGE, 0=Cx0_Valid, 1=Cx1_Invalid}, transfer-property=PENDING
          signal DistRCAvgDrvn_SecCAN2_oP2P_SecCH_SCS_FrP15_oCAN02: start 20, 13 bit, big-endian, init-value=0, base-type=uint16, compu {phys=raw*0.125 for raw 0..8191; unit m}, unit=m, transfer-property=PENDING
          signal DistRCAvgDrvnRstOcd_SecCAN2_oP2P_SecCH_SCS_FrP15_oCAN02: start 21, 1 bit, big-endian, init-value=0, base-type=boolean, compu {0..1=RANGE, 0=Cx0_False, 1=Cx1_True}, transfer-property=PENDING
          signal DistRCAvgDrvnV_SecCAN2_oP2P_SecCH_SCS_FrP15_oCAN02: start 22, 1 bit, big-endian, init-value=0, base-type=boolean, compu {0..1=RANGE, 0=Cx0_Valid, 1=Cx1_Invalid}, transfer-property=PENDING
          signal VehSpdAvgNonDrvn_SecCAN2_oP2P_SecCH_SCS_FrP15_oCAN02: start 38, 15 bit, big-endian, init-value=0, base-type=uint16, compu {phys=raw/64 for raw 0..32766; unit km/h}, unit=km/h, transfer-property=PENDING
          signal VehSpdAvgNonDrvnV_SecCAN2_oP2P_SecCH_SCS_FrP15_oCAN02: start 39, 1 bit, big-endian, init-value=0, base-type=boolean, compu {0..1=RANGE, 0=Cx0_Valid, 1=Cx1_Invalid}, transfer-property=PENDING
          signal DistRCAvgDrvnSrc_SecCAN2_oP2P_SecCH_SCS_FrP15_oCAN02: start 55, 1 bit, big-endian, init-value=0, base-type=boolean, compu {0..1=RANGE, 0=Cx0_Transmission_Output_Speed (Transmission Output Speed), 1=Cx1_Wheel_Speed (Wheel Speed)}, transfer-property=PENDING  # Distance Rolling Count Average Driven Source
      frame P2P_SecCH_SCU_FrP00_oCAN02: id 0x9D, from P2P, frame-length=8, can-addressing-mode=STANDARD
        pdu P2P_SecCH_SCU_FrP00_oCAN02: length=8, transmission-mode-false-timing=cyclic-timing=time-period=0, transmission-mode-true-timing=cyclic-timing=time-period=0, unused-bit-pattern=0
          signal SCUDrvrIntrvnA_SecCAN2_oP2P_SecCH_SCU_FrP00_oCAN02: start 2, 1 bit, big-endian, init-value=0, base-type=boolean, compu {0..1=RANGE, 0=Cx0_Inactive, 1=Cx1_Active}, transfer-property=PENDING
          signal SCUNRCDAvlbl_SecCAN2_oP2P_SecCH_SCU_FrP00_oCAN02: start 3, 1 bit, big-endian, init-value=0, base-type=boolean, compu {0..1=RANGE, 0=Cx0_Unavailable, 1=Cx1_Available}, transfer-property=PENDING
      frame P2P_SecCH_SDM_FrP00_oCAN02: id 0x163, from P2P, frame-length=8, can-addressing-mode=STANDARD
        pdu P2P_SecCH_SDM_FrP00_oCAN02: length=8, transmission-mode-false-timing=cyclic-timing=time-period=0, transmission-mode-true-timing=cyclic-timing=time-period=0, unused-bit-pattern=0
          signal DrvrSbltAtc_SecCAN2_oP2P_SecCH_SDM_FrP00_oCAN02: start 12, 1 bit, big-endian, init-value=0, base-type=boolean, compu {0..1=RANGE, 0=Cx0_False, 1=Cx1_True}, transfer-property=PENDING
          signal DrvrSbltAtcV_SecCAN2_oP2P_SecCH_SDM_FrP00_oCAN02: start 13, 1 bit, big-endian, init-value=0, base-type=boolean, compu {0..1=RANGE, 0=Cx0_Valid, 1=Cx1_Invalid}, transfer-property=PENDING
      frame P2P_SecCH_TC_FrP07_oCAN02: id 0x94, from P2P, frame-length=8, can-addressing-mode=STANDARD
        pdu P2P_SecCH_TC_FrP07_oCAN02: length=8, transmission-mode-false-timing=cyclic-timing=time-period=0, transmission-mode-true-timing=cyclic-timing=time-period=0, unused-bit-pattern=0
          signal TMSpd_h1_SecCAN2_oP2P_SecCH_TC_FrP07_oCAN02: start 7, 16 bit, big-endian, init-value=32768, base-type=uint16, compu {phys=raw-32768 for raw 0..65535; unit rpm}, unit=rpm, transfer-property=PENDING
          signal TMSpdV_h1_SecCAN2_oP2P_SecCH_TC_FrP07_oCAN02: start 23, 1 bit, big-endian, init-value=1, base-type=boolean, compu {0..1=RANGE, 0=Cx0_Valid, 1=Cx1_Invalid}, transfer-property=PENDING
      frame P2P_SecCH_Tester_GW_FrP14_oCAN02: id 0x1AD, from P2P, frame-length=8, can-addressing-mode=STANDARD
        pdu P2P_SecCH_Tester_GW_FrP14_oCAN02: length=8, transmission-mode-false-timing=cyclic-timing=time-period=0, transmission-mode-true-timing=cyclic-timing=time-period=0, unused-bit-pattern=0
          signal NRCDF_SecCAN2_oP2P_SecCH_Tester_GW_FrP14_oCAN02: start 21, 1 bit, big-endian, init-value=0, base-type=boolean, compu {0..1=RANGE, 0=Cx0_Normal, 1=Cx1_NRCD_failure (NRCD failure)}, transfer-property=PENDING  # Near Range Control Drive Failed
          signal NRCDAlvRC_SecCAN2_oP2P_SecCH_Tester_GW_FrP14_oCAN02: start 55, 8 bit, big-endian, init-value=0, base-type=uint8, compu {0..255=RANGE}, transfer-property=PENDING  # Near Range Control Drive Alive Rolling Count
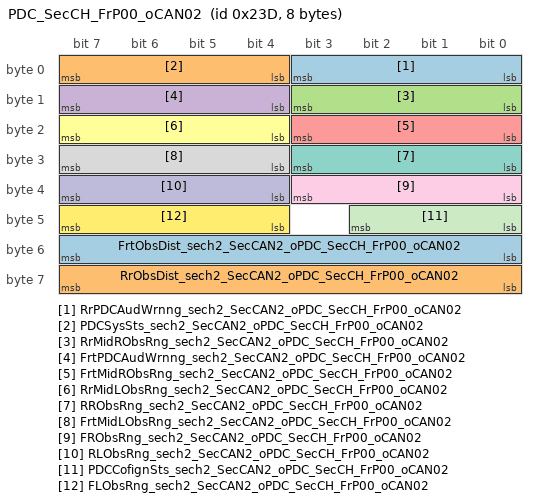
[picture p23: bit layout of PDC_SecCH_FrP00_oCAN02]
      frame PDC_SecCH_FrP00_oCAN02: id 0x23D, to P2P, frame-length=8, can-addressing-mode=STANDARD
        pdu PDC_SecCH_FrP00_oCAN02: length=8, transmission-mode-false-timing=cyclic-timing=time-period=0, transmission-mode-true-timing=cyclic-timing=time-period=0, unused-bit-pattern=0
          signal RrPDCAudWrnng_sech2_SecCAN2_oPDC_SecCH_FrP00_oCAN02: start 3, 4 bit, big-endian, init-value=0, base-type=uint8, compu {0..15=RANGE, 0=Cx0_No_Obstacle (No Obstacle), 1=Cx1_Range_1 (Range 1), 2=Cx2_Range_2 (Range 2), 3=Cx3_Range_3 (Range 3), 4=Cx4_Range_4 (Range 4), 5=Cx5_Range_5 (Range 5), 6=Cx6_Range_6 (Range 6), 7=Cx7_Range_7 (Range 7), 8=Cx8_Range_8 (Range 8), 9=Cx9_Range_9 (Range 9), 10=CxA_Range_10 (Range 10), 11=CxB_Range_11 (Range 11), 12=CxC_Range_12 (Range 12), 13=CxD_Range_13 (Range 13), 14=CxE_Range_14 (Range 14), 15=CxF_Range_15 (Range 15)}, transfer-property=PENDING, to P2P
          signal PDCSysSts_sech2_SecCAN2_oPDC_SecCH_FrP00_oCAN02: start 7, 4 bit, big-endian, init-value=0, base-type=uint8, compu {0..15=RANGE, 0=Cx0_System_OK (System OK), 1=Cx1_System_initialization_sucessful (System initialization sucessful), 2=Cx2_System_Failed (System Failed), 3=Cx3_System_Disabled (System Disabled), 4=Cx4_Front_PDC_Disabled (Front PDC Disabled), 5=Cx5_Front_PDC_Failed (Front PDC Failed), 6=Cx6_Rear_PDC_Failed (Rear PDC Failed), 7=Cx7_Rear_PDC_Disabled (Rear PDC Disabled)}, transfer-property=PENDING, to P2P
          signal RrMidRObsRng_sech2_SecCAN2_oPDC_SecCH_FrP00_oCAN02: start 11, 4 bit, big-endian, init-value=0, base-type=uint8, compu {0..15=RANGE, 0=Cx0_No_Obstacle (No Obstacle), 1=Cx1_Range_1 (Range 1), 2=Cx2_Range_2 (Range 2), 3=Cx3_Range_3 (Range 3), 4=Cx4_Range_4 (Range 4), 5=Cx5_Range_5 (Range 5), 6=Cx6_Range_6 (Range 6), 7=Cx7_Range_7 (Range 7), 8=Cx8_Range_8 (Range 8), 9=Cx9_Range_9 (Range 9), 10=CxA_Range_10 (Range 10), 11=CxB_Range_11 (Range 11), 12=CxC_Range_12 (Range 12), 13=CxD_Range_13 (Range 13), 14=CxE_Range_14 (Range 14), 15=CxF_Range_15 (Range 15)}, transfer-property=PENDING, to P2P
          signal FrtPDCAudWrnng_sech2_SecCAN2_oPDC_SecCH_FrP00_oCAN02: start 15, 4 bit, big-endian, init-value=0, base-type=uint8, compu {0..15=RANGE, 0=Cx0_No_Obstacle (No Obstacle), 1=Cx1_Range_1 (Range 1), 2=Cx2_Range_2 (Range 2), 3=Cx3_Range_3 (Range 3), 4=Cx4_Range_4 (Range 4), 5=Cx5_Range_5 (Range 5), 6=Cx6_Range_6 (Range 6), 7=Cx7_Range_7 (Range 7), 8=Cx8_Range_8 (Range 8), 9=Cx9_Range_9 (Range 9), 10=CxA_Range_10 (Range 10), 11=CxB_Range_11 (Range 11), 12=CxC_Range_12 (Range 12), 13=CxD_Range_13 (Range 13), 14=CxE_Range_14 (Range 14), 15=CxF_Range_15 (Range 15)}, transfer-property=PENDING, to P2P
          signal FrtMidRObsRng_sech2_SecCAN2_oPDC_SecCH_FrP00_oCAN02: start 19, 4 bit, big-endian, init-value=0, base-type=uint8, compu {0..15=RANGE, 0=Cx0_No_Obstacle (No Obstacle), 1=Cx1_Range_1 (Range 1), 2=Cx2_Range_2 (Range 2), 3=Cx3_Range_3 (Range 3), 4=Cx4_Range_4 (Range 4), 5=Cx5_Range_5 (Range 5), 6=Cx6_Range_6 (Range 6), 7=Cx7_Range_7 (Range 7), 8=Cx8_Range_8 (Range 8), 9=Cx9_Range_9 (Range 9), 10=CxA_Range_10 (Range 10), 11=CxB_Range_11 (Range 11), 12=CxC_Range_12 (Range 12), 13=CxD_Range_13 (Range 13), 14=CxE_Range_14 (Range 14), 15=CxF_Range_15 (Range 15)}, transfer-property=PENDING, to P2P
          signal RrMidLObsRng_sech2_SecCAN2_oPDC_SecCH_FrP00_oCAN02: start 23, 4 bit, big-endian, init-value=0, base-type=uint8, compu {0..15=RANGE, 0=Cx0_No_Obstacle (No Obstacle), 1=Cx1_Range_1 (Range 1), 2=Cx2_Range_2 (Range 2), 3=Cx3_Range_3 (Range 3), 4=Cx4_Range_4 (Range 4), 5=Cx5_Range_5 (Range 5), 6=Cx6_Range_6 (Range 6), 7=Cx7_Range_7 (Range 7), 8=Cx8_Range_8 (Range 8), 9=Cx9_Range_9 (Range 9), 10=CxA_Range_10 (Range 10), 11=CxB_Range_11 (Range 11), 12=CxC_Range_12 (Range 12), 13=CxD_Range_13 (Range 13), 14=CxE_Range_14 (Range 14), 15=CxF_Range_15 (Range 15)}, transfer-property=PENDING, to P2P
          signal RRObsRng_sech2_SecCAN2_oPDC_SecCH_FrP00_oCAN02: start 27, 4 bit, big-endian, init-value=0, base-type=uint8, compu {0..15=RANGE, 0=Cx0_No_Obstacle (No Obstacle), 1=Cx1_Range_1 (Range 1), 2=Cx2_Range_2 (Range 2), 3=Cx3_Range_3 (Range 3), 4=Cx4_Range_4 (Range 4), 5=Cx5_Range_5 (Range 5), 6=Cx6_Range_6 (Range 6), 7=Cx7_Range_7 (Range 7), 8=Cx8_Range_8 (Range 8), 9=Cx9_Range_9 (Range 9), 10=CxA_Range_10 (Range 10), 11=CxB_Range_11 (Range 11), 12=CxC_Range_12 (Range 12), 13=CxD_Range_13 (Range 13), 14=CxE_Range_14 (Range 14), 15=CxF_Range_15 (Range 15)}, transfer-property=PENDING, to P2P
          signal FrtMidLObsRng_sech2_SecCAN2_oPDC_SecCH_FrP00_oCAN02: start 31, 4 bit, big-endian, init-value=0, base-type=uint8, compu {0..15=RANGE, 0=Cx0_No_Obstacle (No Obstacle), 1=Cx1_Range_1 (Range 1), 2=Cx2_Range_2 (Range 2), 3=Cx3_Range_3 (Range 3), 4=Cx4_Range_4 (Range 4), 5=Cx5_Range_5 (Range 5), 6=Cx6_Range_6 (Range 6), 7=Cx7_Range_7 (Range 7), 8=Cx8_Range_8 (Range 8), 9=Cx9_Range_9 (Range 9), 10=CxA_Range_10 (Range 10), 11=CxB_Range_11 (Range 11), 12=CxC_Range_12 (Range 12), 13=CxD_Range_13 (Range 13), 14=CxE_Range_14 (Range 14), 15=CxF_Range_15 (Range 15)}, transfer-property=PENDING, to P2P
          signal FRObsRng_sech2_SecCAN2_oPDC_SecCH_FrP00_oCAN02: start 35, 4 bit, big-endian, init-value=0, base-type=uint8, compu {0..15=RANGE, 0=Cx0_No_Obstacle (No Obstacle), 1=Cx1_Range_1 (Range 1), 2=Cx2_Range_2 (Range 2), 3=Cx3_Range_3 (Range 3), 4=Cx4_Range_4 (Range 4), 5=Cx5_Range_5 (Range 5), 6=Cx6_Range_6 (Range 6), 7=Cx7_Range_7 (Range 7), 8=Cx8_Range_8 (Range 8), 9=Cx9_Range_9 (Range 9), 10=CxA_Range_10 (Range 10), 11=CxB_Range_11 (Range 11), 12=CxC_Range_12 (Range 12), 13=CxD_Range_13 (Range 13), 14=CxE_Range_14 (Range 14), 15=CxF_Range_15 (Range 15)}, transfer-property=PENDING, to P2P
          signal RLObsRng_sech2_SecCAN2_oPDC_SecCH_FrP00_oCAN02: start 39, 4 bit, big-endian, init-value=0, base-type=uint8, compu {0..15=RANGE, 0=Cx0_No_Obstacle (No Obstacle), 1=Cx1_Range_1 (Range 1), 2=Cx2_Range_2 (Range 2), 3=Cx3_Range_3 (Range 3), 4=Cx4_Range_4 (Range 4), 5=Cx5_Range_5 (Range 5), 6=Cx6_Range_6 (Range 6), 7=Cx7_Range_7 (Range 7), 8=Cx8_Range_8 (Range 8), 9=Cx9_Range_9 (Range 9), 10=CxA_Range_10 (Range 10), 11=CxB_Range_11 (Range 11), 12=CxC_Range_12 (Range 12), 13=CxD_Range_13 (Range 13), 14=CxE_Range_14 (Range 14), 15=CxF_Range_15 (Range 15)}, transfer-property=PENDING, to P2P
          signal PDCCofignSts_sech2_SecCAN2_oPDC_SecCH_FrP00_oCAN02: start 42, 3 bit, big-endian, init-value=1, base-type=uint8, compu {0..7=RANGE, 0=Cx0_3_rear_sensors (3 rear sensors), 1=Cx1_4_rear_sensors (4 rear sensors), 2=Cx2_4_rear_sensors_and_2_front_side_sensors (4 rear sensors and 2 front side sensors), 3=Cx3_4_rear_sensors_and_4_front_sensors (4 rear sensors and 4 front sensors), 4=Cx4_2_rear_sensors (2 rear sensors), 5=Cx5_Reserved, 6=Cx6_Reserved, 7=Cx7_Reserved}, transfer-property=PENDING, to P2P
          signal FLObsRng_sech2_SecCAN2_oPDC_SecCH_FrP00_oCAN02: start 47, 4 bit, big-endian, init-value=0, base-type=uint8, compu {0..15=RANGE, 0=Cx0_No_Obstacle (No Obstacle), 1=Cx1_Range_1 (Range 1), 2=Cx2_Range_2 (Range 2), 3=Cx3_Range_3 (Range 3), 4=Cx4_Range_4 (Range 4), 5=Cx5_Range_5 (Range 5), 6=Cx6_Range_6 (Range 6), 7=Cx7_Range_7 (Range 7), 8=Cx8_Range_8 (Range 8), 9=Cx9_Range_9 (Range 9), 10=CxA_Range_10 (Range 10), 11=CxB_Range_11 (Range 11), 12=CxC_Range_12 (Range 12), 13=CxD_Range_13 (Range 13), 14=CxE_Range_14 (Range 14), 15=CxF_Range_15 (Range 15)}, transfer-property=PENDING, to P2P
          signal FrtObsDist_sech2_SecCAN2_oPDC_SecCH_FrP00_oCAN02: start 55, 8 bit, big-endian, init-value=0, base-type=uint8, compu {0..255=RANGE; unit cm}, unit=cm, transfer-property=PENDING, to P2P
          signal RrObsDist_sech2_SecCAN2_oPDC_SecCH_FrP00_oCAN02: start 63, 8 bit, big-endian, init-value=0, base-type=uint8, compu {0..255=RANGE}, transfer-property=PENDING, to P2P
      frame PDC_SecCH_FrP01_oCAN02: id 0x237, to P2P, frame-length=8, can-addressing-mode=STANDARD
        pdu PDC_SecCH_FrP01_oCAN02: length=8, transmission-mode-false-timing=cyclic-timing=time-period=0, transmission-mode-true-timing=cyclic-timing=time-period=0, unused-bit-pattern=0
          signal RRSideObsDist_sech2_SecCAN2_oPDC_SecCH_FrP01_oCAN02: start 0, 9 bit, big-endian, init-value=0, base-type=uint16, compu {0..511=RANGE}, transfer-property=PENDING, to P2P
          signal RLSideObsDist_sech2_SecCAN2_oPDC_SecCH_FrP01_oCAN02: start 16, 9 bit, big-endian, init-value=0, base-type=uint16, compu {0..511=RANGE}, transfer-property=PENDING, to P2P
          signal FRSideObsDist_sech2_SecCAN2_oPDC_SecCH_FrP01_oCAN02: start 32, 9 bit, big-endian, init-value=0, base-type=uint16, compu {0..511=RANGE}, transfer-property=PENDING, to P2P
          signal FLSideObsDist_sech2_SecCAN2_oPDC_SecCH_FrP01_oCAN02: start 48, 9 bit, big-endian, init-value=0, base-type=uint16, compu {0..511=RANGE}, transfer-property=PENDING, to P2P
  lin cluster LIN00: baudrate=19200, protocol-name=LIN, protocol-version=2.0
    lin physical channel CHNL: comm-connectors=CN_LIN00
      frame Init_LRU1_oLIN00: id 0xC1, from P2P, frame-length=1, lin-checksum=ENHANCED
        pdu Init_LRU1_oLIN00: length=1, unused-bit-pattern=255
          signal Sin_Init_LRU1_oInit_LRU1_oLIN00: start 0, 8 bit, little-endian, init-value=0, base-type=uint8, compu {0..255=RANGE}
      frame Init_SRU3_oLIN00: id 0x80, from P2P, frame-length=2, lin-checksum=ENHANCED
        pdu Init_SRU3_oLIN00: length=2, unused-bit-pattern=255
          signal Sig_Init_SRU3_oInit_SRU3_oLIN00: start 0, 16 bit, little-endian, init-value=0, base-type=uint16, compu {0..255=RANGE}
      frame MasterReq_oLIN00: id 0x3C, from P2P, frame-length=8, lin-checksum=CLASSIC
        n pdu MasterReq_Tp_oLIN00: length=8
      frame Read_LRU1_oLIN00: id 0x1F, to P2P, frame-length=8, lin-checksum=ENHANCED
        pdu Read_LRU1_oLIN00: length=8, unused-bit-pattern=255
          signal TOF_LRU1_oRead_LRU1_oLIN00: start 0, 16 bit, little-endian, init-value=0, base-type=uint16, compu {0..65535=RANGE}, to P2P
          signal Peak_LRU1_oRead_LRU1_oLIN00: start 16, 8 bit, little-endian, init-value=0, base-type=uint8, compu {0..255=RANGE}, to P2P
          signal Width_LRU1_oRead_LRU1_oLIN00: start 24, 8 bit, little-endian, init-value=0, base-type=uint8, compu {0..1=RANGE}, to P2P
          signal Status_LRU1_oRead_LRU1_oLIN00: start 48, 8 bit, little-endian, init-value=0, base-type=uint8, compu {0..255=RANGE}, to P2P
      frame Read_SRU3_oLIN00: id 0xD, to P2P, frame-length=3, lin-checksum=ENHANCED
        pdu Read_SRU3_oLIN00: length=3, unused-bit-pattern=255
          signal TOF_SRU3_oRead_SRU3_oLIN00: start 0, 16 bit, little-endian, init-value=0, base-type=uint16, compu {0..127=RANGE}, to P2P
          signal Status_SRU3_oRead_SRU3_oLIN00: start 16, 8 bit, little-endian, init-value=0, base-type=uint8, compu {0..1=RANGE}, to P2P
      frame SlaveResp_oLIN00: id 0x3D, to P2P, frame-length=8, lin-checksum=CLASSIC
        n pdu SlaveResp_Tp_oLIN00: length=8
      pdu triggering PT_MasterReq: pdu=MasterReq_oLIN00, from P2P
      pdu triggering PT_MasterReq_LRU1: pdu=MasterReq_LRU1_oLIN00, from P2P
      pdu triggering PT_MasterReq_SRU3: pdu=MasterReq_SRU3_oLIN00, from P2P
      pdu triggering PT_SlaveResp_LRU1: pdu=SlaveResp_LRU1_oLIN00, to P2P
      pdu triggering PT_SlaveResp_SRU3: pdu=SlaveResp_SRU3_oLIN00, to P2P
      lin schedule table Normal: run-mode=RUN-CONTINUOUS
        table-entrys:
          delay=0.005, position-in-table=0, frame-triggering=FT_Init_SRU3
          delay=0.05, position-in-table=1, frame-triggering=FT_Init_LRU1
          delay=0.02, position-in-table=2, frame-triggering=FT_Read_SRU3
          delay=0.05, position-in-table=3, frame-triggering=FT_Read_LRU1
package /ECU
  ecu instance P2P: associated-com-i-pdu-group=[P2P_oCAN00_Rx, P2P_oCAN00_Tx, P2P_oCAN01_Rx, P2P_oCAN01_Tx, P2P_oCAN02_Rx, P2P_oCAN02_Tx, P2P_oLIN00_Rx, P2P_oLIN00_Tx]
    can communication controller CT_CAN{00..02}
    lin master CT_LIN00: protocol-version=2.0, time-base=0.005, time-base-jitter=0
    can communication connector CN_CAN{00..02}: comm-controller=CT_CAN{00..02}
    lin communication connector CN_LIN00: comm-controller=CT_LIN00
package /Gateway
  gateway P2P: ecu=P2P
package /IPDUGroup
  8 x i signal i pdu group:
    P2P_oCAN00_Rx: communication-direction=IN
      i-signal-i-pdus:
        DIAG_FuncReq_HSC2_oCAN00
        DIAG_PhysReq_P2P_oCAN00
        EHBS_HSC2_FrP00_oCAN00
        EPB_HSC2_FrP00_oCAN00
        EPB_HSC2_FrP01_oCAN00
        EPS_HSC2_FrP02_oCAN00
        GW_HSC2_BCM_FrP04_oCAN00
        GW_HSC2_BCM_FrP06_oCAN00
        GW_HSC2_BCM_FrP07_oCAN00
        GW_HSC2_BCM_FrS16_oCAN00
        GW_HSC2_ECM_FrP04_oCAN00
        GW_HSC2_FICM_FrP02_oCAN00
        GW_HSC2_FICM_FrP08_oCAN00
        GW_HSC2_FrP00_oCAN00
        GW_HSC2_FrP01_oCAN00
        GW_HSC2_FrP08_oCAN00
        GW_HSC2_FrP10_oCAN00
        GW_HSC2_FrP13_oCAN00
        GW_HSC2_FrS00_oCAN00
        GW_HSC2_HCU_FrP00_oCAN00
        GW_HSC2_HCU_FrP01_oCAN00
        GW_HSC2_HCU_FrP13_oCAN00
        GW_HSC2_IPK_FrP06_oCAN00
        GW_HSC2_SCU_FrP00_oCAN00
        GW_HSC2_SDM_FrP00_oCAN00
        SAS_HSC2_FrP00_oCAN00
        SCS_HSC2_FrP{00..03}_oCAN00
        SCS_HSC2_FrP05_oCAN00
        SCS_HSC2_FrP11_oCAN00
        SCS_HSC2_FrP12_oCAN00
        SCS_HSC2_FrP15_oCAN00
        Tester_HSC2_ECM_FrP00_oCAN00
        Tester_HSC2_GW_FrP14_oCAN00
    P2P_oCAN00_Tx: communication-direction=OUT
      i-signal-i-pdus:
        DIAG_DTCInfo_P2P_oCAN00
        DIAG_PhysResp_P2P_oCAN00
        P2P_DIAG_DTCInfo_APA_oCAN00
        P2P_HSC2_FrP{00..04}_oCAN00
        P2P_HSC2_FrS01_oCAN00
    P2P_oCAN01_Rx: communication-direction=IN
      i-signal-i-pdus:
        FICM_HSC4_FrP02_oCAN01
        FICM_HSC4_FrP08_oCAN01
        FICM_HSC4_FrP13_oCAN01
        FICM_HSC4_FrP18_oCAN01
        FICM_HSC4_FrP32_oCAN01
        FICM_HSC4_FrP33_oCAN01
        GW_HSC4_BCM_FrP04_oCAN01
        GW_HSC4_BCM_FrS09_oCAN01
        GW_HSC4_BCM_FrS10_oCAN01
        GW_HSC4_BMS_FrP07_oCAN01
        GW_HSC4_PEPS_FrP01_oCAN01
        GW_HSC4_PEPS_FrP02_oCAN01
        GW_HSC4_TBOX_FrP01_oCAN01
        GW_HSC4_TBOX_FrP05_oCAN01
        GW_HSC4_TBOX_FrS10_oCAN01
        GW_HSC4_TC_FrP01_oCAN01
        IPK_HSC4_FrP06_oCAN01
        RDA_HSC4_P02_oCAN01
        TPMS_HSC3_FrP01_oCAN01
        TPMS_HSC3_FrP02_oCAN01
    P2P_oCAN01_Tx: communication-direction=OUT, i-signal-i-pdus=[P2P_HSC4_FrP03_oCAN01, P2P_HSC4_FrS01_oCAN01, P2P_IECU_HSC4_FrP01_oCAN01, P2P_IECU_HSC4_FrP02_oCAN01]
    P2P_oCAN02_Rx: communication-direction=IN
      i-signal-i-pdus:
        APA_SecCH_FrP{00..04}_oCAN02
        DIAG_DTCInfo_APA_oCAN02
        PDC_SecCH_FrP00_oCAN02
        PDC_SecCH_FrP01_oCAN02
    P2P_oCAN02_Tx: communication-direction=OUT
      i-signal-i-pdus:
        P2P_SecCH_BCM_FrP03_oCAN02
        P2P_SecCH_BCM_FrP04_oCAN02
        P2P_SecCH_BCM_FrP07_oCAN02
        P2P_SecCH_ECM_FrP00_oCAN02
        P2P_SecCH_EPB_FrP00_oCAN02
        P2P_SecCH_EPB_FrP01_oCAN02
        P2P_SecCH_EPS_FrP02_oCAN02
        P2P_SecCH_FICM_FrP02_oCAN02
        P2P_SecCH_FICM_FrP08_oCAN02
        P2P_SecCH_FICM_FrP18_oCAN02
        P2P_SecCH_GW_FrP00_oCAN02
        P2P_SecCH_GW_FrP01_oCAN02
        P2P_SecCH_GW_FrP08_oCAN02
        P2P_SecCH_GW_FrP10_oCAN02
        P2P_SecCH_GW_FrP13_oCAN02
        P2P_SecCH_GW_FrS00_oCAN02
        P2P_SecCH_HCU_ECM_FrP04_oCAN02
        P2P_SecCH_HCU_FrP00_oCAN02
        P2P_SecCH_HCU_FrP01_oCAN02
        P2P_SecCH_HCU_FrP13_oCAN02
        P2P_SecCH_IPK_FrP06_oCAN02
        P2P_SecCH_SAS_FrP00_oCAN02
        P2P_SecCH_SCS_FrP{00..03}_oCAN02
        P2P_SecCH_SCS_FrP05_oCAN02
        P2P_SecCH_SCS_FrP11_oCAN02
        P2P_SecCH_SCS_FrP12_oCAN02
        P2P_SecCH_SCS_FrP15_oCAN02
        P2P_SecCH_SCU_FrP00_oCAN02
        P2P_SecCH_SDM_FrP00_oCAN02
        P2P_SecCH_TC_FrP07_oCAN02
        P2P_SecCH_Tester_GW_FrP14_oCAN02
    P2P_oLIN00_Rx: communication-direction=IN, i-signal-i-pdus=[Read_LRU1_oLIN00, Read_SRU3_oLIN00]
    P2P_oLIN00_Tx: communication-direction=OUT, i-signal-i-pdus=[Init_LRU1_oLIN00, Init_SRU3_oLIN00]
package /PDU
  dcm i pdu MasterReq_LRU1_oLIN00: length=8, diag-pdu-type=DIAG-REQUEST
  dcm i pdu MasterReq_oLIN00: length=8, diag-pdu-type=DIAG-REQUEST
  dcm i pdu MasterReq_SRU3_oLIN00: length=8, diag-pdu-type=DIAG-REQUEST
  dcm i pdu SlaveResp_LRU1_oLIN00: length=8, diag-pdu-type=DIAG-RESPONSE
  dcm i pdu SlaveResp_SRU3_oLIN00: length=8, diag-pdu-type=DIAG-RESPONSE
package /DataType
  base type uint8_7_iso_8859_1: category=FIXED_LENGTH, base-type-size=56, base-type-encoding=ISO-8859-1
  base type uint8_8_iso_8859_1: category=FIXED_LENGTH, base-type-size=64, base-type-encoding=ISO-8859-1
package /DataType/Unit
  18 x unit:
    U_cm: display-name=cm
    U_days: display-name=days
    U_degC: display-name=degC
    U_degree: display-name=degree
    U_degYs: display-name=deg/s
    U_kmYh: display-name=km/h
    U_kPa: display-name=kPa
    U_m: display-name=m
    U_mYs2: display-name=m/s2
    U_mYsX2: display-name=m/s^2
    U_Nm: display-name=Nm
    U_p: display-name=%
    U_Reserve: display-name=Reserve
    U_reserved: display-name=reserved
    U_rpm: display-name=rpm
    U_s: display-name=s
    U_V: display-name=V
    U_year: display-name=year
